VERSION ""

NS_ :

BS_:

BU_: ACCL BGW BLE DBPC DCFL DCFR DCRL DCRR DDP DSM ECPM FBCM FFL FLDC FRDC HLL HLR HUD IHUB LGL PBPC PDP PSM RBCM RCLL RCLR RLDC RLDP RLSM RRDC RRDP RRSM SCAM TOOL IPC u d t

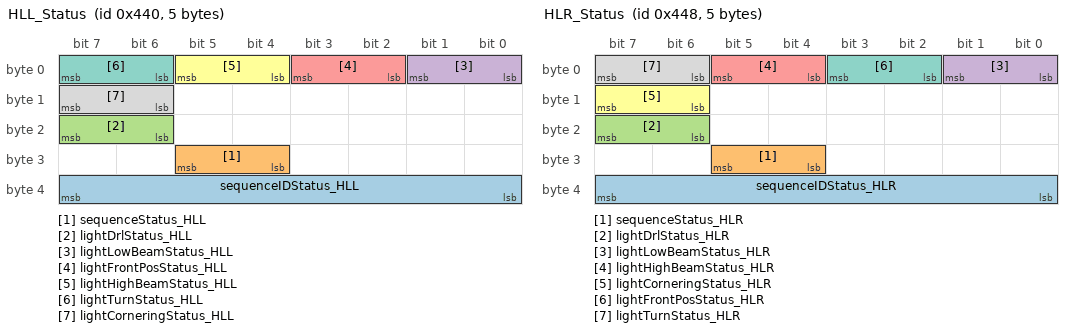
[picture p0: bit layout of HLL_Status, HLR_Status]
BO_ 1088 HLL_Status: 5 HLL
 SG_ sequenceIDStatus_HLL : 39|8@0+ (1,0) [0|254] "" BGW
 SG_ sequenceStatus_HLL : 29|2@0+ (1,0) [0|14] "" BGW
 SG_ lightDrlStatus_HLL : 23|2@0+ (1,0) [0|2] "" HUD,BGW,FBCM
 SG_ lightLowBeamStatus_HLL : 1|2@0+ (1,0) [0|2] "" HUD,FBCM,BGW
 SG_ lightFrontPosStatus_HLL : 3|2@0+ (1,0) [0|2] "" HUD,FBCM,BGW
 SG_ lightHighBeamStatus_HLL : 5|2@0+ (1,0) [0|2] "" HUD,FBCM,BGW
 SG_ lightTurnStatus_HLL : 7|2@0+ (1,0) [0|2] "" HUD,FBCM,BGW
 SG_ lightCorneringStatus_HLL : 15|2@0+ (1,0) [0|2] "" HUD,FBCM,BGW

BO_ 1096 HLR_Status: 5 HLR
 SG_ sequenceIDStatus_HLR : 39|8@0+ (1,0) [0|254] "" BGW
 SG_ sequenceStatus_HLR : 29|2@0+ (1,0) [0|14] "" BGW
 SG_ lightDrlStatus_HLR : 23|2@0+ (1,0) [0|2] "" HUD,BGW,FBCM
 SG_ lightLowBeamStatus_HLR : 1|2@0+ (1,0) [0|2] "" HUD,FBCM,BGW
 SG_ lightHighBeamStatus_HLR : 5|2@0+ (1,0) [0|2] "" HUD,FBCM,BGW
 SG_ lightCorneringStatus_HLR : 15|2@0+ (1,0) [0|2] "" HUD,FBCM,BGW
 SG_ lightFrontPosStatus_HLR : 3|2@0+ (1,0) [0|2] "" HUD,FBCM,BGW
 SG_ lightTurnStatus_HLR : 7|2@0+ (1,0) [0|2] "" HUD,FBCM,BGW

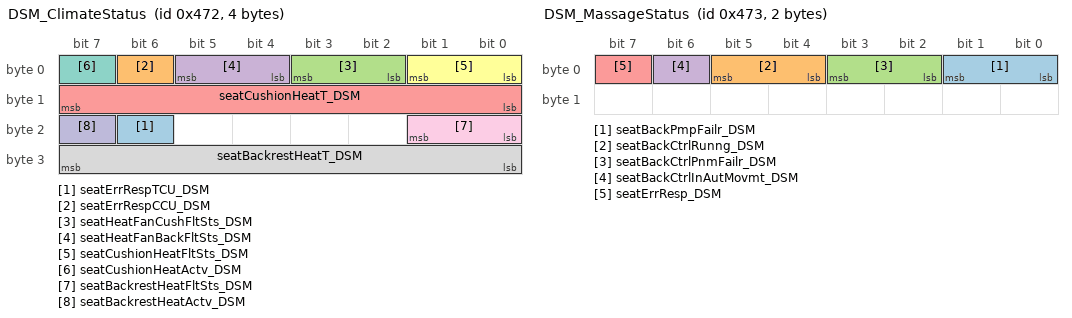
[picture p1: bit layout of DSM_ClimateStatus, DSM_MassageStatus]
BO_ 1138 DSM_ClimateStatus: 4 DSM
 SG_ seatErrRespTCU_DSM : 22|1@0+ (1,0) [0|1] "" BGW
 SG_ seatErrRespCCU_DSM : 6|1@0+ (1,0) [0|1] "" BGW
 SG_ seatHeatFanCushFltSts_DSM : 3|2@0+ (1,0) [0|2] "" BGW
 SG_ seatHeatFanBackFltSts_DSM : 5|2@0+ (1,0) [0|2] "" BGW
 SG_ seatCushionHeatT_DSM : 15|8@0+ (0.5,-40) [0|87] "degC" BGW
 SG_ seatCushionHeatFltSts_DSM : 1|2@0+ (1,0) [0|2] "" BGW
 SG_ seatCushionHeatActv_DSM : 7|1@0+ (1,0) [0|1] "" BGW
 SG_ seatBackrestHeatT_DSM : 31|8@0+ (0.5,-40) [0|87] "degC" BGW
 SG_ seatBackrestHeatFltSts_DSM : 17|2@0+ (1,0) [0|2] "" BGW
 SG_ seatBackrestHeatActv_DSM : 23|1@0+ (1,0) [0|1] "" BGW

BO_ 1139 DSM_MassageStatus: 2 DSM
 SG_ seatBackPmpFailr_DSM : 1|2@0+ (1,0) [0|2] "" BGW
 SG_ seatBackCtrlRunng_DSM : 5|2@0+ (1,0) [0|3] "" BGW
 SG_ seatBackCtrlPnmFailr_DSM : 3|2@0+ (1,0) [0|2] "" BGW
 SG_ seatBackCtrlInAutMovmt_DSM : 6|1@0+ (1,0) [0|1] "" BGW
 SG_ seatErrResp_DSM : 7|1@0+ (1,0) [0|1] "" BGW

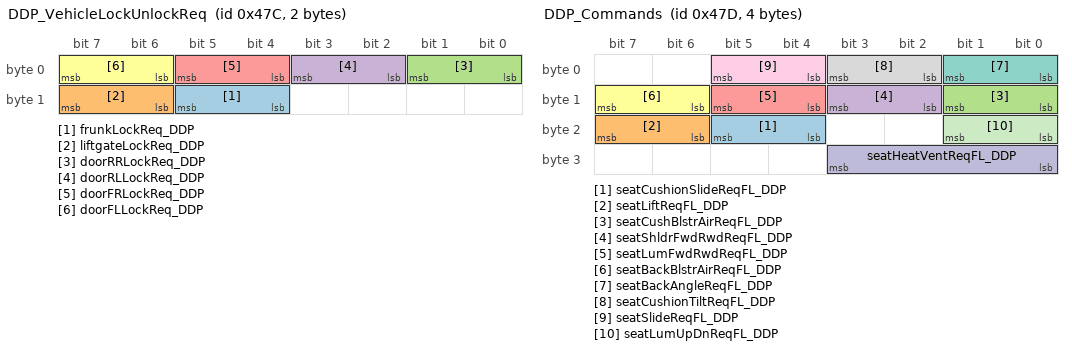
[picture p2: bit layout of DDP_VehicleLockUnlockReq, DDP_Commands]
BO_ 1148 DDP_VehicleLockUnlockReq: 2 DDP
 SG_ frunkLockReq_DDP : 13|2@0+ (1,0) [0|2] "" FBCM
 SG_ liftgateLockReq_DDP : 15|2@0+ (1,0) [0|2] "" FBCM
 SG_ doorRRLockReq_DDP : 1|2@0+ (1,0) [0|2] "" FBCM
 SG_ doorRLLockReq_DDP : 3|2@0+ (1,0) [0|2] "" FBCM
 SG_ doorFRLockReq_DDP : 5|2@0+ (1,0) [0|2] "" FBCM
 SG_ doorFLLockReq_DDP : 7|2@0+ (1,0) [0|2] "" FBCM

BO_ 1149 DDP_Commands: 4 DDP
 SG_ seatCushionSlideReqFL_DDP : 21|2@0+ (1,0) [0|2] "" BGW
 SG_ seatLiftReqFL_DDP : 23|2@0+ (1,0) [0|2] "" BGW
 SG_ seatCushBlstrAirReqFL_DDP : 9|2@0+ (1,0) [0|2] "" BGW
 SG_ seatShldrFwdRwdReqFL_DDP : 11|2@0+ (1,0) [0|2] "" BGW
 SG_ seatLumFwdRwdReqFL_DDP : 13|2@0+ (1,0) [0|2] "" BGW
 SG_ seatBackBlstrAirReqFL_DDP : 15|2@0+ (1,0) [0|2] "" BGW
 SG_ seatBackAngleReqFL_DDP : 1|2@0+ (1,0) [0|2] "" BGW
 SG_ seatCushionTiltReqFL_DDP : 3|2@0+ (1,0) [0|2] "" BGW
 SG_ seatSlideReqFL_DDP : 5|2@0+ (1,0) [0|2] "" BGW
 SG_ seatHeatVentReqFL_DDP : 27|4@0+ (1,0) [0|8] "" BGW
 SG_ seatLumUpDnReqFL_DDP : 17|2@0+ (1,0) [0|2] "" BGW

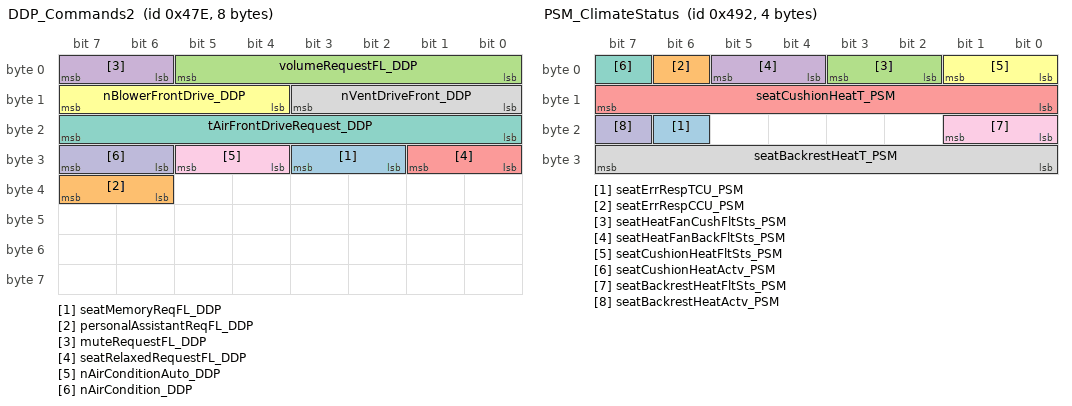
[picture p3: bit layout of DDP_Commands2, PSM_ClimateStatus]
BO_ 1150 DDP_Commands2: 8 DDP
 SG_ seatMemoryReqFL_DDP : 27|2@0+ (1,0) [0|2] "" BGW
 SG_ personalAssistantReqFL_DDP : 39|2@0+ (1,0) [0|2] "" BGW
 SG_ volumeRequestFL_DDP : 5|6@0+ (1,0) [0|45] "" BGW
 SG_ muteRequestFL_DDP : 7|2@0+ (1,0) [0|2] "" BGW
 SG_ seatRelaxedRequestFL_DDP : 25|2@0+ (1,0) [0|2] "" BGW
 SG_ nBlowerFrontDrive_DDP : 15|4@0+ (1,0) [0|14] "" BGW
 SG_ tAirFrontDriveRequest_DDP : 23|8@0+ (0.1,15.5) [15.5|32.5] "C" BGW
 SG_ nVentDriveFront_DDP : 11|4@0+ (1,0) [0|12] "" BGW
 SG_ nAirConditionAuto_DDP : 29|2@0+ (1,0) [0|2] "" BGW
 SG_ nAirCondition_DDP : 31|2@0+ (1,0) [0|2] "" BGW

BO_ 1170 PSM_ClimateStatus: 4 PSM
 SG_ seatErrRespTCU_PSM : 22|1@0+ (1,0) [0|1] "" BGW
 SG_ seatErrRespCCU_PSM : 6|1@0+ (1,0) [0|1] "" BGW
 SG_ seatHeatFanCushFltSts_PSM : 3|2@0+ (1,0) [0|2] "" BGW
 SG_ seatHeatFanBackFltSts_PSM : 5|2@0+ (1,0) [0|2] "" BGW
 SG_ seatCushionHeatT_PSM : 15|8@0+ (0.5,-40) [0|87] "degC" BGW
 SG_ seatCushionHeatFltSts_PSM : 1|2@0+ (1,0) [0|2] "" BGW
 SG_ seatCushionHeatActv_PSM : 7|1@0+ (1,0) [0|1] "" BGW
 SG_ seatBackrestHeatT_PSM : 31|8@0+ (0.5,-40) [0|87] "degC" BGW
 SG_ seatBackrestHeatFltSts_PSM : 17|2@0+ (1,0) [0|2] "" BGW
 SG_ seatBackrestHeatActv_PSM : 23|1@0+ (1,0) [0|1] "" BGW

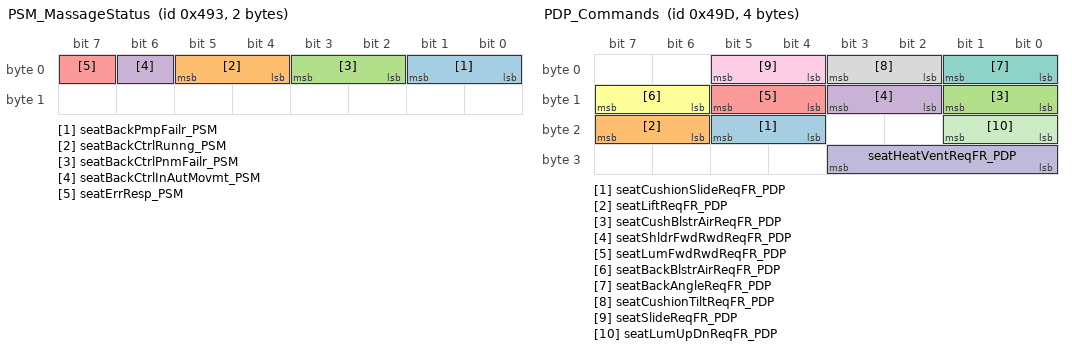
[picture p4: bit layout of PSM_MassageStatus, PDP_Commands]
BO_ 1171 PSM_MassageStatus: 2 PSM
 SG_ seatBackPmpFailr_PSM : 1|2@0+ (1,0) [0|2] "" BGW
 SG_ seatBackCtrlRunng_PSM : 5|2@0+ (1,0) [0|3] "" BGW
 SG_ seatBackCtrlPnmFailr_PSM : 3|2@0+ (1,0) [0|2] "" BGW
 SG_ seatBackCtrlInAutMovmt_PSM : 6|1@0+ (1,0) [0|1] "" BGW
 SG_ seatErrResp_PSM : 7|1@0+ (1,0) [0|1] "" BGW

BO_ 1176 PDP_VehicleLockUnlockReq: 1 PDP
 SG_ doorFRLockReq_PDP : 7|2@0+ (1,0) [0|2] "" FBCM

BO_ 1181 PDP_Commands: 4 PDP
 SG_ seatCushionSlideReqFR_PDP : 21|2@0+ (1,0) [0|2] "" BGW
 SG_ seatLiftReqFR_PDP : 23|2@0+ (1,0) [0|2] "" BGW
 SG_ seatCushBlstrAirReqFR_PDP : 9|2@0+ (1,0) [0|2] "" BGW
 SG_ seatShldrFwdRwdReqFR_PDP : 11|2@0+ (1,0) [0|2] "" BGW
 SG_ seatLumFwdRwdReqFR_PDP : 13|2@0+ (1,0) [0|2] "" BGW
 SG_ seatBackBlstrAirReqFR_PDP : 15|2@0+ (1,0) [0|2] "" BGW
 SG_ seatBackAngleReqFR_PDP : 1|2@0+ (1,0) [0|2] "" BGW
 SG_ seatCushionTiltReqFR_PDP : 3|2@0+ (1,0) [0|2] "" BGW
 SG_ seatSlideReqFR_PDP : 5|2@0+ (1,0) [0|2] "" BGW
 SG_ seatHeatVentReqFR_PDP : 27|4@0+ (1,0) [0|8] "" BGW
 SG_ seatLumUpDnReqFR_PDP : 17|2@0+ (1,0) [0|2] "" BGW

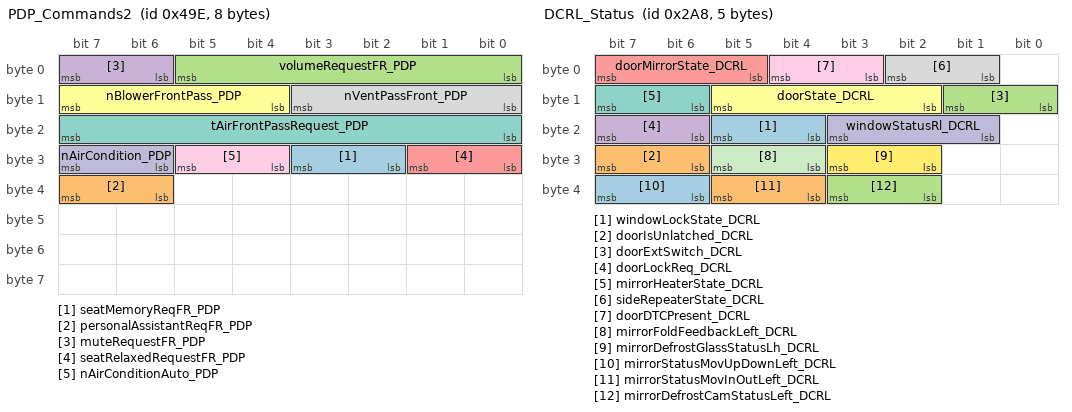
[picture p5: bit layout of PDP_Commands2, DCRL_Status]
BO_ 1182 PDP_Commands2: 8 PDP
 SG_ seatMemoryReqFR_PDP : 27|2@0+ (1,0) [0|2] "" BGW
 SG_ personalAssistantReqFR_PDP : 39|2@0+ (1,0) [0|2] "" BGW
 SG_ volumeRequestFR_PDP : 5|6@0+ (1,0) [0|45] "" BGW
 SG_ muteRequestFR_PDP : 7|2@0+ (1,0) [0|2] "" BGW
 SG_ seatRelaxedRequestFR_PDP : 25|2@0+ (1,0) [0|2] "" BGW
 SG_ nBlowerFrontPass_PDP : 15|4@0+ (1,0) [0|14] "" BGW
 SG_ tAirFrontPassRequest_PDP : 23|8@0+ (0.1,15.5) [15.5|32.5] "C" BGW
 SG_ nVentPassFront_PDP : 11|4@0+ (1,0) [0|12] "" BGW
 SG_ nAirConditionAuto_PDP : 29|2@0+ (1,0) [0|2] "" BGW
 SG_ nAirCondition_PDP : 31|2@0+ (1,0) [0|2] "" BGW

BO_ 680 DCRL_Status: 5 DCRL
 SG_ windowLockState_DCRL : 21|2@0+ (1,0) [0|2] "" BGW,DCFL,DCFR,DCRL,DCRR
 SG_ doorIsUnlatched_DCRL : 31|2@0+ (1,0) [0|2] "" FBCM,BGW,DCFR,DCRR,DCFL,IHUB
 SG_ doorExtSwitch_DCRL : 9|2@0+ (1,0) [0|2] "" BGW
 SG_ doorLockReq_DCRL : 23|2@0+ (1,0) [0|2] "" BGW
 SG_ doorMirrorState_DCRL : 7|3@0+ (1,0) [0|6] "" ECPM,BGW
 SG_ doorState_DCRL : 13|4@0+ (1,0) [0|6] "" ECPM,RBCM,FBCM,BGW
 SG_ mirrorHeaterState_DCRL : 15|2@0+ (1,0) [0|2] "" ECPM,BGW
 SG_ sideRepeaterState_DCRL : 2|2@0+ (1,0) [0|2] "" BGW,RBCM
 SG_ doorDTCPresent_DCRL : 4|2@0+ (1,0) [0|2] "" BGW
 SG_ windowStatusRl_DCRL : 19|3@0+ (1,0) [0|6] "" BGW
 SG_ mirrorFoldFeedbackLeft_DCRL : 29|2@0+ (1,0) [0|2] "" BGW
 SG_ mirrorDefrostGlassStatusLh_DCRL : 27|2@0+ (1,0) [0|2] "" BGW
 SG_ mirrorStatusMovUpDownLeft_DCRL : 39|2@0+ (1,0) [0|2] "" BGW
 SG_ mirrorStatusMovInOutLeft_DCRL : 37|2@0+ (1,0) [0|2] "" BGW
 SG_ mirrorDefrostCamStatusLeft_DCRL : 35|2@0+ (1,0) [0|2] "" BGW

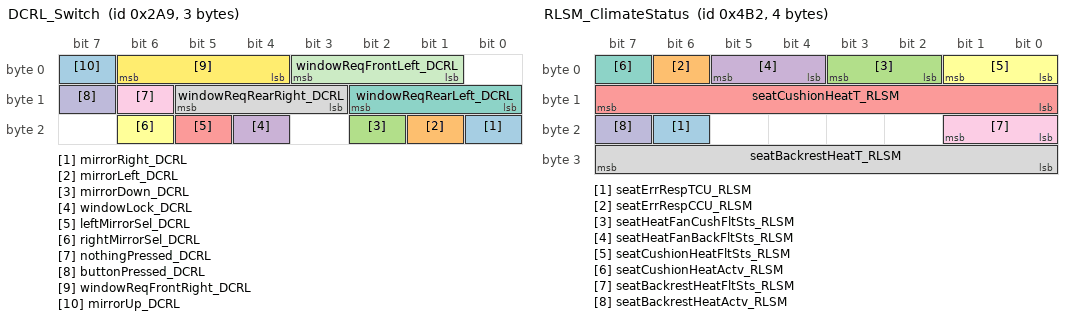
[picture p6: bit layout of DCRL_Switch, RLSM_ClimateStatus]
BO_ 681 DCRL_Switch: 3 DCRL
 SG_ mirrorRight_DCRL : 16|1@0+ (1,0) [0|1] "" DCRR,DCRL,DCFR,DCFL,TOOL
 SG_ mirrorLeft_DCRL : 17|1@0+ (1,0) [0|1] "" DCRR,DCRL,DCFR,DCFL,TOOL
 SG_ mirrorDown_DCRL : 18|1@0+ (1,0) [0|1] "" DCRR,DCRL,DCFR,DCFL,TOOL
 SG_ windowLock_DCRL : 20|1@0+ (1,0) [0|1] "" DCRR,DCRL,DCFR,DCFL,TOOL
 SG_ leftMirrorSel_DCRL : 21|1@0+ (1,0) [0|1] "" DCRR,DCRL,DCFR,DCFL,TOOL
 SG_ rightMirrorSel_DCRL : 22|1@0+ (1,0) [0|1] "" DCRR,DCRL,DCFR,DCFL,TOOL
 SG_ windowReqRearLeft_DCRL : 10|3@0+ (1,0) [0|6] "" DCFR,DCRR,DCFL,DCRL,BGW,TOOL
 SG_ windowReqRearRight_DCRL : 13|3@0+ (1,0) [0|6] "" DCRL,DCFR,DCFL,DCRR,BGW,TOOL
 SG_ nothingPressed_DCRL : 14|1@0+ (1,0) [0|1] "" DCFR,DCRL,DCRR,DCFL,TOOL
 SG_ buttonPressed_DCRL : 15|1@0+ (1,0) [0|1] "" DCFR,DCRL,DCRR,DCFL,TOOL
 SG_ windowReqFrontLeft_DCRL : 3|3@0+ (1,0) [0|6] "" DCFR,DCRL,DCRR,DCFL,BGW
 SG_ windowReqFrontRight_DCRL : 6|3@0+ (1,0) [0|6] "" DCFR,DCRL,DCRR,DCFL,BGW,TOOL
 SG_ mirrorUp_DCRL : 7|1@0+ (1,0) [0|1] "" DCRR,DCRL,DCFR,DCFL,TOOL

BO_ 1202 RLSM_ClimateStatus: 4 RLSM
 SG_ seatErrRespTCU_RLSM : 22|1@0+ (1,0) [0|1] "" BGW
 SG_ seatErrRespCCU_RLSM : 6|1@0+ (1,0) [0|1] "" BGW
 SG_ seatHeatFanCushFltSts_RLSM : 3|2@0+ (1,0) [0|2] "" BGW
 SG_ seatHeatFanBackFltSts_RLSM : 5|2@0+ (1,0) [0|2] "" BGW
 SG_ seatCushionHeatT_RLSM : 15|8@0+ (0.5,-40) [0|87] "degC" BGW
 SG_ seatCushionHeatFltSts_RLSM : 1|2@0+ (1,0) [0|2] "" BGW
 SG_ seatCushionHeatActv_RLSM : 7|1@0+ (1,0) [0|1] "" BGW
 SG_ seatBackrestHeatT_RLSM : 31|8@0+ (0.5,-40) [0|87] "degC" BGW
 SG_ seatBackrestHeatFltSts_RLSM : 17|2@0+ (1,0) [0|2] "" BGW
 SG_ seatBackrestHeatActv_RLSM : 23|1@0+ (1,0) [0|1] "" BGW

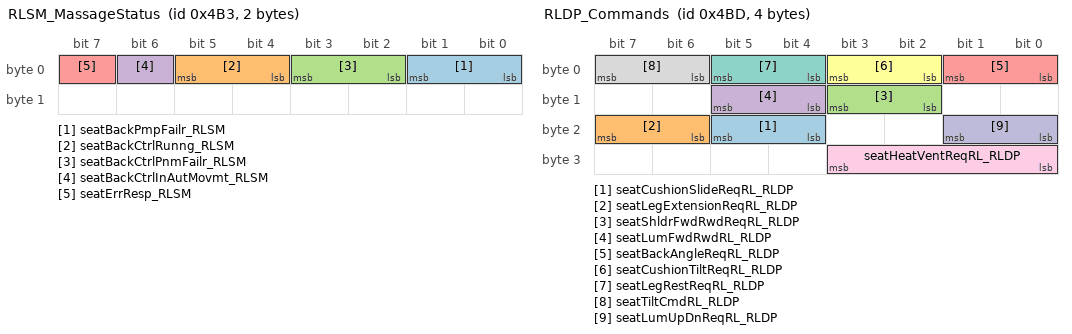
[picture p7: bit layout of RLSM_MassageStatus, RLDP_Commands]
BO_ 1203 RLSM_MassageStatus: 2 RLSM
 SG_ seatBackPmpFailr_RLSM : 1|2@0+ (1,0) [0|2] "" BGW
 SG_ seatBackCtrlRunng_RLSM : 5|2@0+ (1,0) [0|3] "" BGW
 SG_ seatBackCtrlPnmFailr_RLSM : 3|2@0+ (1,0) [0|2] "" BGW
 SG_ seatBackCtrlInAutMovmt_RLSM : 6|1@0+ (1,0) [0|1] "" BGW
 SG_ seatErrResp_RLSM : 7|1@0+ (1,0) [0|1] "" BGW

BO_ 1208 RLDP_VehicleLockUnlockReq: 1 RLDP
 SG_ doorRLLockReq_RLDP : 7|2@0+ (1,0) [0|2] "" FBCM

BO_ 1213 RLDP_Commands: 4 RLDP
 SG_ seatCushionSlideReqRL_RLDP : 21|2@0+ (1,0) [0|2] "" BGW
 SG_ seatLegExtensionReqRL_RLDP : 23|2@0+ (1,0) [0|2] "" BGW
 SG_ seatShldrFwdRwdReqRL_RLDP : 11|2@0+ (1,0) [0|2] "" BGW
 SG_ seatLumFwdRwdRL_RLDP : 13|2@0+ (1,0) [0|2] "" BGW
 SG_ seatBackAngleReqRL_RLDP : 1|2@0+ (1,0) [0|2] "" BGW
 SG_ seatCushionTiltReqRL_RLDP : 3|2@0+ (1,0) [0|2] "" BGW
 SG_ seatLegRestReqRL_RLDP : 5|2@0+ (1,0) [0|2] "" BGW
 SG_ seatTiltCmdRL_RLDP : 7|2@0+ (1,0) [0|2] "" BGW
 SG_ seatHeatVentReqRL_RLDP : 27|4@0+ (1,0) [0|8] "" BGW
 SG_ seatLumUpDnReqRL_RLDP : 17|2@0+ (1,0) [0|2] "" BGW

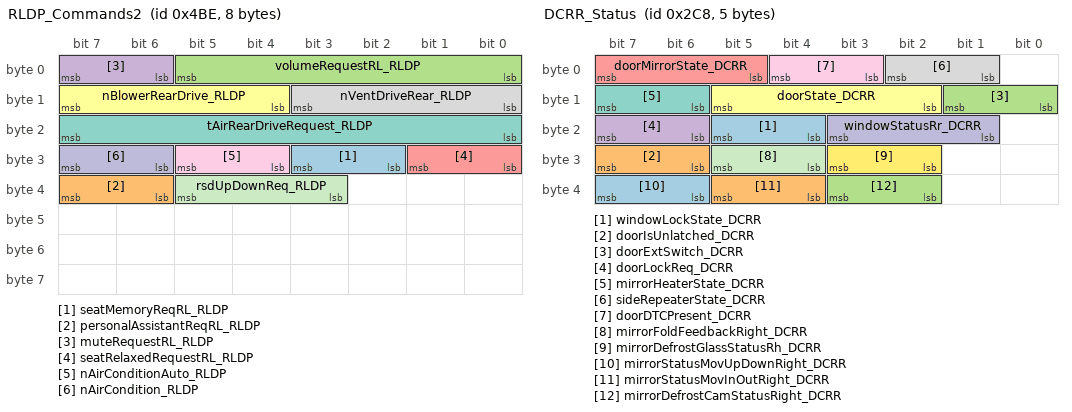
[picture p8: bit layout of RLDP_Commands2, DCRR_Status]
BO_ 1214 RLDP_Commands2: 8 RLDP
 SG_ seatMemoryReqRL_RLDP : 27|2@0+ (1,0) [0|2] "" BGW
 SG_ personalAssistantReqRL_RLDP : 39|2@0+ (1,0) [0|2] "" BGW
 SG_ volumeRequestRL_RLDP : 5|6@0+ (1,0) [0|45] "" BGW
 SG_ muteRequestRL_RLDP : 7|2@0+ (1,0) [0|2] "" BGW
 SG_ seatRelaxedRequestRL_RLDP : 25|2@0+ (1,0) [0|2] "" BGW
 SG_ nBlowerRearDrive_RLDP : 15|4@0+ (1,0) [0|14] "" BGW
 SG_ tAirRearDriveRequest_RLDP : 23|8@0+ (0.1,15.5) [15.5|32.5] "C" BGW
 SG_ nVentDriveRear_RLDP : 11|4@0+ (1,0) [0|12] "" BGW
 SG_ nAirConditionAuto_RLDP : 29|2@0+ (1,0) [0|2] "" BGW
 SG_ nAirCondition_RLDP : 31|2@0+ (1,0) [0|2] "" BGW
 SG_ rsdUpDownReq_RLDP : 37|3@0+ (1,0) [0|6] "" BGW

BO_ 712 DCRR_Status: 5 DCRR
 SG_ windowLockState_DCRR : 21|2@0+ (1,0) [0|2] "" BGW,DCFL,DCFR,DCRL,DCRR
 SG_ doorIsUnlatched_DCRR : 31|2@0+ (1,0) [0|2] "" FBCM,BGW,DCFR,DCFL,DCRL,IHUB
 SG_ doorExtSwitch_DCRR : 9|2@0+ (1,0) [0|2] "" BGW
 SG_ doorLockReq_DCRR : 23|2@0+ (1,0) [0|2] "" BGW
 SG_ doorMirrorState_DCRR : 7|3@0+ (1,0) [0|6] "" ECPM,BGW
 SG_ doorState_DCRR : 13|4@0+ (1,0) [0|6] "" ECPM,RBCM,FBCM,BGW
 SG_ mirrorHeaterState_DCRR : 15|2@0+ (1,0) [0|2] "" ECPM,BGW
 SG_ sideRepeaterState_DCRR : 2|2@0+ (1,0) [0|2] "" BGW,RBCM
 SG_ doorDTCPresent_DCRR : 4|2@0+ (1,0) [0|2] "" BGW
 SG_ windowStatusRr_DCRR : 19|3@0+ (1,0) [0|6] "" BGW
 SG_ mirrorFoldFeedbackRight_DCRR : 29|2@0+ (1,0) [0|2] "" BGW
 SG_ mirrorDefrostGlassStatusRh_DCRR : 27|2@0+ (1,0) [0|2] "" BGW
 SG_ mirrorStatusMovUpDownRight_DCRR : 39|2@0+ (1,0) [0|2] "" BGW
 SG_ mirrorStatusMovInOutRight_DCRR : 37|2@0+ (1,0) [0|2] "" BGW
 SG_ mirrorDefrostCamStatusRight_DCRR : 35|2@0+ (1,0) [0|2] "" BGW

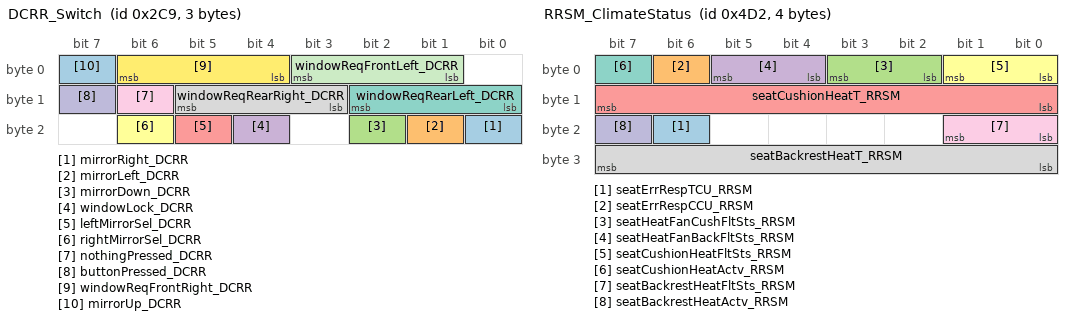
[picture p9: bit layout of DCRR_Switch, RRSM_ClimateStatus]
BO_ 713 DCRR_Switch: 3 DCRR
 SG_ mirrorRight_DCRR : 16|1@0+ (1,0) [0|1] "" DCRR,DCRL,DCFR,DCFL,TOOL
 SG_ mirrorLeft_DCRR : 17|1@0+ (1,0) [0|1] "" DCRR,DCRL,DCFR,DCFL,TOOL
 SG_ mirrorDown_DCRR : 18|1@0+ (1,0) [0|1] "" DCRR,DCRL,DCFR,DCFL,TOOL
 SG_ windowLock_DCRR : 20|1@0+ (1,0) [0|1] "" DCRR,DCRL,DCFR,DCFL,TOOL
 SG_ leftMirrorSel_DCRR : 21|1@0+ (1,0) [0|1] "" DCRR,DCRL,DCFR,DCFL,TOOL
 SG_ rightMirrorSel_DCRR : 22|1@0+ (1,0) [0|1] "" DCRR,DCRL,DCFR,DCFL,TOOL
 SG_ windowReqRearLeft_DCRR : 10|3@0+ (1,0) [0|6] "" DCFR,DCRR,DCFL,DCRL
 SG_ windowReqRearRight_DCRR : 13|3@0+ (1,0) [0|6] "" DCRL,DCFR,DCFL,DCRR,BGW
 SG_ nothingPressed_DCRR : 14|1@0+ (1,0) [0|1] "" DCFR,DCRL,DCRR,DCFL,TOOL
 SG_ buttonPressed_DCRR : 15|1@0+ (1,0) [0|1] "" DCFR,DCRL,DCRR,DCFL,TOOL
 SG_ windowReqFrontLeft_DCRR : 3|3@0+ (1,0) [0|6] "" DCFR,DCRL,DCRR,DCFL,BGW
 SG_ windowReqFrontRight_DCRR : 6|3@0+ (1,0) [0|6] "" DCFR,DCRL,DCRR,DCFL,BGW,TOOL
 SG_ mirrorUp_DCRR : 7|1@0+ (1,0) [0|1] "" DCRR,DCRL,DCFR,DCFL,TOOL

BO_ 1234 RRSM_ClimateStatus: 4 RRSM
 SG_ seatErrRespTCU_RRSM : 22|1@0+ (1,0) [0|1] "" BGW
 SG_ seatErrRespCCU_RRSM : 6|1@0+ (1,0) [0|1] "" BGW
 SG_ seatHeatFanCushFltSts_RRSM : 3|2@0+ (1,0) [0|2] "" BGW
 SG_ seatHeatFanBackFltSts_RRSM : 5|2@0+ (1,0) [0|2] "" BGW
 SG_ seatCushionHeatT_RRSM : 15|8@0+ (0.5,-40) [0|87] "degC" BGW
 SG_ seatCushionHeatFltSts_RRSM : 1|2@0+ (1,0) [0|2] "" BGW
 SG_ seatCushionHeatActv_RRSM : 7|1@0+ (1,0) [0|1] "" BGW
 SG_ seatBackrestHeatT_RRSM : 31|8@0+ (0.5,-40) [0|87] "degC" BGW
 SG_ seatBackrestHeatFltSts_RRSM : 17|2@0+ (1,0) [0|2] "" BGW
 SG_ seatBackrestHeatActv_RRSM : 23|1@0+ (1,0) [0|1] "" BGW

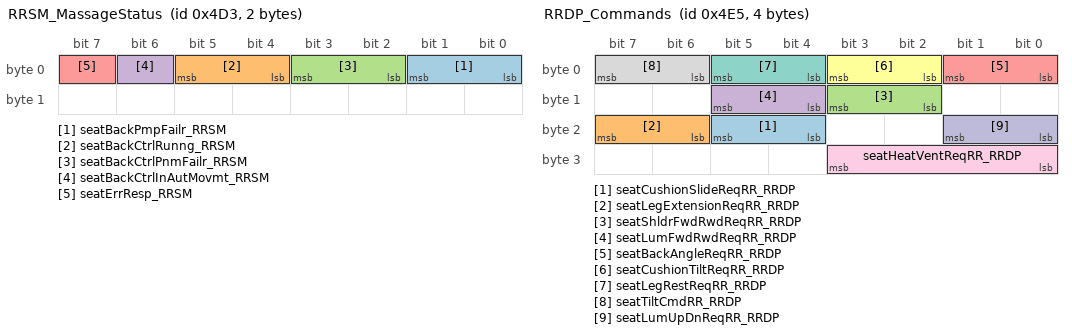
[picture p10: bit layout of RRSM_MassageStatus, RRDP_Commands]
BO_ 1235 RRSM_MassageStatus: 2 RRSM
 SG_ seatBackPmpFailr_RRSM : 1|2@0+ (1,0) [0|2] "" BGW
 SG_ seatBackCtrlRunng_RRSM : 5|2@0+ (1,0) [0|3] "" BGW
 SG_ seatBackCtrlPnmFailr_RRSM : 3|2@0+ (1,0) [0|2] "" BGW
 SG_ seatBackCtrlInAutMovmt_RRSM : 6|1@0+ (1,0) [0|1] "" BGW
 SG_ seatErrResp_RRSM : 7|1@0+ (1,0) [0|1] "" BGW

BO_ 1248 RRDP_VehicleLockUnlockReq: 1 RRDP
 SG_ doorRRLockReq_RRDP : 7|2@0+ (1,0) [0|2] "" FBCM

BO_ 1253 RRDP_Commands: 4 RRDP
 SG_ seatCushionSlideReqRR_RRDP : 21|2@0+ (1,0) [0|2] "" BGW
 SG_ seatLegExtensionReqRR_RRDP : 23|2@0+ (1,0) [0|2] "" BGW
 SG_ seatShldrFwdRwdReqRR_RRDP : 11|2@0+ (1,0) [0|2] "" BGW
 SG_ seatLumFwdRwdReqRR_RRDP : 13|2@0+ (1,0) [0|2] "" BGW
 SG_ seatBackAngleReqRR_RRDP : 1|2@0+ (1,0) [0|2] "" BGW
 SG_ seatCushionTiltReqRR_RRDP : 3|2@0+ (1,0) [0|2] "" BGW
 SG_ seatLegRestReqRR_RRDP : 5|2@0+ (1,0) [0|2] "" BGW
 SG_ seatTiltCmdRR_RRDP : 7|2@0+ (1,0) [0|2] "" BGW
 SG_ seatHeatVentReqRR_RRDP : 27|4@0+ (1,0) [0|8] "" BGW
 SG_ seatLumUpDnReqRR_RRDP : 17|2@0+ (1,0) [0|2] "" BGW

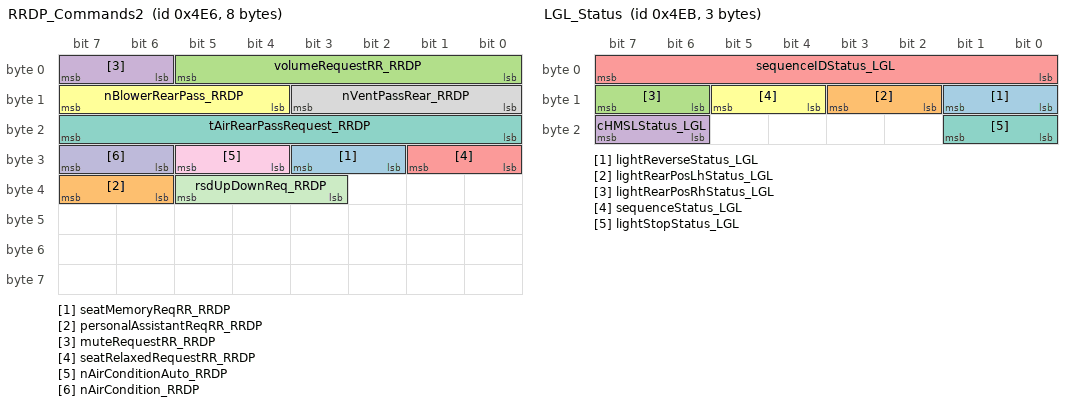
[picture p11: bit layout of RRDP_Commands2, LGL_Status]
BO_ 1254 RRDP_Commands2: 8 RRDP
 SG_ seatMemoryReqRR_RRDP : 27|2@0+ (1,0) [0|2] "" BGW
 SG_ personalAssistantReqRR_RRDP : 39|2@0+ (1,0) [0|2] "" BGW
 SG_ volumeRequestRR_RRDP : 5|6@0+ (1,0) [0|45] "" BGW
 SG_ muteRequestRR_RRDP : 7|2@0+ (1,0) [0|2] "" BGW
 SG_ seatRelaxedRequestRR_RRDP : 25|2@0+ (1,0) [0|2] "" BGW
 SG_ nBlowerRearPass_RRDP : 15|4@0+ (1,0) [0|14] "" BGW
 SG_ tAirRearPassRequest_RRDP : 23|8@0+ (0.1,15.5) [15.5|32.5] "C" BGW
 SG_ nVentPassRear_RRDP : 11|4@0+ (1,0) [0|12] "" BGW
 SG_ nAirConditionAuto_RRDP : 29|2@0+ (1,0) [0|2] "" BGW
 SG_ nAirCondition_RRDP : 31|2@0+ (1,0) [0|2] "" BGW
 SG_ rsdUpDownReq_RRDP : 37|3@0+ (1,0) [0|6] "" BGW

BO_ 1259 LGL_Status: 3 LGL
 SG_ lightReverseStatus_LGL : 9|2@0+ (1,0) [0|2] "" HUD,BGW,FBCM
 SG_ lightRearPosLhStatus_LGL : 11|2@0+ (1,0) [0|2] "" HUD,BGW,FBCM
 SG_ lightRearPosRhStatus_LGL : 15|2@0+ (1,0) [0|2] "" HUD,BGW,FBCM
 SG_ cHMSLStatus_LGL : 23|2@0+ (1,0) [0|2] "" BGW
 SG_ sequenceIDStatus_LGL : 7|8@0+ (1,0) [0|254] "" BGW
 SG_ sequenceStatus_LGL : 13|2@0+ (1,0) [0|14] "" BGW
 SG_ lightStopStatus_LGL : 17|2@0+ (1,0) [0|2] "" HUD,BGW,FBCM

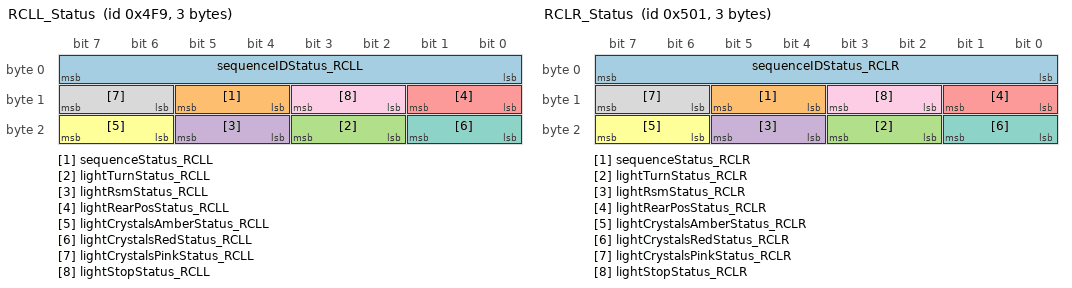
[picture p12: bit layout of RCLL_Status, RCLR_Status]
BO_ 1273 RCLL_Status: 3 RCLL
 SG_ sequenceIDStatus_RCLL : 7|8@0+ (1,0) [0|254] "" BGW
 SG_ sequenceStatus_RCLL : 13|2@0+ (1,0) [0|14] "" BGW
 SG_ lightTurnStatus_RCLL : 19|2@0+ (1,0) [0|2] "" BGW,FBCM
 SG_ lightRsmStatus_RCLL : 21|2@0+ (1,0) [0|2] "" HUD,BGW,FBCM
 SG_ lightRearPosStatus_RCLL : 9|2@0+ (1,0) [0|2] "" HUD,BGW,FBCM
 SG_ lightCrystalsAmberStatus_RCLL : 23|2@0+ (1,0) [0|2] "" HUD,BGW,FBCM
 SG_ lightCrystalsRedStatus_RCLL : 17|2@0+ (1,0) [0|2] "" HUD,BGW,FBCM
 SG_ lightCrystalsPinkStatus_RCLL : 15|2@0+ (1,0) [0|2] "" HUD,BGW,FBCM
 SG_ lightStopStatus_RCLL : 11|2@0+ (1,0) [0|2] "" BGW,FBCM

BO_ 1281 RCLR_Status: 3 RCLR
 SG_ sequenceIDStatus_RCLR : 7|8@0+ (1,0) [0|254] "" BGW
 SG_ sequenceStatus_RCLR : 13|2@0+ (1,0) [0|14] "" BGW
 SG_ lightTurnStatus_RCLR : 19|2@0+ (1,0) [0|2] "" BGW,FBCM
 SG_ lightRsmStatus_RCLR : 21|2@0+ (1,0) [0|2] "" HUD,BGW,FBCM
 SG_ lightRearPosStatus_RCLR : 9|2@0+ (1,0) [0|2] "" HUD,BGW,FBCM
 SG_ lightCrystalsAmberStatus_RCLR : 23|2@0+ (1,0) [0|2] "" HUD,BGW,FBCM
 SG_ lightCrystalsRedStatus_RCLR : 17|2@0+ (1,0) [0|2] "" HUD,BGW,FBCM
 SG_ lightCrystalsPinkStatus_RCLR : 15|2@0+ (1,0) [0|2] "" HUD,BGW,FBCM
 SG_ lightStopStatus_RCLR : 11|2@0+ (1,0) [0|2] "" BGW,FBCM

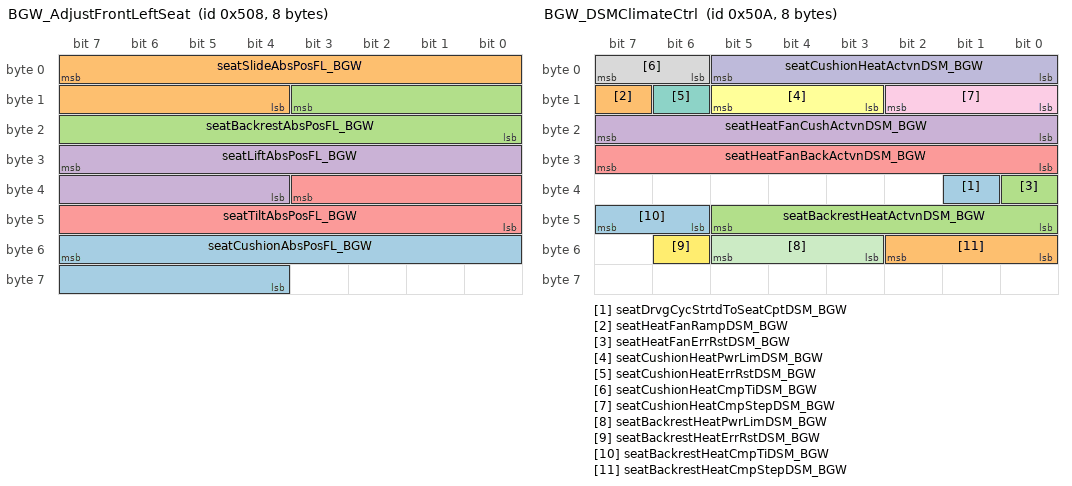
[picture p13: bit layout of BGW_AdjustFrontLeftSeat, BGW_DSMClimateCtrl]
BO_ 1288 BGW_AdjustFrontLeftSeat: 8 BGW
 SG_ seatCushionAbsPosFL_BGW : 55|12@0- (16,0) [-32768|32736] "" DSM
 SG_ seatSlideAbsPosFL_BGW : 7|12@0- (16,0) [-32768|32736] "" DSM
 SG_ seatBackrestAbsPosFL_BGW : 11|12@0- (16,0) [-32768|32736] "" DSM
 SG_ seatLiftAbsPosFL_BGW : 31|12@0- (16,0) [-32768|32736] "" DSM
 SG_ seatTiltAbsPosFL_BGW : 35|12@0- (16,0) [-32768|32736] "" DSM

BO_ 1289 BGW_GoToAbsPositionCushDSM: 2 BGW
 SG_ seatCushionAbsPosDSM_BGW : 7|16@0- (1,0) [-32768|32766] "" DSM

BO_ 1290 BGW_DSMClimateCtrl: 8 BGW
 SG_ seatDrvgCycStrtdToSeatCptDSM_BGW : 33|1@0+ (1,0) [0|1] "" DSM
 SG_ seatHeatFanRampDSM_BGW : 15|1@0+ (1,0) [0|1] "" DSM
 SG_ seatHeatFanErrRstDSM_BGW : 32|1@0+ (1,0) [0|1] "" DSM
 SG_ seatHeatFanCushActvnDSM_BGW : 23|8@0+ (1,0) [0|254] "Rpm" DSM
 SG_ seatHeatFanBackActvnDSM_BGW : 31|8@0+ (1,0) [0|254] "Rpm" DSM
 SG_ seatCushionHeatPwrLimDSM_BGW : 13|3@0+ (1,0) [0|6] "degC" DSM
 SG_ seatCushionHeatErrRstDSM_BGW : 14|1@0+ (1,0) [0|1] "" DSM
 SG_ seatCushionHeatCmpTiDSM_BGW : 7|2@0+ (80,80) [80|240] "s" DSM
 SG_ seatCushionHeatCmpStepDSM_BGW : 10|3@0+ (1,0) [0|6] "degC" DSM
 SG_ seatCushionHeatActvnDSM_BGW : 5|6@0+ (1,19) [19|40] "degC" DSM
 SG_ seatBackrestHeatPwrLimDSM_BGW : 53|3@0+ (1,0) [0|6] "degC" DSM
 SG_ seatBackrestHeatErrRstDSM_BGW : 54|1@0+ (1,0) [0|1] "" DSM
 SG_ seatBackrestHeatCmpTiDSM_BGW : 47|2@0+ (80,80) [80|240] "s" DSM
 SG_ seatBackrestHeatCmpStepDSM_BGW : 50|3@0+ (1,0) [0|6] "degC" DSM
 SG_ seatBackrestHeatActvnDSM_BGW : 45|6@0+ (1,19) [19|40] "degC" DSM

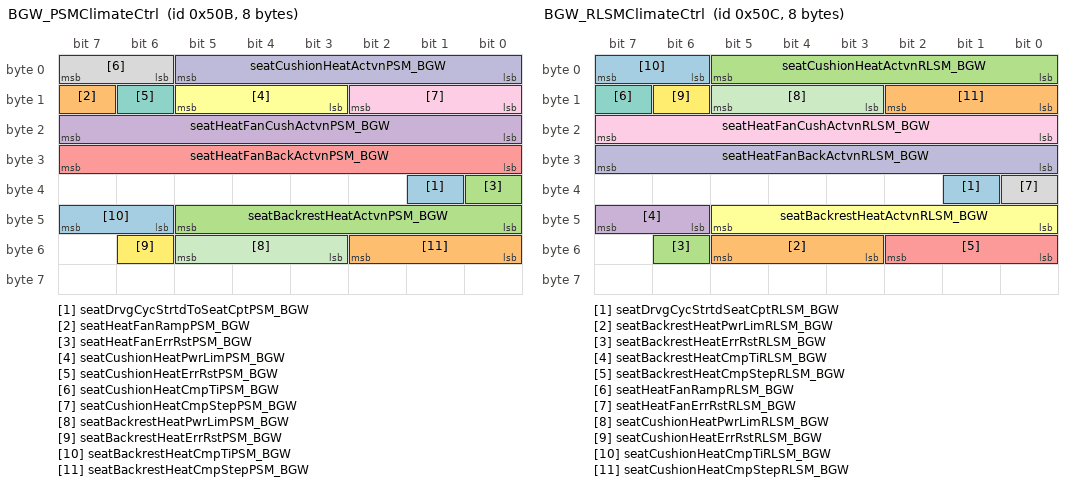
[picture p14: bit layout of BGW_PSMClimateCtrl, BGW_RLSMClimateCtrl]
BO_ 1291 BGW_PSMClimateCtrl: 8 BGW
 SG_ seatDrvgCycStrtdToSeatCptPSM_BGW : 33|1@0+ (1,0) [0|1] "" PSM
 SG_ seatHeatFanRampPSM_BGW : 15|1@0+ (1,0) [0|1] "" PSM
 SG_ seatHeatFanErrRstPSM_BGW : 32|1@0+ (1,0) [0|1] "" PSM
 SG_ seatHeatFanCushActvnPSM_BGW : 23|8@0+ (1,0) [0|254] "Rpm" PSM
 SG_ seatHeatFanBackActvnPSM_BGW : 31|8@0+ (1,0) [0|254] "Rpm" PSM
 SG_ seatCushionHeatPwrLimPSM_BGW : 13|3@0+ (1,0) [0|6] "degC" PSM
 SG_ seatCushionHeatErrRstPSM_BGW : 14|1@0+ (1,0) [0|1] "" PSM
 SG_ seatCushionHeatCmpTiPSM_BGW : 7|2@0+ (80,80) [80|240] "s" PSM
 SG_ seatCushionHeatCmpStepPSM_BGW : 10|3@0+ (1,0) [0|6] "degC" PSM
 SG_ seatCushionHeatActvnPSM_BGW : 5|6@0+ (1,19) [19|40] "degC" PSM
 SG_ seatBackrestHeatPwrLimPSM_BGW : 53|3@0+ (1,0) [0|6] "degC" PSM
 SG_ seatBackrestHeatErrRstPSM_BGW : 54|1@0+ (1,0) [0|1] "" PSM
 SG_ seatBackrestHeatCmpTiPSM_BGW : 47|2@0+ (80,80) [80|240] "s" PSM
 SG_ seatBackrestHeatCmpStepPSM_BGW : 50|3@0+ (1,0) [0|6] "degC" PSM
 SG_ seatBackrestHeatActvnPSM_BGW : 45|6@0+ (1,19) [19|40] "degC" PSM

BO_ 1292 BGW_RLSMClimateCtrl: 8 BGW
 SG_ seatDrvgCycStrtdSeatCptRLSM_BGW : 33|1@0+ (1,0) [0|1] "" RLSM
 SG_ seatBackrestHeatPwrLimRLSM_BGW : 53|3@0+ (1,0) [0|7] "" RLSM
 SG_ seatBackrestHeatErrRstRLSM_BGW : 54|1@0+ (1,0) [0|1] "" RLSM
 SG_ seatBackrestHeatCmpTiRLSM_BGW : 47|2@0+ (80,80) [80|240] "s" RLSM
 SG_ seatBackrestHeatCmpStepRLSM_BGW : 50|3@0+ (1,0) [0|6] "degC" RLSM
 SG_ seatBackrestHeatActvnRLSM_BGW : 45|6@0+ (1,19) [19|40] "degC" RLSM
 SG_ seatHeatFanRampRLSM_BGW : 15|1@0+ (1,0) [0|1] "" RLSM
 SG_ seatHeatFanErrRstRLSM_BGW : 32|1@0+ (1,0) [0|1] "" RLSM
 SG_ seatHeatFanCushActvnRLSM_BGW : 23|8@0+ (1,0) [0|254] "Rpm" RLSM
 SG_ seatHeatFanBackActvnRLSM_BGW : 31|8@0+ (1,0) [0|254] "Rpm" RLSM
 SG_ seatCushionHeatPwrLimRLSM_BGW : 13|3@0+ (1,0) [0|6] "degC" RLSM
 SG_ seatCushionHeatErrRstRLSM_BGW : 14|1@0+ (1,0) [0|1] "" RLSM
 SG_ seatCushionHeatCmpTiRLSM_BGW : 7|2@0+ (80,80) [80|240] "s" RLSM
 SG_ seatCushionHeatCmpStepRLSM_BGW : 10|3@0+ (1,0) [0|6] "degC" RLSM
 SG_ seatCushionHeatActvnRLSM_BGW : 5|6@0+ (1,19) [19|40] "degC" RLSM

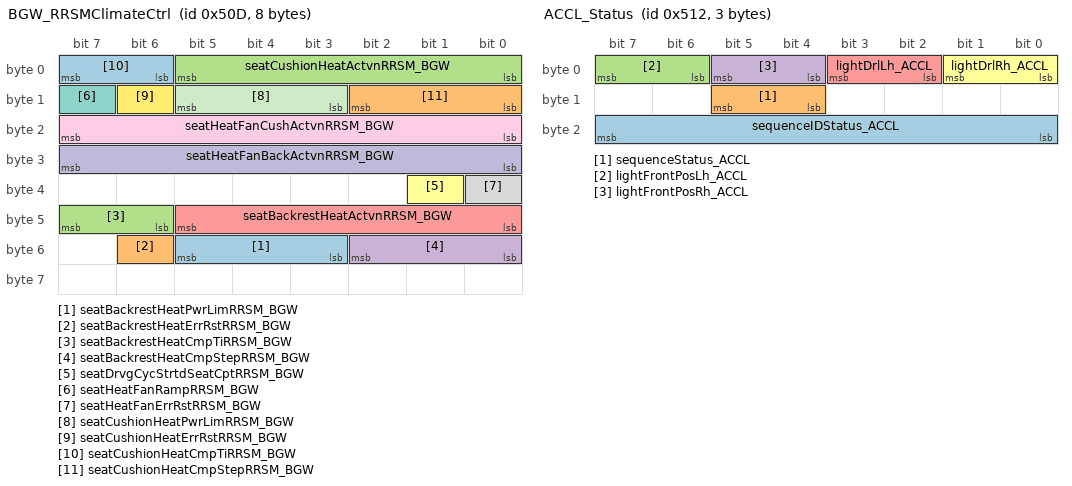
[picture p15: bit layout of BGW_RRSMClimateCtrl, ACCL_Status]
BO_ 1293 BGW_RRSMClimateCtrl: 8 BGW
 SG_ seatBackrestHeatPwrLimRRSM_BGW : 53|3@0+ (1,0) [0|6] "degC" RRSM
 SG_ seatBackrestHeatErrRstRRSM_BGW : 54|1@0+ (1,0) [0|1] "" RRSM
 SG_ seatBackrestHeatCmpTiRRSM_BGW : 47|2@0+ (80,80) [80|240] "s" RRSM
 SG_ seatBackrestHeatCmpStepRRSM_BGW : 50|3@0+ (1,0) [0|6] "degC" RRSM
 SG_ seatBackrestHeatActvnRRSM_BGW : 45|6@0+ (1,19) [19|40] "degC" RRSM
 SG_ seatDrvgCycStrtdSeatCptRRSM_BGW : 33|1@0+ (1,0) [0|1] "" RRSM
 SG_ seatHeatFanRampRRSM_BGW : 15|1@0+ (1,0) [0|1] "" RRSM
 SG_ seatHeatFanErrRstRRSM_BGW : 32|1@0+ (1,0) [0|1] "" RRSM
 SG_ seatHeatFanCushActvnRRSM_BGW : 23|8@0+ (1,0) [0|254] "Rpm" RRSM
 SG_ seatHeatFanBackActvnRRSM_BGW : 31|8@0+ (1,0) [0|254] "Rpm" RRSM
 SG_ seatCushionHeatPwrLimRRSM_BGW : 13|3@0+ (1,0) [0|6] "degC" RRSM
 SG_ seatCushionHeatErrRstRRSM_BGW : 14|1@0+ (1,0) [0|1] "" RRSM
 SG_ seatCushionHeatCmpTiRRSM_BGW : 7|2@0+ (80,80) [80|240] "s" RRSM
 SG_ seatCushionHeatCmpStepRRSM_BGW : 10|3@0+ (1,0) [0|6] "degC" RRSM
 SG_ seatCushionHeatActvnRRSM_BGW : 5|6@0+ (1,19) [19|40] "degC" RRSM

BO_ 1294 BGW_RLSMMassageCtrl: 8 BGW
 SG_ seatShIncRLSM_BGW : 23|1@0+ (1,0) [0|1] "" RLSM
 SG_ seatShDecRLSM_BGW : 24|1@0+ (1,0) [0|1] "" RLSM
 SG_ seatLumUpRLSM_BGW : 5|1@0+ (1,0) [0|1] "" RLSM
 SG_ seatLumIncRLSM_BGW : 7|1@0+ (1,0) [0|1] "" RLSM
 SG_ seatLumDwnRLSM_BGW : 4|1@0+ (1,0) [0|1] "" RLSM
 SG_ seatLumDecRLSM_BGW : 6|1@0+ (1,0) [0|1] "" RLSM
 SG_ seatCushIncRLSM_BGW : 21|1@0+ (1,0) [0|1] "" RLSM
 SG_ seatCushDecRLSM_BGW : 22|1@0+ (1,0) [0|1] "" RLSM
 SG_ seatBackSaveSetToMemRLSM_BGW : 20|2@0+ (1,0) [0|2] "" RLSM
 SG_ seatBackPosnStoreRLSM_BGW : 15|1@0+ (1,0) [0|1] "" RLSM
 SG_ seatBackPosnRestoreRLSM_BGW : 14|1@0+ (1,0) [0|1] "" RLSM
 SG_ seatBackCtrReqInOutEasyRLSM_BGW : 18|1@0+ (1,0) [0|1] "" RLSM
 SG_ seatBackBlstrIncRLSM_BGW : 2|1@0+ (1,0) [0|1] "" RLSM
 SG_ seatBackBlstrDecRLSM_BGW : 3|1@0+ (1,0) [0|1] "" RLSM
 SG_ seatProfPenRLSM_BGW : 11|4@0+ (1,0) [0|14] "" RLSM
 SG_ seatPmpRunRLSM_BGW : 25|1@0+ (1,0) [0|1] "" RLSM
 SG_ seatMemSeatCtrlRLSM_BGW : 13|2@0+ (1,0) [0|3] "" RLSM
 SG_ seatMassgReqOnOffRLSM_BGW : 40|1@0+ (1,0) [0|1] "" RLSM
 SG_ seatMassgReqMassgSpdLvlRLSM_BGW : 55|2@0+ (1,0) [0|2] "" RLSM
 SG_ seatMassgReqMassgProgRLSM_BGW : 45|4@0+ (1,0) [0|15] "" RLSM
 SG_ seatMassgReqMassgIntenRLSM_BGW : 52|2@0+ (1,0) [0|2] "" RLSM
 SG_ seatIndVlvCtrlRLSM_BGW : 26|1@0+ (1,0) [0|1] "" RLSM
 SG_ seatEngPAmbAir1RLSM_BGW : 39|8@0+ (5,0) [0|254] "hPa" RLSM
 SG_ seatEmgyStopRLSM_BGW : 16|1@0+ (1,0) [0|1] "" RLSM
 SG_ seatDiAutCorrnRLSM_BGW : 17|1@0+ (1,0) [0|1] "" RLSM

BO_ 1295 BGW_RRSMMassageCtrl: 8 BGW
 SG_ seatShIncRRSM_BGW : 23|1@0+ (1,0) [0|1] "" RRSM
 SG_ seatShDecRRSM_BGW : 24|1@0+ (1,0) [0|1] "" RRSM
 SG_ seatLumUpRRSM_BGW : 5|1@0+ (1,0) [0|1] "" RRSM
 SG_ seatLumIncRRSM_BGW : 7|1@0+ (1,0) [0|1] "" RRSM
 SG_ seatLumDwnRRSM_BGW : 4|1@0+ (1,0) [0|1] "" RRSM
 SG_ seatLumDecRRSM_BGW : 6|1@0+ (1,0) [0|1] "" RRSM
 SG_ seatCushIncRRSM_BGW : 21|1@0+ (1,0) [0|1] "" RRSM
 SG_ seatCushDecRRSM_BGW : 22|1@0+ (1,0) [0|1] "" RRSM
 SG_ seatBackSaveSetToMemRRSM_BGW : 20|2@0+ (1,0) [0|2] "" RRSM
 SG_ seatBackPosnStoreRRSM_BGW : 15|1@0+ (1,0) [0|1] "" RRSM
 SG_ seatBackPosnRestoreRRSM_BGW : 14|1@0+ (1,0) [0|1] "" RRSM
 SG_ seatBackCtrReqInOutEasyRRSM_BGW : 18|1@0+ (1,0) [0|1] "" RRSM
 SG_ seatBackBlstrIncRRSM_BGW : 2|1@0+ (1,0) [0|1] "" RRSM
 SG_ seatBackBlstrDecRRSM_BGW : 3|1@0+ (1,0) [0|1] "" RRSM
 SG_ seatProfPenRRSM_BGW : 11|4@0+ (1,0) [0|14] "" RRSM
 SG_ seatPmpRunRRSM_BGW : 25|1@0+ (1,0) [0|1] "" RRSM
 SG_ seatMemSeatCtrlRRSM_BGW : 13|2@0+ (1,0) [0|3] "" RRSM
 SG_ seatMassgReqOnOffRRSM_BGW : 40|1@0+ (1,0) [0|1] "" RRSM
 SG_ seatMassgReqMassgSpdLvlRRSM_BGW : 55|2@0+ (1,0) [0|2] "" RRSM
 SG_ seatMassgReqMassgProgRRSM_BGW : 45|4@0+ (1,0) [0|15] "" RRSM
 SG_ seatMassgReqMassgIntenRRSM_BGW : 52|2@0+ (1,0) [0|2] "" RRSM
 SG_ seatIndVlvCtrlRRSM_BGW : 26|1@0+ (1,0) [0|1] "" RRSM
 SG_ seatEngPAmbAir1RRSM_BGW : 39|8@0+ (5,0) [0|254] "hPa" RRSM
 SG_ seatEmgyStopRRSM_BGW : 16|1@0+ (1,0) [0|1] "" RRSM
 SG_ seatDiAutCorrnRRSM_BGW : 17|1@0+ (1,0) [0|1] "" RRSM

BO_ 1298 ACCL_Status: 3 ACCL
 SG_ sequenceIDStatus_ACCL : 23|8@0+ (1,0) [0|254] "" BGW
 SG_ sequenceStatus_ACCL : 13|2@0+ (1,0) [0|14] "" BGW
 SG_ lightFrontPosLh_ACCL : 7|2@0+ (1,0) [0|2] "" HUD,BGW,FBCM
 SG_ lightFrontPosRh_ACCL : 5|2@0+ (1,0) [0|2] "" HUD,BGW,FBCM
 SG_ lightDrlLh_ACCL : 3|2@0+ (1,0) [0|2] "" HUD,BGW,FBCM
 SG_ lightDrlRh_ACCL : 1|2@0+ (1,0) [0|2] "" HUD,BGW,FBCM

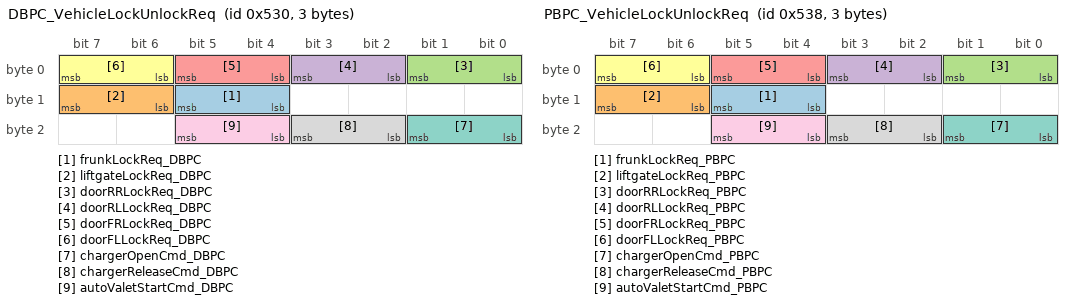
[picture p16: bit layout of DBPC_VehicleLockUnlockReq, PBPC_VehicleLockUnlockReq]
BO_ 1328 DBPC_VehicleLockUnlockReq: 3 DBPC
 SG_ frunkLockReq_DBPC : 13|2@0+ (1,0) [0|2] "" FBCM
 SG_ liftgateLockReq_DBPC : 15|2@0+ (1,0) [0|2] "" FBCM
 SG_ doorRRLockReq_DBPC : 1|2@0+ (1,0) [0|2] "" FBCM
 SG_ doorRLLockReq_DBPC : 3|2@0+ (1,0) [0|2] "" FBCM
 SG_ doorFRLockReq_DBPC : 5|2@0+ (1,0) [0|2] "" FBCM
 SG_ doorFLLockReq_DBPC : 7|2@0+ (1,0) [0|2] "" FBCM
 SG_ chargerOpenCmd_DBPC : 17|2@0+ (1,0) [0|2] "" BGW
 SG_ chargerReleaseCmd_DBPC : 19|2@0+ (1,0) [0|2] "" BGW
 SG_ autoValetStartCmd_DBPC : 21|2@0+ (1,0) [0|2] "" BGW

BO_ 1336 PBPC_VehicleLockUnlockReq: 3 PBPC
 SG_ frunkLockReq_PBPC : 13|2@0+ (1,0) [0|2] "" FBCM
 SG_ liftgateLockReq_PBPC : 15|2@0+ (1,0) [0|2] "" FBCM
 SG_ doorRRLockReq_PBPC : 1|2@0+ (1,0) [0|2] "" FBCM
 SG_ doorRLLockReq_PBPC : 3|2@0+ (1,0) [0|2] "" FBCM
 SG_ doorFRLockReq_PBPC : 5|2@0+ (1,0) [0|2] "" FBCM
 SG_ doorFLLockReq_PBPC : 7|2@0+ (1,0) [0|2] "" FBCM
 SG_ chargerOpenCmd_PBPC : 17|2@0+ (1,0) [0|2] "" BGW
 SG_ chargerReleaseCmd_PBPC : 19|2@0+ (1,0) [0|2] "" BGW
 SG_ autoValetStartCmd_PBPC : 21|2@0+ (1,0) [0|2] "" BGW

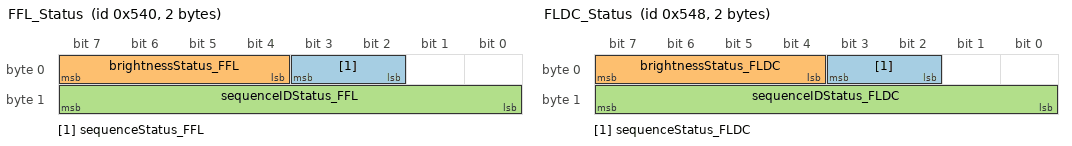
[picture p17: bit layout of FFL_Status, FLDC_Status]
BO_ 1344 FFL_Status: 2 FFL
 SG_ sequenceStatus_FFL : 3|2@0+ (1,0) [0|2] "" BGW
 SG_ brightnessStatus_FFL : 7|4@0+ (0.07,0) [0|0.98] "" BGW
 SG_ sequenceIDStatus_FFL : 15|8@0+ (1,0) [0|254] "" BGW

BO_ 1352 FLDC_Status: 2 FLDC
 SG_ sequenceStatus_FLDC : 3|2@0+ (1,0) [0|2] "" BGW
 SG_ brightnessStatus_FLDC : 7|4@0+ (0.07,0) [0|0.98] "" BGW
 SG_ sequenceIDStatus_FLDC : 15|8@0+ (1,0) [0|254] "" BGW

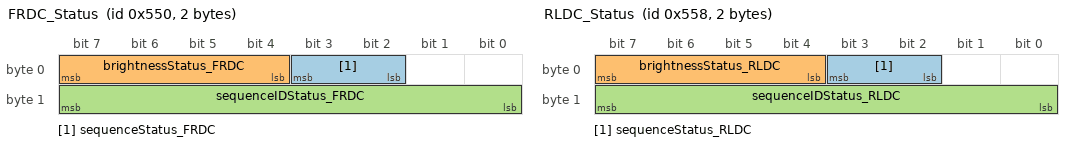
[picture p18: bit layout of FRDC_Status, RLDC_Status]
BO_ 1360 FRDC_Status: 2 FRDC
 SG_ sequenceStatus_FRDC : 3|2@0+ (1,0) [0|2] "" BGW
 SG_ brightnessStatus_FRDC : 7|4@0+ (0.07,0) [0|0.98] "" BGW
 SG_ sequenceIDStatus_FRDC : 15|8@0+ (1,0) [0|254] "" BGW

BO_ 1368 RLDC_Status: 2 RLDC
 SG_ sequenceStatus_RLDC : 3|2@0+ (1,0) [0|2] "" BGW
 SG_ brightnessStatus_RLDC : 7|4@0+ (0.07,0) [0|0.98] "" BGW
 SG_ sequenceIDStatus_RLDC : 15|8@0+ (1,0) [0|254] "" BGW

BO_ 1376 RRDC_Status: 2 RRDC
 SG_ sequenceStatus_RRDC : 3|2@0+ (1,0) [0|2] "" BGW
 SG_ brightnessStatus_RRDC : 7|4@0+ (0.07,0) [0|0.98] "" BGW
 SG_ sequenceIDStatus_RRDC : 15|8@0+ (1,0) [0|254] "" BGW

BO_ 1546 BGW_ResetDiagnostic: 8 BGW
 SG_ hardwarePartNumber_BGW : 7|32@0+ (1,0) [0|4294967294] "" TOOL
 SG_ hardwareRevisionId_BGW : 39|16@0+ (1,0) [0|65534] "" TOOL
 SG_ bootloaderStuckSignal_BGW : 55|8@0+ (1,0) [0|254] "" TOOL
 SG_ resetCause_BGW : 63|8@0+ (1,0) [0|254] "" TOOL

BO_ 1549 BGW_UDSRequest: 8 TOOL

BO_ 1550 BGW_UDSResponse: 8 BGW

BO_ 1551 BGW_Version: 8 BGW
 SG_ c : NaN|NaN@0+ (NaN,NaN) [NaN|NaN] "N" u
 SG_ i : NaN|NaN@0+ (NaN,NaN) [NaN|NaN] "l" d
 SG_ v : NaN|NaN@0+ (NaN,NaN) [NaN|NaN] "o" t

BO_ 1554 FBCM_ResetDiagnostic: 8 FBCM
 SG_ hardwarePartNumber_FBCM : 7|32@0+ (1,0) [0|4294967294] "" TOOL
 SG_ hardwareRevisionId_FBCM : 39|16@0+ (1,0) [0|65534] "" TOOL
 SG_ bootloaderStuckSignal_FBCM : 55|8@0+ (1,0) [0|254] "" TOOL
 SG_ resetCause_FBCM : 63|8@0+ (1,0) [0|254] "" TOOL

BO_ 1557 FBCM_UDSRequest: 8 TOOL
 SG_ udsClientDataFBCM_TOOL : 7|64@0+ (1,0) [0|18446744073709400000] "" FBCM

BO_ 1558 FBCM_UDSResponse: 8 FBCM
 SG_ udsServerData_FBCM : 7|64@0+ (1,0) [0|18446744073709400000] "" TOOL

BO_ 1559 FBCM_Version: 8 FBCM
 SG_ v : NaN|NaN@0+ (NaN,NaN) [NaN|NaN] "o" t
 SG_ i : NaN|NaN@0+ (NaN,NaN) [NaN|NaN] "l" d
 SG_ c : NaN|NaN@0+ (NaN,NaN) [NaN|NaN] "N" u

BO_ 1570 RBCM_ResetDiagnostic: 8 RBCM
 SG_ hardwarePartNumber_RBCM : 7|32@0+ (1,0) [0|4294967294] "" TOOL
 SG_ hardwareRevisionId_RBCM : 39|16@0+ (1,0) [0|65534] "" TOOL
 SG_ bootloaderStuckSignal_RBCM : 55|8@0+ (1,0) [0|254] "" TOOL
 SG_ resetCause_RBCM : 63|8@0+ (1,0) [0|254] "" TOOL

BO_ 1573 RBCM_UDSRequest: 8 TOOL

BO_ 1574 RBCM_UDSResponse: 8 RBCM

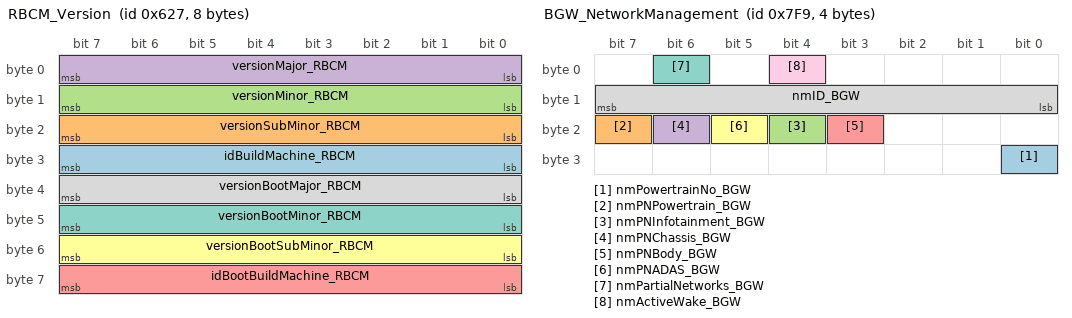
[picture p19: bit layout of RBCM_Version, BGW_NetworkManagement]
BO_ 1575 RBCM_Version: 8 RBCM
 SG_ idBuildMachine_RBCM : 31|8@0+ (1,0) [0|254] "" TOOL
 SG_ versionSubMinor_RBCM : 23|8@0+ (1,0) [0|254] "" TOOL,BGW
 SG_ versionMinor_RBCM : 15|8@0+ (1,0) [0|254] "" TOOL,BGW
 SG_ versionMajor_RBCM : 7|8@0+ (1,0) [0|254] "" TOOL,BGW
 SG_ idBootBuildMachine_RBCM : 63|8@0+ (1,0) [0|254] "" TOOL
 SG_ versionBootSubMinor_RBCM : 55|8@0+ (1,0) [0|254] "" TOOL
 SG_ versionBootMinor_RBCM : 47|8@0+ (1,0) [0|254] "" TOOL
 SG_ versionBootMajor_RBCM : 39|8@0+ (1,0) [0|254] "" TOOL

BO_ 1597 SCAM_UDSRequest: 8 TOOL
 SG_ udsClientDataSCAM_TOOL : 7|64@0+ (1,0) [0|18446744073709400000] "" SCAM

BO_ 1598 SCAM_UDSResponse: 8 SCAM
 SG_ udsServerData_SCAM : 7|64@0+ (1,0) [0|18446744073709400000] "" TOOL

BO_ 1599 SCAM_Version: 8 SCAM
 SG_ v : NaN|NaN@0+ (NaN,NaN) [NaN|NaN] "o" t
 SG_ c : NaN|NaN@0+ (NaN,NaN) [NaN|NaN] "N" u
 SG_ i : NaN|NaN@0+ (NaN,NaN) [NaN|NaN] "l" d

BO_ 1602 HLL_ResetDiagnostic: 8 HLL
 SG_ hardwarePartNumber_HLL : 7|32@0+ (1,0) [0|4294967294] "" TOOL
 SG_ hardwareRevisionId_HLL : 39|16@0+ (1,0) [0|65534] "" TOOL
 SG_ bootloaderStuckSignal_HLL : 55|8@0+ (1,0) [0|254] "" TOOL
 SG_ resetCause_HLL : 63|8@0+ (1,0) [0|254] "" TOOL

BO_ 1605 HLL_UDSRequest: 8 TOOL
 SG_ udsClientDataHLL_TOOL : 7|64@0+ (1,0) [0|18446744073709400000] "" HLL

BO_ 1606 HLL_UDSResponse: 8 HLL
 SG_ udsServerData_HLL : 7|64@0+ (1,0) [0|18446744073709400000] "" TOOL

BO_ 1607 HLL_Version: 8 HLL
 SG_ v : NaN|NaN@0+ (NaN,NaN) [NaN|NaN] "o" t
 SG_ c : NaN|NaN@0+ (NaN,NaN) [NaN|NaN] "N" u
 SG_ i : NaN|NaN@0+ (NaN,NaN) [NaN|NaN] "l" d

BO_ 1610 HLR_ResetDiagnostic: 8 HLR
 SG_ hardwarePartNumber_HLR : 7|32@0+ (1,0) [0|4294967294] "" TOOL
 SG_ hardwareRevisionId_HLR : 39|16@0+ (1,0) [0|65534] "" TOOL
 SG_ bootloaderStuckSignal_HLR : 55|8@0+ (1,0) [0|254] "" TOOL
 SG_ resetCause_HLR : 63|8@0+ (1,0) [0|254] "" TOOL

BO_ 1613 HLR_UDSRequest: 8 TOOL
 SG_ udsClientDataHLR_TOOL : 7|64@0+ (1,0) [0|18446744073709400000] "" HLR

BO_ 1614 HLR_UDSResponse: 8 HLR
 SG_ udsServerData_HLR : 7|64@0+ (1,0) [0|18446744073709400000] "" TOOL

BO_ 1615 HLR_Version: 8 HLR
 SG_ v : NaN|NaN@0+ (NaN,NaN) [NaN|NaN] "o" t
 SG_ c : NaN|NaN@0+ (NaN,NaN) [NaN|NaN] "N" u
 SG_ i : NaN|NaN@0+ (NaN,NaN) [NaN|NaN] "l" d

BO_ 1634 DCFL_ResetDiagnostic: 8 DCFL
 SG_ hardwarePartNumber_DCFL : 7|32@0+ (1,0) [0|4294967294] "" TOOL
 SG_ hardwareRevisionId_DCFL : 39|16@0+ (1,0) [0|65534] "" TOOL
 SG_ bootloaderStuckSignal_DCFL : 55|8@0+ (1,0) [0|254] "" TOOL
 SG_ resetCause_DCFL : 63|8@0+ (1,0) [0|254] "" TOOL

BO_ 1637 DCFL_UDSRequest: 8 TOOL
 SG_ udsClientDataDcfl_TOOL : 7|64@0+ (1,0) [0|18446744073709400000] "" DCFL

BO_ 1638 DCFL_UDSResponse: 8 DCFL
 SG_ udsServerData_DCFL : 7|64@0+ (1,0) [0|18446744073709400000] "" TOOL

BO_ 1639 DCFL_Version: 8 DCFL
 SG_ v : NaN|NaN@0+ (NaN,NaN) [NaN|NaN] "o" t
 SG_ i : NaN|NaN@0+ (NaN,NaN) [NaN|NaN] "l" d
 SG_ c : NaN|NaN@0+ (NaN,NaN) [NaN|NaN] "N" u

BO_ 1650 DSM_ResetDiagnostic: 8 DSM
 SG_ resetCause_DSM : 63|8@0+ (1,0) [0|254] "" TOOL
 SG_ hardwareRevisionId_DSM : 39|16@0+ (1,0) [0|65534] "" TOOL
 SG_ hardwarePartNumber_DSM : 7|32@0+ (1,0) [0|4294967294] "" TOOL
 SG_ bootloaderStuckSignal_DSM : 55|8@0+ (1,0) [0|254] "" TOOL

BO_ 1653 DSM_UDSRequest: 8 TOOL
 SG_ udsClientDataDSM_TOOL : 7|64@0+ (1,0) [0|18446744073709400000] "" DSM

BO_ 1654 DSM_UDSResponse: 8 DSM
 SG_ udsServerData_DSM : 7|64@0+ (1,0) [0|18446744073709400000] "" TOOL

BO_ 1655 DSM_Version: 8 DSM
 SG_ v : NaN|NaN@0+ (NaN,NaN) [NaN|NaN] "o" t
 SG_ c : NaN|NaN@0+ (NaN,NaN) [NaN|NaN] "N" u
 SG_ i : NaN|NaN@0+ (NaN,NaN) [NaN|NaN] "l" d

BO_ 1658 DDP_ResetDiagnostic: 8 DDP
 SG_ hardwarePartNumber_DDP : 7|32@0+ (1,0) [0|4294967294] "" TOOL
 SG_ hardwareRevisionId_DDP : 39|16@0+ (1,0) [0|65534] "" TOOL
 SG_ bootloaderStuckSignal_DDP : 55|8@0+ (1,0) [0|254] "" TOOL
 SG_ resetCause_DDP : 63|8@0+ (1,0) [0|254] "" TOOL

BO_ 1661 DDP_UDSRequest: 8 TOOL
 SG_ udsClientDataDDP_TOOL : 7|64@0+ (1,0) [0|18446744073709400000] "" DDP

BO_ 1662 DDP_UDSResponse: 8 DDP
 SG_ udsServerData_DDP : 7|64@0+ (1,0) [0|18446744073709400000] "" TOOL

BO_ 1663 DDP_Version: 8 DDP
 SG_ v : NaN|NaN@0+ (NaN,NaN) [NaN|NaN] "o" t
 SG_ c : NaN|NaN@0+ (NaN,NaN) [NaN|NaN] "N" u
 SG_ i : NaN|NaN@0+ (NaN,NaN) [NaN|NaN] "l" d

BO_ 1674 DCFR_ResetDiagnostic: 8 DCFR
 SG_ hardwarePartNumber_DCFR : 7|32@0+ (1,0) [0|4294967294] "" TOOL
 SG_ hardwareRevisionId_DCFR : 39|16@0+ (1,0) [0|65534] "" TOOL
 SG_ bootloaderStuckSignal_DCFR : 55|8@0+ (1,0) [0|254] "" TOOL
 SG_ resetCause_DCFR : 63|8@0+ (1,0) [0|254] "" TOOL

BO_ 1677 DCFR_UDSRequest: 8 TOOL
 SG_ udsClientDataDcfr_TOOL : 7|64@0+ (1,0) [0|18446744073709400000] "" DCFR

BO_ 1678 DCFR_UDSResponse: 8 DCFR
 SG_ udsServerData_DCFR : 7|64@0+ (1,0) [0|18446744073709400000] "" TOOL

BO_ 1679 DCFR_Version: 8 DCFR
 SG_ v : NaN|NaN@0+ (NaN,NaN) [NaN|NaN] "o" t
 SG_ i : NaN|NaN@0+ (NaN,NaN) [NaN|NaN] "l" d
 SG_ c : NaN|NaN@0+ (NaN,NaN) [NaN|NaN] "N" u

BO_ 1682 PSM_ResetDiagnostic: 8 PSM
 SG_ resetCause_PSM : 55|8@0+ (1,0) [0|254] "" TOOL
 SG_ hardwareRevisionId_PSM : 39|16@0+ (1,0) [0|65534] "" TOOL
 SG_ hardwarePartNumber_PSM : 7|32@0+ (1,0) [0|4294967294] "" TOOL
 SG_ bootloaderStuckSignal_PSM : 63|8@0+ (1,0) [0|254] "" TOOL

BO_ 1685 PSM_UDSRequest: 8 TOOL
 SG_ udsClientDataPSM_TOOL : 7|64@0+ (1,0) [0|18446744073709400000] "" PSM

BO_ 1686 PSM_UDSResponse: 8 PSM
 SG_ udsServerData_PSM : 7|64@0+ (1,0) [0|18446744073709400000] "" TOOL

BO_ 1687 PSM_Version: 8 PSM
 SG_ v : NaN|NaN@0+ (NaN,NaN) [NaN|NaN] "o" t
 SG_ c : NaN|NaN@0+ (NaN,NaN) [NaN|NaN] "N" u
 SG_ i : NaN|NaN@0+ (NaN,NaN) [NaN|NaN] "l" d

BO_ 1690 PDP_ResetDiagnostic: 8 PDP
 SG_ hardwarePartNumber_PDP : 7|32@0+ (1,0) [0|4294967294] "" TOOL
 SG_ hardwareRevisionId_PDP : 39|16@0+ (1,0) [0|65534] "" TOOL
 SG_ bootloaderStuckSignal_PDP : 55|8@0+ (1,0) [0|254] "" TOOL
 SG_ resetCause_PDP : 63|8@0+ (1,0) [0|254] "" TOOL

BO_ 1693 PDP_UDSRequest: 8 TOOL
 SG_ udsClientDataPDP_TOOL : 7|64@0+ (1,0) [0|18446744073709400000] "" PDP

BO_ 1694 PDP_UDSResponse: 8 PDP
 SG_ udsServerData_PDP : 7|64@0+ (1,0) [0|18446744073709400000] "" TOOL

BO_ 1695 PDP_Version: 8 PDP
 SG_ v : NaN|NaN@0+ (NaN,NaN) [NaN|NaN] "o" t
 SG_ c : NaN|NaN@0+ (NaN,NaN) [NaN|NaN] "N" u
 SG_ i : NaN|NaN@0+ (NaN,NaN) [NaN|NaN] "l" d

BO_ 1706 DCRL_ResetDiagnostic: 8 DCRL
 SG_ hardwarePartNumber_DCRL : 7|32@0+ (1,0) [0|4294967294] "" TOOL
 SG_ hardwareRevisionId_DCRL : 39|16@0+ (1,0) [0|65534] "" TOOL
 SG_ bootloaderStuckSignal_DCRL : 55|8@0+ (1,0) [0|254] "" TOOL
 SG_ resetCause_DCRL : 63|8@0+ (1,0) [0|254] "" TOOL

BO_ 1709 DCRL_UDSRequest: 8 TOOL
 SG_ udsClientDataDcrl_TOOL : 7|64@0+ (1,0) [0|18446744073709400000] "" DCRL

BO_ 1710 DCRL_UDSResponse: 8 DCRL
 SG_ udsServerData_DCRL : 7|64@0+ (1,0) [0|18446744073709400000] "" TOOL

BO_ 1711 DCRL_Version: 8 DCRL
 SG_ v : NaN|NaN@0+ (NaN,NaN) [NaN|NaN] "o" t
 SG_ i : NaN|NaN@0+ (NaN,NaN) [NaN|NaN] "l" d
 SG_ c : NaN|NaN@0+ (NaN,NaN) [NaN|NaN] "N" u

BO_ 1714 RLSM_ResetDiagnostic: 8 RLSM
 SG_ resetCause_RLSM : 63|8@0+ (1,0) [0|254] "" TOOL
 SG_ hardwareRevisionId_RLSM : 39|16@0+ (1,0) [0|65534] "" TOOL
 SG_ hardwarePartNumber_RLSM : 7|32@0+ (1,0) [0|4294967294] "" TOOL
 SG_ bootloaderStuckSignal_RLSM : 55|8@0+ (1,0) [0|254] "" TOOL

BO_ 1717 RLSM_UDSRequest: 8 TOOL
 SG_ udsClientDataRLSM_TOOL : 7|64@0+ (1,0) [0|18446744073709400000] "" RLSM

BO_ 1718 RLSM_UDSResponse: 8 RLSM
 SG_ udsServerData_RLSM : 7|64@0+ (1,0) [0|18446744073709400000] "" TOOL

BO_ 1719 RLSM_Version: 8 RLSM
 SG_ v : NaN|NaN@0+ (NaN,NaN) [NaN|NaN] "o" t
 SG_ c : NaN|NaN@0+ (NaN,NaN) [NaN|NaN] "N" u
 SG_ i : NaN|NaN@0+ (NaN,NaN) [NaN|NaN] "l" d

BO_ 1722 RLDP_ResetDiagnostic: 8 RLDP
 SG_ hardwarePartNumber_RLDP : 7|32@0+ (1,0) [0|4294967294] "" TOOL
 SG_ hardwareRevisionId_RLDP : 39|16@0+ (1,0) [0|65534] "" TOOL
 SG_ bootloaderStuckSignal_RLDP : 55|8@0+ (1,0) [0|254] "" TOOL
 SG_ resetCause_RLDP : 63|8@0+ (1,0) [0|254] "" TOOL

BO_ 1725 RLDP_UDSRequest: 8 TOOL
 SG_ udsClientDataRLDP_TOOL : 7|64@0+ (1,0) [0|18446744073709400000] "" RLDP

BO_ 1726 RLDP_UDSResponse: 8 RLDP
 SG_ udsServerData_RLDP : 7|64@0+ (1,0) [0|18446744073709400000] "" TOOL

BO_ 1727 RLDP_Version: 8 RLDP
 SG_ v : NaN|NaN@0+ (NaN,NaN) [NaN|NaN] "o" t
 SG_ c : NaN|NaN@0+ (NaN,NaN) [NaN|NaN] "N" u
 SG_ i : NaN|NaN@0+ (NaN,NaN) [NaN|NaN] "l" d

BO_ 1738 DCRR_ResetDiagnostic: 8 DCRR
 SG_ hardwarePartNumber_DCRR : 7|32@0+ (1,0) [0|4294967294] "" TOOL
 SG_ hardwareRevisionId_DCRR : 39|16@0+ (1,0) [0|65534] "" TOOL
 SG_ bootloaderStuckSignal_DCRR : 55|8@0+ (1,0) [0|254] "" TOOL
 SG_ resetCause_DCRR : 63|8@0+ (1,0) [0|254] "" TOOL

BO_ 1741 DCRR_UDSRequest: 8 TOOL
 SG_ udsClientDataDcrr_TOOL : 7|64@0+ (1,0) [0|18446744073709400000] "" DCRR

BO_ 1742 DCRR_UDSResponse: 8 DCRR
 SG_ udsServerData_DCRR : 7|64@0+ (1,0) [0|18446744073709400000] "" TOOL

BO_ 1743 DCRR_Version: 8 DCRR
 SG_ v : NaN|NaN@0+ (NaN,NaN) [NaN|NaN] "o" t
 SG_ i : NaN|NaN@0+ (NaN,NaN) [NaN|NaN] "l" d
 SG_ c : NaN|NaN@0+ (NaN,NaN) [NaN|NaN] "N" u

BO_ 1746 RRSM_ResetDiagnostic: 8 RRSM
 SG_ resetCause_RRSM : 63|8@0+ (1,0) [0|254] "" TOOL
 SG_ hardwareRevisionId_RRSM : 39|16@0+ (1,0) [0|65534] "" TOOL
 SG_ hardwarePartNumber_RRSM : 7|32@0+ (1,0) [0|4294967294] "" TOOL
 SG_ bootloaderStuckSignal_RRSM : 55|8@0+ (1,0) [0|254] "" TOOL

BO_ 1749 RRSM_UDSRequest: 8 TOOL
 SG_ udsClientDataRRSM_TOOL : 7|64@0+ (1,0) [0|18446744073709400000] "" RRSM

BO_ 1750 RRSM_UDSResponse: 8 RRSM
 SG_ udsServerData_RRSM : 7|64@0+ (1,0) [0|18446744073709400000] "" TOOL

BO_ 1751 RRSM_Version: 8 RRSM
 SG_ v : NaN|NaN@0+ (NaN,NaN) [NaN|NaN] "o" t
 SG_ c : NaN|NaN@0+ (NaN,NaN) [NaN|NaN] "N" u
 SG_ i : NaN|NaN@0+ (NaN,NaN) [NaN|NaN] "l" d

BO_ 1762 RRDP_ResetDiagnostic: 8 RRDP
 SG_ hardwarePartNumber_RRDP : 7|32@0+ (1,0) [0|4294967294] "" TOOL
 SG_ hardwareRevisionId_RRDP : 39|16@0+ (1,0) [0|65534] "" TOOL
 SG_ bootloaderStuckSignal_RRDP : 55|8@0+ (1,0) [0|254] "" TOOL
 SG_ resetCause_RRDP : 63|8@0+ (1,0) [0|254] "" TOOL

BO_ 1765 RRDP_UDSRequest: 8 TOOL
 SG_ udsClientDataRRDP_TOOL : 7|64@0+ (1,0) [0|18446744073709400000] "" RRDP

BO_ 1766 RRDP_UDSResponse: 8 RRDP
 SG_ udsServerData_RRDP : 7|64@0+ (1,0) [0|18446744073709400000] "" TOOL

BO_ 1767 RRDP_Version: 8 RRDP
 SG_ v : NaN|NaN@0+ (NaN,NaN) [NaN|NaN] "o" t
 SG_ c : NaN|NaN@0+ (NaN,NaN) [NaN|NaN] "N" u
 SG_ i : NaN|NaN@0+ (NaN,NaN) [NaN|NaN] "l" d

BO_ 1773 LGL_UDSRequest: 8 TOOL
 SG_ udsClientDataLGL_TOOL : 7|64@0+ (1,0) [0|18446744073709400000] "" LGL

BO_ 1774 LGL_UDSResponse: 8 LGL
 SG_ udsServerData_LGL : 7|64@0+ (1,0) [0|18446744073709400000] "" TOOL

BO_ 1775 LGL_Version: 8 LGL
 SG_ v : NaN|NaN@0+ (NaN,NaN) [NaN|NaN] "o" t
 SG_ c : NaN|NaN@0+ (NaN,NaN) [NaN|NaN] "N" u
 SG_ i : NaN|NaN@0+ (NaN,NaN) [NaN|NaN] "l" d

BO_ 1789 RCLL_UDSRequest: 8 TOOL
 SG_ udsClientDataRCLL_TOOL : 7|64@0+ (1,0) [0|18446744073709400000] "" RCLL

BO_ 1790 RCLL_UDSResponse: 8 RCLL
 SG_ udsServerData_RCLL : 7|64@0+ (1,0) [0|18446744073709400000] "" TOOL

BO_ 1791 RCLL_Version: 8 RCLL
 SG_ v : NaN|NaN@0+ (NaN,NaN) [NaN|NaN] "o" t
 SG_ c : NaN|NaN@0+ (NaN,NaN) [NaN|NaN] "N" u
 SG_ i : NaN|NaN@0+ (NaN,NaN) [NaN|NaN] "l" d

BO_ 1797 RCLR_UDSRequest: 8 TOOL
 SG_ udsClientDataRCLR_TOOL : 7|64@0+ (1,0) [0|18446744073709400000] "" RCLR

BO_ 1798 RCLR_UDSResponse: 8 RCLR
 SG_ udsServerData_RCLR : 7|64@0+ (1,0) [0|18446744073709400000] "" TOOL

BO_ 1799 RCLR_Version: 8 RCLR
 SG_ v : NaN|NaN@0+ (NaN,NaN) [NaN|NaN] "o" t
 SG_ c : NaN|NaN@0+ (NaN,NaN) [NaN|NaN] "N" u
 SG_ i : NaN|NaN@0+ (NaN,NaN) [NaN|NaN] "l" d

BO_ 1800 BGW_EthDebug: 8 BGW
 SG_ dbgEthNumMsgMissedFromIHUB_BGW : 55|16@0+ (1,0) [0|65534] "" TOOL
 SG_ dbgEthMaxMsgMissedFromIHUB_BGW : 39|16@0+ (1,0) [0|65534] "" TOOL
 SG_ dbgEthNumMsgMissedFromBPG_BGW : 23|16@0+ (1,0) [0|65534] "" TOOL
 SG_ dbgEthMaxMsgMissedFromBPG_BGW : 7|16@0+ (1,0) [0|65534] "" TOOL

BO_ 1813 ACCL_UDSRequest: 8 TOOL
 SG_ udsClientDataACCL_TOOL : 7|64@0+ (1,0) [0|18446744073709400000] "" ACCL

BO_ 1814 ACCL_UDSResponse: 8 ACCL
 SG_ udsServerData_ACCL : 7|64@0+ (1,0) [0|18446744073709400000] "" TOOL

BO_ 1815 ACCL_Version: 8 ACCL
 SG_ v : NaN|NaN@0+ (NaN,NaN) [NaN|NaN] "o" t
 SG_ c : NaN|NaN@0+ (NaN,NaN) [NaN|NaN] "N" u
 SG_ i : NaN|NaN@0+ (NaN,NaN) [NaN|NaN] "l" d

BO_ 1826 ECPM_ResetDiagnostic: 8 ECPM
 SG_ hardwarePartNumber_ECPM : 7|32@0+ (1,0) [0|4294967294] "" TOOL
 SG_ hardwareRevisionId_ECPM : 39|16@0+ (1,0) [0|65534] "" TOOL
 SG_ bootloaderStuckSignal_ECPM : 55|8@0+ (1,0) [0|254] "" TOOL
 SG_ resetCause_ECPM : 63|8@0+ (1,0) [0|254] "" TOOL

BO_ 1829 ECPM_UDSRequest: 8 TOOL
 SG_ udsClientDataECPM_TOOL : 7|64@0+ (1,0) [0|18446744073709400000] "" ECPM

BO_ 1830 ECPM_UDSResponse: 8 ECPM
 SG_ udsServerData_ECPM : 7|64@0+ (1,0) [0|18446744073709400000] "" TOOL

BO_ 1831 ECPM_Version: 8 ECPM
 SG_ v : NaN|NaN@0+ (NaN,NaN) [NaN|NaN] "o" t
 SG_ c : NaN|NaN@0+ (NaN,NaN) [NaN|NaN] "N" u
 SG_ i : NaN|NaN@0+ (NaN,NaN) [NaN|NaN] "l" d

BO_ 1842 DBPC_ResetDiagnostic: 8 DBPC
 SG_ hardwarePartNumber_DBPC : 7|32@0+ (1,0) [0|4294967294] "" TOOL
 SG_ hardwareRevisionId_DBPC : 39|16@0+ (1,0) [0|65534] "" TOOL
 SG_ bootloaderStuckSignal_DBPC : 55|8@0+ (1,0) [0|254] "" TOOL
 SG_ resetCause_DBPC : 63|8@0+ (1,0) [0|254] "" TOOL

BO_ 1845 DBPC_UDSRequest: 8 TOOL
 SG_ udsClientDataDBPC_TOOL : 7|64@0+ (1,0) [0|18446744073709400000] "" DBPC

BO_ 1846 DBPC_UDSResponse: 8 DBPC
 SG_ udsServerData_DBPC : 7|64@0+ (1,0) [0|18446744073709400000] "" TOOL

BO_ 1847 DBPC_Version: 8 DBPC
 SG_ v : NaN|NaN@0+ (NaN,NaN) [NaN|NaN] "o" t
 SG_ c : NaN|NaN@0+ (NaN,NaN) [NaN|NaN] "N" u
 SG_ i : NaN|NaN@0+ (NaN,NaN) [NaN|NaN] "l" d

BO_ 1850 PBPC_ResetDiagnostic: 8 PBPC
 SG_ hardwarePartNumber_PBPC : 7|32@0+ (1,0) [0|4294967294] "" TOOL
 SG_ hardwareRevisionId_PBPC : 39|16@0+ (1,0) [0|65534] "" TOOL
 SG_ bootloaderStuckSignal_PBPC : 55|8@0+ (1,0) [0|254] "" TOOL
 SG_ resetCause_PBPC : 63|8@0+ (1,0) [0|254] "" TOOL

BO_ 1853 PBPC_UDSRequest: 8 TOOL
 SG_ udsClientDataPBPC_TOOL : 7|64@0+ (1,0) [0|18446744073709400000] "" PBPC

BO_ 1854 PBPC_UDSResponse: 8 PBPC
 SG_ udsServerData_PBPC : 7|64@0+ (1,0) [0|18446744073709400000] "" TOOL

BO_ 1855 PBPC_Version: 8 PBPC
 SG_ v : NaN|NaN@0+ (NaN,NaN) [NaN|NaN] "o" t
 SG_ c : NaN|NaN@0+ (NaN,NaN) [NaN|NaN] "N" u
 SG_ i : NaN|NaN@0+ (NaN,NaN) [NaN|NaN] "l" d

BO_ 1858 FFL_ResetDiagnostic: 8 FFL
 SG_ hardwarePartNumber_FFL : 7|32@0+ (1,0) [0|4294967294] "" TOOL
 SG_ hardwareRevisionId_FFL : 39|16@0+ (1,0) [0|65534] "" TOOL
 SG_ bootloaderStuckSignal_FFL : 55|8@0+ (1,0) [0|254] "" TOOL
 SG_ resetCause_FFL : 63|8@0+ (1,0) [0|254] "" TOOL

BO_ 1861 FFL_UDSRequest: 8 TOOL
 SG_ udsClientDataFFL_TOOL : 7|64@0+ (1,0) [0|18446744073709400000] "" FFL

BO_ 1862 FFL_UDSResponse: 8 FFL
 SG_ udsServerData_FFL : 7|64@0+ (1,0) [0|18446744073709400000] "" TOOL

BO_ 1863 FFL_Version: 8 FFL
 SG_ v : NaN|NaN@0+ (NaN,NaN) [NaN|NaN] "o" t
 SG_ c : NaN|NaN@0+ (NaN,NaN) [NaN|NaN] "N" u
 SG_ i : NaN|NaN@0+ (NaN,NaN) [NaN|NaN] "l" d

BO_ 1866 FLDC_ResetDiagnostic: 8 FLDC
 SG_ hardwarePartNumber_FLDC : 7|32@0+ (1,0) [0|4294967294] "" TOOL
 SG_ hardwareRevisionId_FLDC : 39|16@0+ (1,0) [0|65534] "" TOOL
 SG_ bootloaderStuckSignal_FLDC : 55|8@0+ (1,0) [0|254] "" TOOL
 SG_ resetCause_FLDC : 63|8@0+ (1,0) [0|254] "" TOOL

BO_ 1869 FLDC_UDSRequest: 8 TOOL
 SG_ udsClientDataFLDC_TOOL : 7|64@0+ (1,0) [0|18446744073709400000] "" FLDC

BO_ 1870 FLDC_UDSResponse: 8 FLDC
 SG_ udsServerData_FLDC : 7|64@0+ (1,0) [0|18446744073709400000] "" TOOL

BO_ 1871 FLDC_Version: 8 FLDC
 SG_ v : NaN|NaN@0+ (NaN,NaN) [NaN|NaN] "o" t
 SG_ c : NaN|NaN@0+ (NaN,NaN) [NaN|NaN] "N" u
 SG_ i : NaN|NaN@0+ (NaN,NaN) [NaN|NaN] "l" d

BO_ 1874 FRDC_ResetDiagnostic: 8 FRDC
 SG_ hardwarePartNumber_FRDC : 7|32@0+ (1,0) [0|4294967294] "" TOOL
 SG_ hardwareRevisionId_FRDC : 39|16@0+ (1,0) [0|65534] "" TOOL
 SG_ bootloaderStuckSignal_FRDC : 55|8@0+ (1,0) [0|254] "" TOOL
 SG_ resetCause_FRDC : 63|8@0+ (1,0) [0|254] "" TOOL

BO_ 1877 FRDC_UDSRequest: 8 TOOL
 SG_ udsClientDataFRDC_TOOL : 7|64@0+ (1,0) [0|18446744073709400000] "" FRDC

BO_ 1878 FRDC_UDSResponse: 8 FRDC
 SG_ udsServerData_FRDC : 7|64@0+ (1,0) [0|18446744073709400000] "" TOOL

BO_ 1879 FRDC_Version: 8 FRDC
 SG_ v : NaN|NaN@0+ (NaN,NaN) [NaN|NaN] "o" t
 SG_ c : NaN|NaN@0+ (NaN,NaN) [NaN|NaN] "N" u
 SG_ i : NaN|NaN@0+ (NaN,NaN) [NaN|NaN] "l" d

BO_ 1882 RLDC_ResetDiagnostic: 8 RLDC
 SG_ hardwarePartNumber_RLDC : 7|32@0+ (1,0) [0|4294967294] "" TOOL
 SG_ hardwareRevisionId_RLDC : 39|16@0+ (1,0) [0|65534] "" TOOL
 SG_ bootloaderStuckSignal_RLDC : 55|8@0+ (1,0) [0|254] "" TOOL
 SG_ resetCause_RLDC : 63|8@0+ (1,0) [0|254] "" TOOL

BO_ 1885 RLDC_UDSRequest: 8 TOOL
 SG_ udsClientDataRLDC_TOOL : 7|64@0+ (1,0) [0|18446744073709400000] "" RLDC

BO_ 1886 RLDC_UDSResponse: 8 RLDC
 SG_ udsServerData_RLDC : 7|64@0+ (1,0) [0|18446744073709400000] "" TOOL

BO_ 1887 RLDC_Version: 8 RLDC
 SG_ v : NaN|NaN@0+ (NaN,NaN) [NaN|NaN] "o" t
 SG_ c : NaN|NaN@0+ (NaN,NaN) [NaN|NaN] "N" u
 SG_ i : NaN|NaN@0+ (NaN,NaN) [NaN|NaN] "l" d

BO_ 1890 RRDC_ResetDiagnostic: 8 RRDC
 SG_ hardwarePartNumber_RRDC : 7|32@0+ (1,0) [0|4294967294] "" TOOL
 SG_ hardwareRevisionId_RRDC : 39|16@0+ (1,0) [0|65534] "" TOOL
 SG_ bootloaderStuckSignal_RRDC : 55|8@0+ (1,0) [0|254] "" TOOL
 SG_ resetCause_RRDC : 63|8@0+ (1,0) [0|254] "" TOOL

BO_ 1893 RRDC_UDSRequest: 8 TOOL
 SG_ udsClientDataRRDC_TOOL : 7|64@0+ (1,0) [0|18446744073709400000] "" RRDC

BO_ 1894 RRDC_UDSResponse: 8 RRDC
 SG_ udsServerData_RRDC : 7|64@0+ (1,0) [0|18446744073709400000] "" TOOL

BO_ 1895 RRDC_Version: 8 RRDC
 SG_ v : NaN|NaN@0+ (NaN,NaN) [NaN|NaN] "o" t
 SG_ c : NaN|NaN@0+ (NaN,NaN) [NaN|NaN] "N" u
 SG_ i : NaN|NaN@0+ (NaN,NaN) [NaN|NaN] "l" d

BO_ 2041 BGW_NetworkManagement: 4 BGW
 SG_ nmPowertrainNo_BGW : 24|1@0+ (1,0) [0|1] "" ACCL,BLE,DBPC,DCFL,DCFR,DCRL,DCRR,DDP,DSM,ECPM,FBCM,FFL,FLDC,FRDC,HLL,HLR,HUD,IHUB,LGL,PBPC,PDP,PSM,RBCM,RCLL,RCLR,RLDC,RLDP,RLSM,RRDC,RRDP,RRSM,SCAM
 SG_ nmPNPowertrain_BGW : 23|1@0+ (1,0) [0|1] "" TOOL
 SG_ nmPNInfotainment_BGW : 20|1@0+ (1,0) [0|1] "" TOOL
 SG_ nmPNChassis_BGW : 22|1@0+ (1,0) [0|1] "" TOOL
 SG_ nmPNBody_BGW : 19|1@0+ (1,0) [0|1] "" ACCL,BLE,DBPC,DCFL,DCFR,DCRL,DCRR,DDP,DSM,ECPM,FBCM,FFL,FLDC,FRDC,HLL,HLR,HUD,IHUB,LGL,PBPC,PDP,PSM,RBCM,RCLL,RCLR,RLDC,RLDP,RLSM,RRDC,RRDP,RRSM,SCAM
 SG_ nmPNADAS_BGW : 21|1@0+ (1,0) [0|1] "" TOOL
 SG_ nmPartialNetworks_BGW : 6|1@0+ (1,0) [0|1] "" ACCL,BLE,DBPC,DCFL,DCFR,DCRL,DCRR,DDP,DSM,ECPM,FBCM,FFL,FLDC,FRDC,HLL,HLR,HUD,IHUB,LGL,PBPC,PDP,PSM,RBCM,RCLL,RCLR,RLDC,RLDP,RLSM,RRDC,RRDP,RRSM,SCAM
 SG_ nmID_BGW : 15|8@0+ (1,0) [0|31] "" ACCL,BLE,DBPC,DCFL,DCFR,DCRL,DCRR,DDP,DSM,ECPM,FBCM,FFL,FLDC,FRDC,HLL,HLR,HUD,IHUB,LGL,PBPC,PDP,PSM,RBCM,RCLL,RCLR,RLDC,RLDP,RLSM,RRDC,RRDP,RRSM,SCAM
 SG_ nmActiveWake_BGW : 4|1@0+ (1,0) [0|1] "" ACCL,BLE,DBPC,DCFL,DCFR,DCRL,DCRR,DDP,DSM,ECPM,FBCM,FFL,FLDC,FRDC,HLL,HLR,HUD,IHUB,LGL,PBPC,PDP,PSM,RBCM,RCLL,RCLR,RLDC,RLDP,RLSM,RRDC,RRDP,RRSM,SCAM

BO_ 2047 TOOL_UDSFunctionalRequest: 8 TOOL
 SG_ udsFunctionalRequestData_TOOL : 7|64@0+ (1,0) [0|18446700000000000000] "" RRSM,RLSM,PSM,DSM

CM_ SG_ 1088 lightDrlStatus_HLL "DRL light status";
CM_ SG_ 1088 lightLowBeamStatus_HLL "Low beam light status";
CM_ SG_ 1088 lightHighBeamStatus_HLL "High beam light status";
CM_ SG_ 1088 lightTurnStatus_HLL "Turn light status";
CM_ SG_ 1088 lightCorneringStatus_HLL "Cornering light status";
CM_ SG_ 1096 lightDrlStatus_HLR "DRL light status";
CM_ SG_ 1096 lightLowBeamStatus_HLR "Low beam light status";
CM_ SG_ 1096 lightHighBeamStatus_HLR "High beam light status";
CM_ SG_ 1096 lightCorneringStatus_HLR "Cornering light status";
CM_ SG_ 1096 lightTurnStatus_HLR "Turn light status";
CM_ SG_ 680 doorLockReq_DCRL "Rear left door lock request status";
CM_ SG_ 680 mirrorStatusMovUpDownLeft_DCRL "Front left mirror up/down movement status";
CM_ SG_ 680 mirrorStatusMovInOutLeft_DCRL "Front left mirror inwords/outwords movement status";
CM_ SG_ 680 mirrorDefrostCamStatusLeft_DCRL "Front left mirror camera defrost status";
CM_ SG_ 681 windowReqRearLeft_DCRL "Rear-Left window request status";
CM_ SG_ 681 windowReqRearRight_DCRL "Rear-Right window request status";
CM_ SG_ 681 windowReqFrontLeft_DCRL "Front-Left window request status";
CM_ SG_ 681 windowReqFrontRight_DCRL "Front-Right window request status";
CM_ SG_ 712 doorLockReq_DCRR "Rear right door lock request status";
CM_ SG_ 712 mirrorStatusMovUpDownRight_DCRR "Front right mirror up/down movement status";
CM_ SG_ 712 mirrorStatusMovInOutRight_DCRR "Front right mirror inwards/outwards movement status";
CM_ SG_ 712 mirrorDefrostCamStatusRight_DCRR "Front right mirror camera defrost status";
CM_ SG_ 713 windowReqRearLeft_DCRR "Rear-Left window request status";
CM_ SG_ 713 windowReqRearRight_DCRR "Rear-Right window request status";
CM_ SG_ 713 windowReqFrontLeft_DCRR "Front-Left window request status";
CM_ SG_ 713 windowReqFrontRight_DCRR "Front-Right window request status";
CM_ SG_ 1259 lightReverseStatus_LGL "Reverse light status";
CM_ SG_ 1259 lightRearPosLhStatus_LGL "Reverse left position light status";
CM_ SG_ 1259 lightRearPosRhStatus_LGL "Reverse right position light status";
CM_ SG_ 1259 lightStopStatus_LGL "Stop light status";
CM_ SG_ 1273 lightTurnStatus_RCLL "Turn light status";
CM_ SG_ 1273 lightRsmStatus_RCLL "RSM light status";
CM_ SG_ 1273 lightRearPosStatus_RCLL "Rear position light status";
CM_ SG_ 1273 lightCrystalsAmberStatus_RCLL "Amber crystal light status";
CM_ SG_ 1273 lightCrystalsRedStatus_RCLL "Red crystal light status";
CM_ SG_ 1273 lightCrystalsPinkStatus_RCLL "Pink crystal light status";
CM_ SG_ 1273 lightStopStatus_RCLL "Stop light status";
CM_ SG_ 1281 lightTurnStatus_RCLR "Turn light status";
CM_ SG_ 1281 lightRsmStatus_RCLR "RSM light status";
CM_ SG_ 1281 lightRearPosStatus_RCLR "Rear position light status";
CM_ SG_ 1281 lightCrystalsAmberStatus_RCLR "Amber crystal light status";
CM_ SG_ 1281 lightCrystalsRedStatus_RCLR "Red crystal light status";
CM_ SG_ 1281 lightCrystalsPinkStatus_RCLR "Pink crystal light status";
CM_ SG_ 1281 lightStopStatus_RCLR "Stop light status";
CM_ SG_ 1298 lightFrontPosLh_ACCL "Front left position light status";
CM_ SG_ 1298 lightFrontPosRh_ACCL "Front right position light status";
CM_ SG_ 1298 lightDrlLh_ACCL "Left DRL light status";
CM_ SG_ 1298 lightDrlRh_ACCL "Right DRL light status";
CM_ SG_ 1328 doorFLLockReq_DBPC "Lock/Unlock Request";
VAL_ 1088 sequenceIDStatus_HLL 255 "SNA" 254 "Unveil" 253 "ParkedOnStage" 252 "WifiHotspot" 155 "Null" 154 "TurnLeft" 153 "TurnRight" 152 "AutonomousMode" 151 "ParkMode" 150 "DriveMode" 122 "AutoValetParked" 121 "AutoValetParking" 120 "AutoValetCountDown" 104 "ChargingInterrupt" 103 "ChargingUnplugged" 102 "ChargingCompleted" 101 "ChargingInProgress" 100 "ChargerReady" 53 "FollowHome" 52 "WalkAround" 51 "HappyDog" 50 "Awake" 16 "ObstructPassRear" 15 "ObstructPassFront" 14 "ObstructDriverRear" 13 "ObstructDriverFront" 12 "ClosedPassRear" 11 "ClosedPassFront" 10 "ClosedDriverRear" 9 "ClosedDriverFront" 8 "ClosingPassRear" 7 "ClosingPassFront" 6 "ClosingDriverRear" 5 "ClosingDriverFront" 4 "OpenPassRear" 3 "OpenPassFront" 2 "OpenDriverRear" 1 "OpenDriverFront" 0 "NoSequence" ;
VAL_ 1088 sequenceStatus_HLL 3 "SNA" 1 "Running" 0 "NotRunning" ;
VAL_ 1088 lightDrlStatus_HLL 3 "SNA" 2 "LightFault" 1 "LightOn" 0 "LightOff" ;
VAL_ 1088 lightLowBeamStatus_HLL 3 "SNA" 2 "LightFault" 1 "LightOn" 0 "LightOff" ;
VAL_ 1088 lightFrontPosStatus_HLL 3 "SNA" 2 "LightFault" 1 "LightOn" 0 "LightOff" ;
VAL_ 1088 lightHighBeamStatus_HLL 3 "SNA" 2 "LightFault" 1 "LightOn" 0 "LightOff" ;
VAL_ 1088 lightTurnStatus_HLL 3 "SNA" 2 "LightFault" 1 "LightOn" 0 "LightOff" ;
VAL_ 1088 lightCorneringStatus_HLL 3 "SNA" 2 "LightFault" 1 "LightOn" 0 "LightOff" ;
VAL_ 1096 sequenceIDStatus_HLR 255 "SNA" 254 "Unveil" 253 "ParkedOnStage" 252 "WifiHotspot" 155 "Null" 154 "TurnLeft" 153 "TurnRight" 152 "AutonomousMode" 151 "ParkMode" 150 "DriveMode" 122 "AutoValetParked" 121 "AutoValetParking" 120 "AutoValetCountDown" 104 "ChargingInterrupt" 103 "ChargingUnplugged" 102 "ChargingCompleted" 101 "ChargingInProgress" 100 "ChargerReady" 53 "FollowHome" 52 "WalkAround" 51 "HappyDog" 50 "Awake" 16 "ObstructPassRear" 15 "ObstructPassFront" 14 "ObstructDriverRear" 13 "ObstructDriverFront" 12 "ClosedPassRear" 11 "ClosedPassFront" 10 "ClosedDriverRear" 9 "ClosedDriverFront" 8 "ClosingPassRear" 7 "ClosingPassFront" 6 "ClosingDriverRear" 5 "ClosingDriverFront" 4 "OpenPassRear" 3 "OpenPassFront" 2 "OpenDriverRear" 1 "OpenDriverFront" 0 "NoSequence" ;
VAL_ 1096 sequenceStatus_HLR 3 "SNA" 1 "Running" 0 "NotRunning" ;
VAL_ 1096 lightDrlStatus_HLR 3 "SNA" 2 "LightFault" 1 "LightOn" 0 "LightOff" ;
VAL_ 1096 lightLowBeamStatus_HLR 3 "SNA" 2 "LightFault" 1 "LightOn" 0 "LightOff" ;
VAL_ 1096 lightHighBeamStatus_HLR 3 "SNA" 2 "LightFault" 1 "LightOn" 0 "LightOff" ;
VAL_ 1096 lightCorneringStatus_HLR 3 "SNA" 2 "LightFault" 1 "LightOn" 0 "LightOff" ;
VAL_ 1096 lightFrontPosStatus_HLR 3 "SNA" 2 "LightFault" 1 "LightOn" 0 "LightOff" ;
VAL_ 1096 lightTurnStatus_HLR 3 "SNA" 2 "LightFault" 1 "LightOn" 0 "LightOff" ;
VAL_ 1138 seatHeatFanCushFltSts_DSM 3 "SNA" 2 "SeatHeatFltStsPassd" 1 "SeatHeatFltStsFaild" 0 "SeatHeatFltStsNoRes" ;
VAL_ 1138 seatHeatFanBackFltSts_DSM 3 "SNA" 2 "SeatHeatFltStsPassd" 1 "SeatHeatFltStsFaild" 0 "SeatHeatFltStsNoRes" ;
VAL_ 1138 seatCushionHeatFltSts_DSM 3 "SNA" 2 "SeatHeatFltStsPassd" 1 "SeatHeatFltStsFaild" 0 "SeatHeatFltStsNoRes" ;
VAL_ 1138 seatCushionHeatActv_DSM 1 "On" 0 "Off" ;
VAL_ 1138 seatBackrestHeatFltSts_DSM 3 "SNA" 2 "SeatHeatFltStsPassd" 1 "SeatHeatFltStsFaild" 0 "SeatHeatFltStsNoRes" ;
VAL_ 1138 seatBackrestHeatActv_DSM 1 "On" 0 "Off" ;
VAL_ 1139 seatBackPmpFailr_DSM 3 "SNA" 2 "FltStTestFaild" 1 "FltStTestPassd" 0 "FltStNoRes" ;
VAL_ 1139 seatBackCtrlRunng_DSM 3 "PmpAndPnmPmpMotActv" 2 "PmpAndPnmPnmActv" 1 "PmpAndPnmPmpMotAndPnmActv" 0 "PmpAndPnmIdle" ;
VAL_ 1139 seatBackCtrlPnmFailr_DSM 3 "SNA" 2 "FltStTestFaild" 1 "FltStTestPassd" 0 "FltStNoRes" ;
VAL_ 1139 seatBackCtrlInAutMovmt_DSM 1 "True" 0 "False" ;
VAL_ 1148 frunkLockReq_DDP 3 "SNA" 2 "NoChange" 1 "Unlock" 0 "Lock" ;
VAL_ 1148 liftgateLockReq_DDP 3 "SNA" 2 "NoChange" 1 "Unlock" 0 "Lock" ;
VAL_ 1148 doorRRLockReq_DDP 3 "SNA" 2 "NoChange" 1 "Unlock" 0 "Lock" ;
VAL_ 1148 doorRLLockReq_DDP 3 "SNA" 2 "NoChange" 1 "Unlock" 0 "Lock" ;
VAL_ 1148 doorFRLockReq_DDP 3 "SNA" 2 "NoChange" 1 "Unlock" 0 "Lock" ;
VAL_ 1148 doorFLLockReq_DDP 3 "SNA" 2 "NoChange" 1 "Unlock" 0 "Lock" ;
VAL_ 1149 seatCushionSlideReqFL_DDP 3 "SNA" 2 "Increment" 1 "Decrement" 0 "NoCommand" ;
VAL_ 1149 seatLiftReqFL_DDP 3 "SNA" 2 "Increment" 1 "Decrement" 0 "NoCommand" ;
VAL_ 1149 seatCushBlstrAirReqFL_DDP 3 "SNA" 2 "Increment" 1 "Decrement" 0 "NoCommand" ;
VAL_ 1149 seatShldrFwdRwdReqFL_DDP 3 "SNA" 2 "Increment" 1 "Decrement" 0 "NoCommand" ;
VAL_ 1149 seatLumFwdRwdReqFL_DDP 3 "SNA" 2 "Increment" 1 "Decrement" 0 "NoCommand" ;
VAL_ 1149 seatBackBlstrAirReqFL_DDP 3 "SNA" 2 "Increment" 1 "Decrement" 0 "NoCommand" ;
VAL_ 1149 seatBackAngleReqFL_DDP 3 "SNA" 2 "Increment" 1 "Decrement" 0 "NoCommand" ;
VAL_ 1149 seatCushionTiltReqFL_DDP 3 "SNA" 2 "Increment" 1 "Decrement" 0 "NoCommand" ;
VAL_ 1149 seatSlideReqFL_DDP 3 "SNA" 2 "Increment" 1 "Decrement" 0 "NoCommand" ;
VAL_ 1149 seatHeatVentReqFL_DDP 15 "SNA" 7 "Heat3" 6 "Heat2" 5 "Heat1" 4 "Off" 3 "Vent1" 2 "Vent2" 1 "Vent3" 0 "NoCommand" ;
VAL_ 1149 seatLumUpDnReqFL_DDP 3 "SNA" 2 "Increment" 1 "Decrement" 0 "NoCommand" ;
VAL_ 1150 seatMemoryReqFL_DDP 3 "SNA" 2 "SaveNewPos" 1 "GoToSavedPos" 0 "NoCommand" ;
VAL_ 1150 personalAssistantReqFL_DDP 3 "SNA" 2 "Deactivate" 1 "Activate" 0 "NoRequest" ;
VAL_ 1150 volumeRequestFL_DDP 63 "SNA" ;
VAL_ 1150 muteRequestFL_DDP 3 "SNA" 2 "NoCommand" 1 "True" 0 "False" ;
VAL_ 1150 seatRelaxedRequestFL_DDP 3 "SNA" 2 "NoCommand" 1 "True" 0 "False" ;
VAL_ 1150 nBlowerFrontDrive_DDP 15 "SNA" ;
VAL_ 1150 tAirFrontDriveRequest_DDP 255 "SNA" ;
VAL_ 1150 nVentDriveFront_DDP 15 "SNA" 9 "NoCommand" 8 "DefrostVent" 7 "DefrostFoot" 6 "Defrost2" 5 "Defrost1" 4 "TriLevel" 3 "BiLevel" 2 "Foot" 1 "Vent" 0 "SystemOff" ;
VAL_ 1150 nAirConditionAuto_DDP 3 "SNA" 2 "NoCommand" 1 "True" 0 "False" ;
VAL_ 1150 nAirCondition_DDP 3 "SNA" 2 "AcEnabled" 1 "BlowerEnabled" 0 "SystemOff" ;
VAL_ 1170 seatHeatFanCushFltSts_PSM 3 "SNA" 2 "SeatHeatFltStsPassd" 1 "SeatHeatFltStsFaild" 0 "SeatHeatFltStsNoRes" ;
VAL_ 1170 seatHeatFanBackFltSts_PSM 3 "SNA" 2 "SeatHeatFltStsPassd" 1 "SeatHeatFltStsFaild" 0 "SeatHeatFltStsNoRes" ;
VAL_ 1170 seatCushionHeatFltSts_PSM 3 "SNA" 2 "SeatHeatFltStsPassd" 1 "SeatHeatFltStsFaild" 0 "SeatHeatFltStsNoRes" ;
VAL_ 1170 seatCushionHeatActv_PSM 1 "On" 0 "Off" ;
VAL_ 1170 seatBackrestHeatFltSts_PSM 3 "SNA" 2 "SeatHeatFltStsPassd" 1 "SeatHeatFltStsFaild" 0 "SeatHeatFltStsNoRes" ;
VAL_ 1170 seatBackrestHeatActv_PSM 1 "On" 0 "Off" ;
VAL_ 1171 seatBackPmpFailr_PSM 3 "SNA" 2 "FltStTestFaild" 1 "FltStTestPassd" 0 "FltStNoRes" ;
VAL_ 1171 seatBackCtrlRunng_PSM 3 "PmpAndPnmPmpMotActv" 2 "PmpAndPnmPnmActv" 1 "PmpAndPnmPmpMotAndPnmActv" 0 "PmpAndPnmIdle" ;
VAL_ 1171 seatBackCtrlPnmFailr_PSM 3 "SNA" 2 "FltStTestFaild" 1 "FltStTestPassd" 0 "FltStNoRes" ;
VAL_ 1171 seatBackCtrlInAutMovmt_PSM 1 "True" 0 "False" ;
VAL_ 1176 doorFRLockReq_PDP 3 "SNA" 2 "NoChange" 1 "Unlock" 0 "Lock" ;
VAL_ 1181 seatCushionSlideReqFR_PDP 3 "SNA" 2 "Increment" 1 "Decrement" 0 "NoCommand" ;
VAL_ 1181 seatLiftReqFR_PDP 3 "SNA" 2 "Increment" 1 "Decrement" 0 "NoCommand" ;
VAL_ 1181 seatCushBlstrAirReqFR_PDP 3 "SNA" 2 "Increment" 1 "Decrement" 0 "NoCommand" ;
VAL_ 1181 seatShldrFwdRwdReqFR_PDP 3 "SNA" 2 "Increment" 1 "Decrement" 0 "NoCommand" ;
VAL_ 1181 seatLumFwdRwdReqFR_PDP 3 "SNA" 2 "Increment" 1 "Decrement" 0 "NoCommand" ;
VAL_ 1181 seatBackBlstrAirReqFR_PDP 3 "SNA" 2 "Increment" 1 "Decrement" 0 "NoCommand" ;
VAL_ 1181 seatBackAngleReqFR_PDP 3 "SNA" 2 "Increment" 1 "Decrement" 0 "NoCommand" ;
VAL_ 1181 seatCushionTiltReqFR_PDP 3 "SNA" 2 "Increment" 1 "Decrement" 0 "NoCommand" ;
VAL_ 1181 seatSlideReqFR_PDP 3 "SNA" 2 "Increment" 1 "Decrement" 0 "NoCommand" ;
VAL_ 1181 seatHeatVentReqFR_PDP 15 "SNA" 7 "Heat3" 6 "Heat2" 5 "Heat1" 4 "Off" 3 "Vent1" 2 "Vent2" 1 "Vent3" 0 "NoCommand" ;
VAL_ 1181 seatLumUpDnReqFR_PDP 3 "SNA" 2 "Increment" 1 "Decrement" 0 "NoCommand" ;
VAL_ 1182 seatMemoryReqFR_PDP 3 "SNA" 2 "SaveNewPos" 1 "GoToSavedPos" 0 "NoCommand" ;
VAL_ 1182 personalAssistantReqFR_PDP 3 "SNA" 2 "Deactivate" 1 "Activate" 0 "NoRequest" ;
VAL_ 1182 volumeRequestFR_PDP 63 "SNA" ;
VAL_ 1182 muteRequestFR_PDP 3 "SNA" 2 "NoCommand" 1 "True" 0 "False" ;
VAL_ 1182 seatRelaxedRequestFR_PDP 3 "SNA" 2 "NoCommand" 1 "True" 0 "False" ;
VAL_ 1182 nBlowerFrontPass_PDP 15 "SNA" ;
VAL_ 1182 tAirFrontPassRequest_PDP 255 "SNA" ;
VAL_ 1182 nVentPassFront_PDP 15 "SNA" 9 "NoCommand" 8 "DefrostVent" 7 "DefrostFoot" 6 "Defrost2" 5 "Defrost1" 4 "TriLevel" 3 "BiLevel" 2 "Foot" 1 "Vent" 0 "SystemOff" ;
VAL_ 1182 nAirConditionAuto_PDP 3 "SNA" 2 "NoCommand" 1 "True" 0 "False" ;
VAL_ 1182 nAirCondition_PDP 3 "SNA" 2 "AcEnabled" 1 "BlowerEnabled" 0 "SystemOff" ;
VAL_ 680 windowLockState_DCRL 3 "SNA" 2 "Unused" 1 "Locked" 0 "Unlocked" ;
VAL_ 680 doorIsUnlatched_DCRL 3 "SNA" 1 "True" 0 "False" ;
VAL_ 680 doorExtSwitch_DCRL 3 "SNA" 1 "True" 0 "False" ;
VAL_ 680 doorLockReq_DCRL 3 "SNA" 2 "LockRequest" 1 "UnlockRequest" 0 "NoRequest" ;
VAL_ 680 doorMirrorState_DCRL 7 "SNA" 4 "Retracting" 3 "Retracted" 2 "Presenting" 1 "Presented" 0 "Unknown" ;
VAL_ 680 doorState_DCRL 15 "SNA" 9 "DoorUnlatchingError" 8 "DoorClosingError" 7 "DoorOpeningError" 6 "DoorClosingObstruction" 5 "DoorOpeningObstruction" 4 "DoorClosing" 3 "DoorOpening" 2 "DoorUnlatched" 1 "DoorOpen" 0 "DoorClosed" ;
VAL_ 680 mirrorHeaterState_DCRL 3 "SNA" 2 "Fault" 1 "On" 0 "Off" ;
VAL_ 680 sideRepeaterState_DCRL 3 "SNA" 2 "LightFault" 1 "LightOn" 0 "LightOff" ;
VAL_ 680 windowStatusRl_DCRL 7 "SNA" 4 "Error" 3 "WindowRollingDown" 2 "WindowRollingUp" 1 "WindowOpen" 0 "WindowClosed" ;
VAL_ 680 mirrorFoldFeedbackLeft_DCRL 3 "SNA" 2 "FoldIn" 1 "FoldOut" 0 "NoCommand" ;
VAL_ 680 mirrorDefrostGlassStatusLh_DCRL 3 "SNA" 2 "Error" 1 "On" 0 "Off" ;
VAL_ 680 mirrorStatusMovUpDownLeft_DCRL 3 "SNA" 2 "MovingDown" 1 "MovingUp" 0 "NotMoving" ;
VAL_ 680 mirrorStatusMovInOutLeft_DCRL 3 "SNA" 2 "MovingOut" 1 "MovingIn" 0 "NotMoving" ;
VAL_ 680 mirrorDefrostCamStatusLeft_DCRL 3 "SNA" 2 "Error" 1 "On" 0 "Off" ;
VAL_ 681 windowReqRearLeft_DCRL 7 "SNA" 6 "AutoUp" 5 "AutoDown" 2 "PropUp" 1 "PropDown" 0 "NoCommand" ;
VAL_ 681 windowReqRearRight_DCRL 7 "SNA" 6 "AutoUp" 5 "AutoDown" 2 "PropUp" 1 "PropDown" 0 "NoCommand" ;
VAL_ 681 windowReqFrontLeft_DCRL 7 "SNA" 6 "AutoUp" 5 "AutoDown" 2 "PropUp" 1 "PropDown" 0 "NoCommand" ;
VAL_ 681 windowReqFrontRight_DCRL 7 "SNA" 6 "AutoUp" 5 "AutoDown" 2 "PropUp" 1 "PropDown" 0 "NoCommand" ;
VAL_ 1202 seatHeatFanCushFltSts_RLSM 3 "SNA" 2 "SeatHeatFltStsPassd" 1 "SeatHeatFltStsFaild" 0 "SeatHeatFltStsNoRes" ;
VAL_ 1202 seatHeatFanBackFltSts_RLSM 3 "SNA" 2 "SeatHeatFltStsPassd" 1 "SeatHeatFltStsFaild" 0 "SeatHeatFltStsNoRes" ;
VAL_ 1202 seatCushionHeatFltSts_RLSM 3 "SNA" 2 "SeatHeatFltStsPassd" 1 "SeatHeatFltStsFaild" 0 "SeatHeatFltStsNoRes" ;
VAL_ 1202 seatCushionHeatActv_RLSM 1 "On" 0 "Off" ;
VAL_ 1202 seatBackrestHeatFltSts_RLSM 3 "SNA" 2 "SeatHeatFltStsPassd" 1 "SeatHeatFltStsFaild" 0 "SeatHeatFltStsNoRes" ;
VAL_ 1202 seatBackrestHeatActv_RLSM 1 "On" 0 "Off" ;
VAL_ 1203 seatBackPmpFailr_RLSM 3 "SNA" 2 "FltStTestFaild" 1 "FltStTestPassd" 0 "FltStNoRes" ;
VAL_ 1203 seatBackCtrlRunng_RLSM 3 "PmpAndPnmPmpMotActv" 2 "PmpAndPnmPnmActv" 1 "PmpAndPnmPmpMotAndPnmActv" 0 "PmpAndPnmIdle" ;
VAL_ 1203 seatBackCtrlPnmFailr_RLSM 3 "SNA" 2 "FltStTestFaild" 1 "FltStTestPassd" 0 "FltStNoRes" ;
VAL_ 1203 seatBackCtrlInAutMovmt_RLSM 1 "True" 0 "False" ;
VAL_ 1208 doorRLLockReq_RLDP 3 "SNA" 2 "NoChange" 1 "Unlock" 0 "Lock" ;
VAL_ 1213 seatCushionSlideReqRL_RLDP 3 "SNA" 2 "Increment" 1 "Decrement" 0 "NoCommand" ;
VAL_ 1213 seatLegExtensionReqRL_RLDP 3 "SNA" 2 "Increment" 1 "Decrement" 0 "NoCommand" ;
VAL_ 1213 seatShldrFwdRwdReqRL_RLDP 3 "SNA" 2 "Increment" 1 "Decrement" 0 "NoCommand" ;
VAL_ 1213 seatLumFwdRwdRL_RLDP 3 "SNA" 2 "Increment" 1 "Decrement" 0 "NoCommand" ;
VAL_ 1213 seatBackAngleReqRL_RLDP 3 "SNA" 2 "Increment" 1 "Decrement" 0 "NoCommand" ;
VAL_ 1213 seatCushionTiltReqRL_RLDP 3 "SNA" 2 "Increment" 1 "Decrement" 0 "NoCommand" ;
VAL_ 1213 seatLegRestReqRL_RLDP 3 "SNA" 2 "Increment" 1 "Decrement" 0 "NoCommand" ;
VAL_ 1213 seatTiltCmdRL_RLDP 3 "SNA" 2 "Increment" 1 "Decrement" 0 "NoCommand" ;
VAL_ 1213 seatHeatVentReqRL_RLDP 15 "SNA" 7 "Heat3" 6 "Heat2" 5 "Heat1" 4 "Off" 3 "Vent1" 2 "Vent2" 1 "Vent3" 0 "NoCommand" ;
VAL_ 1213 seatLumUpDnReqRL_RLDP 3 "SNA" 2 "Increment" 1 "Decrement" 0 "NoCommand" ;
VAL_ 1214 seatMemoryReqRL_RLDP 3 "SNA" 2 "SaveNewPos" 1 "GoToSavedPos" 0 "NoCommand" ;
VAL_ 1214 personalAssistantReqRL_RLDP 3 "SNA" 2 "Deactivate" 1 "Activate" 0 "NoRequest" ;
VAL_ 1214 volumeRequestRL_RLDP 63 "SNA" ;
VAL_ 1214 muteRequestRL_RLDP 3 "SNA" 2 "NoCommand" 1 "True" 0 "False" ;
VAL_ 1214 seatRelaxedRequestRL_RLDP 3 "SNA" 2 "NoCommand" 1 "True" 0 "False" ;
VAL_ 1214 nBlowerRearDrive_RLDP 15 "SNA" ;
VAL_ 1214 tAirRearDriveRequest_RLDP 255 "SNA" ;
VAL_ 1214 nVentDriveRear_RLDP 15 "SNA" 8 "NoCommand" 7 "CenterFootDoor" 6 "CenterFoot" 5 "CenterDoor" 4 "Center" 3 "FootDoor" 2 "Foot" 1 "Door" 0 "SystemOff" ;
VAL_ 1214 nAirConditionAuto_RLDP 3 "SNA" 2 "NoCommand" 1 "True" 0 "False" ;
VAL_ 1214 nAirCondition_RLDP 3 "SNA" 2 "AcEnabled" 1 "BlowerEnabled" 0 "SystemOff" ;
VAL_ 1214 rsdUpDownReq_RLDP 7 "SNA" 4 "Decrement" 3 "Increment" 2 "Open" 1 "Close" 0 "NoCommand" ;
VAL_ 712 windowLockState_DCRR 3 "SNA" 2 "Unused" 1 "Locked" 0 "Unlocked" ;
VAL_ 712 doorIsUnlatched_DCRR 3 "SNA" 1 "True" 0 "False" ;
VAL_ 712 doorExtSwitch_DCRR 3 "SNA" 1 "True" 0 "False" ;
VAL_ 712 doorLockReq_DCRR 3 "SNA" 2 "LockRequest" 1 "UnlockRequest" 0 "NoRequest" ;
VAL_ 712 doorMirrorState_DCRR 7 "SNA" 4 "Retracting" 3 "Retracted" 2 "Presenting" 1 "Presented" 0 "Unknown" ;
VAL_ 712 doorState_DCRR 15 "SNA" 9 "DoorUnlatchingError" 8 "DoorClosingError" 7 "DoorOpeningError" 6 "DoorClosingObstruction" 5 "DoorOpeningObstruction" 4 "DoorClosing" 3 "DoorOpening" 2 "DoorUnlatched" 1 "DoorOpen" 0 "DoorClosed" ;
VAL_ 712 mirrorHeaterState_DCRR 3 "SNA" 2 "Fault" 1 "On" 0 "Off" ;
VAL_ 712 sideRepeaterState_DCRR 3 "SNA" 2 "LightFault" 1 "LightOn" 0 "LightOff" ;
VAL_ 712 windowStatusRr_DCRR 7 "SNA" 4 "Error" 3 "WindowRollingDown" 2 "WindowRollingUp" 1 "WindowOpen" 0 "WindowClosed" ;
VAL_ 712 mirrorFoldFeedbackRight_DCRR 3 "SNA" 2 "FoldIn" 1 "FoldOut" 0 "NoCommand" ;
VAL_ 712 mirrorDefrostGlassStatusRh_DCRR 3 "SNA" 2 "Error" 1 "On" 0 "Off" ;
VAL_ 712 mirrorStatusMovUpDownRight_DCRR 3 "SNA" 2 "MovingDown" 1 "MovingUp" 0 "NotMoving" ;
VAL_ 712 mirrorStatusMovInOutRight_DCRR 3 "SNA" 2 "MovingOut" 1 "MovingIn" 0 "NotMoving" ;
VAL_ 712 mirrorDefrostCamStatusRight_DCRR 3 "SNA" 2 "Error" 1 "On" 0 "Off" ;
VAL_ 713 windowReqRearLeft_DCRR 7 "SNA" 6 "AutoUp" 5 "AutoDown" 2 "PropUp" 1 "PropDown" 0 "NoCommand" ;
VAL_ 713 windowReqRearRight_DCRR 7 "SNA" 6 "AutoUp" 5 "AutoDown" 2 "PropUp" 1 "PropDown" 0 "NoCommand" ;
VAL_ 713 windowReqFrontLeft_DCRR 7 "SNA" 6 "AutoUp" 5 "AutoDown" 2 "PropUp" 1 "PropDown" 0 "NoCommand" ;
VAL_ 713 windowReqFrontRight_DCRR 7 "SNA" 6 "AutoUp" 5 "AutoDown" 2 "PropUp" 1 "PropDown" 0 "NoCommand" ;
VAL_ 1234 seatHeatFanCushFltSts_RRSM 3 "SNA" 2 "SeatHeatFltStsPassd" 1 "SeatHeatFltStsFaild" 0 "SeatHeatFltStsNoRes" ;
VAL_ 1234 seatHeatFanBackFltSts_RRSM 3 "SNA" 2 "SeatHeatFltStsPassd" 1 "SeatHeatFltStsFaild" 0 "SeatHeatFltStsNoRes" ;
VAL_ 1234 seatCushionHeatFltSts_RRSM 3 "SNA" 2 "SeatHeatFltStsPassd" 1 "SeatHeatFltStsFaild" 0 "SeatHeatFltStsNoRes" ;
VAL_ 1234 seatCushionHeatActv_RRSM 1 "On" 0 "Off" ;
VAL_ 1234 seatBackrestHeatFltSts_RRSM 3 "SNA" 2 "SeatHeatFltStsPassd" 1 "SeatHeatFltStsFaild" 0 "SeatHeatFltStsNoRes" ;
VAL_ 1234 seatBackrestHeatActv_RRSM 1 "On" 0 "Off" ;
VAL_ 1235 seatBackPmpFailr_RRSM 3 "SNA" 2 "FltStTestFaild" 1 "FltStTestPassd" 0 "FltStNoRes" ;
VAL_ 1235 seatBackCtrlRunng_RRSM 3 "PmpAndPnmPmpMotActv" 2 "PmpAndPnmPnmActv" 1 "PmpAndPnmPmpMotAndPnmActv" 0 "PmpAndPnmIdle" ;
VAL_ 1235 seatBackCtrlPnmFailr_RRSM 3 "SNA" 2 "FltStTestFaild" 1 "FltStTestPassd" 0 "FltStNoRes" ;
VAL_ 1235 seatBackCtrlInAutMovmt_RRSM 1 "True" 0 "False" ;
VAL_ 1248 doorRRLockReq_RRDP 3 "SNA" 2 "NoChange" 1 "Unlock" 0 "Lock" ;
VAL_ 1253 seatCushionSlideReqRR_RRDP 3 "SNA" 2 "Increment" 1 "Decrement" 0 "NoCommand" ;
VAL_ 1253 seatLegExtensionReqRR_RRDP 3 "SNA" 2 "Increment" 1 "Decrement" 0 "NoCommand" ;
VAL_ 1253 seatShldrFwdRwdReqRR_RRDP 3 "SNA" 2 "Increment" 1 "Decrement" 0 "NoCommand" ;
VAL_ 1253 seatLumFwdRwdReqRR_RRDP 3 "SNA" 2 "Increment" 1 "Decrement" 0 "NoCommand" ;
VAL_ 1253 seatBackAngleReqRR_RRDP 3 "SNA" 2 "Increment" 1 "Decrement" 0 "NoCommand" ;
VAL_ 1253 seatCushionTiltReqRR_RRDP 3 "SNA" 2 "Increment" 1 "Decrement" 0 "NoCommand" ;
VAL_ 1253 seatLegRestReqRR_RRDP 3 "SNA" 2 "Increment" 1 "Decrement" 0 "NoCommand" ;
VAL_ 1253 seatTiltCmdRR_RRDP 3 "SNA" 2 "Increment" 1 "Decrement" 0 "NoCommand" ;
VAL_ 1253 seatHeatVentReqRR_RRDP 15 "SNA" 7 "Heat3" 6 "Heat2" 5 "Heat1" 4 "Off" 3 "Vent1" 2 "Vent2" 1 "Vent3" 0 "NoCommand" ;
VAL_ 1253 seatLumUpDnReqRR_RRDP 3 "SNA" 2 "Increment" 1 "Decrement" 0 "NoCommand" ;
VAL_ 1254 seatMemoryReqRR_RRDP 3 "SNA" 2 "SaveNewPos" 1 "GoToSavedPos" 0 "NoCommand" ;
VAL_ 1254 personalAssistantReqRR_RRDP 3 "SNA" 2 "Deactivate" 1 "Activate" 0 "NoRequest" ;
VAL_ 1254 volumeRequestRR_RRDP 63 "SNA" ;
VAL_ 1254 muteRequestRR_RRDP 3 "SNA" 2 "NoCommand" 1 "True" 0 "False" ;
VAL_ 1254 seatRelaxedRequestRR_RRDP 3 "SNA" 2 "NoCommand" 1 "True" 0 "False" ;
VAL_ 1254 nBlowerRearPass_RRDP 15 "SNA" ;
VAL_ 1254 tAirRearPassRequest_RRDP 255 "SNA" ;
VAL_ 1254 nVentPassRear_RRDP 15 "SNA" 8 "NoCommand" 7 "CenterFootDoor" 6 "CenterFoot" 5 "CenterDoor" 4 "Center" 3 "FootDoor" 2 "Foot" 1 "Door" 0 "SystemOff" ;
VAL_ 1254 nAirConditionAuto_RRDP 3 "SNA" 2 "NoCommand" 1 "True" 0 "False" ;
VAL_ 1254 nAirCondition_RRDP 3 "SNA" 2 "AcEnabled" 1 "BlowerEnabled" 0 "SystemOff" ;
VAL_ 1254 rsdUpDownReq_RRDP 7 "SNA" 4 "Decrement" 3 "Increment" 2 "Open" 1 "Close" 0 "NoCommand" ;
VAL_ 1259 lightReverseStatus_LGL 3 "SNA" 2 "LightFault" 1 "LightOn" 0 "LightOff" ;
VAL_ 1259 lightRearPosLhStatus_LGL 3 "SNA" 2 "LightFault" 1 "LightOn" 0 "LightOff" ;
VAL_ 1259 lightRearPosRhStatus_LGL 3 "SNA" 2 "LightFault" 1 "LightOn" 0 "LightOff" ;
VAL_ 1259 cHMSLStatus_LGL 3 "SNA" 2 "LightFault" 1 "LightOn" 0 "LightOff" ;
VAL_ 1259 sequenceIDStatus_LGL 255 "SNA" 254 "Unveil" 253 "ParkedOnStage" 252 "WifiHotspot" 155 "Null" 154 "TurnLeft" 153 "TurnRight" 152 "AutonomousMode" 151 "ParkMode" 150 "DriveMode" 122 "AutoValetParked" 121 "AutoValetParking" 120 "AutoValetCountDown" 104 "ChargingInterrupt" 103 "ChargingUnplugged" 102 "ChargingCompleted" 101 "ChargingInProgress" 100 "ChargerReady" 53 "FollowHome" 52 "WalkAround" 51 "HappyDog" 50 "Awake" 16 "ObstructPassRear" 15 "ObstructPassFront" 14 "ObstructDriverRear" 13 "ObstructDriverFront" 12 "ClosedPassRear" 11 "ClosedPassFront" 10 "ClosedDriverRear" 9 "ClosedDriverFront" 8 "ClosingPassRear" 7 "ClosingPassFront" 6 "ClosingDriverRear" 5 "ClosingDriverFront" 4 "OpenPassRear" 3 "OpenPassFront" 2 "OpenDriverRear" 1 "OpenDriverFront" 0 "NoSequence" ;
VAL_ 1259 sequenceStatus_LGL 3 "SNA" 1 "Running" 0 "NotRunning" ;
VAL_ 1259 lightStopStatus_LGL 3 "SNA" 2 "LightFault" 1 "LightOn" 0 "LightOff" ;
VAL_ 1273 sequenceIDStatus_RCLL 255 "SNA" 254 "Unveil" 253 "ParkedOnStage" 252 "WifiHotspot" 155 "Null" 154 "TurnLeft" 153 "TurnRight" 152 "AutonomousMode" 151 "ParkMode" 150 "DriveMode" 122 "AutoValetParked" 121 "AutoValetParking" 120 "AutoValetCountDown" 104 "ChargingInterrupt" 103 "ChargingUnplugged" 102 "ChargingCompleted" 101 "ChargingInProgress" 100 "ChargerReady" 53 "FollowHome" 52 "WalkAround" 51 "HappyDog" 50 "Awake" 16 "ObstructPassRear" 15 "ObstructPassFront" 14 "ObstructDriverRear" 13 "ObstructDriverFront" 12 "ClosedPassRear" 11 "ClosedPassFront" 10 "ClosedDriverRear" 9 "ClosedDriverFront" 8 "ClosingPassRear" 7 "ClosingPassFront" 6 "ClosingDriverRear" 5 "ClosingDriverFront" 4 "OpenPassRear" 3 "OpenPassFront" 2 "OpenDriverRear" 1 "OpenDriverFront" 0 "NoSequence" ;
VAL_ 1273 sequenceStatus_RCLL 3 "SNA" 1 "Running" 0 "NotRunning" ;
VAL_ 1273 lightTurnStatus_RCLL 3 "SNA" 2 "LightFault" 1 "LightOn" 0 "LightOff" ;
VAL_ 1273 lightRsmStatus_RCLL 3 "SNA" 2 "LightFault" 1 "LightOn" 0 "LightOff" ;
VAL_ 1273 lightRearPosStatus_RCLL 3 "SNA" 2 "LightFault" 1 "LightOn" 0 "LightOff" ;
VAL_ 1273 lightCrystalsAmberStatus_RCLL 3 "SNA" 2 "LightFault" 1 "LightOn" 0 "LightOff" ;
VAL_ 1273 lightCrystalsRedStatus_RCLL 3 "SNA" 2 "LightFault" 1 "LightOn" 0 "LightOff" ;
VAL_ 1273 lightCrystalsPinkStatus_RCLL 3 "SNA" 2 "LightFault" 1 "LightOn" 0 "LightOff" ;
VAL_ 1273 lightStopStatus_RCLL 3 "SNA" 2 "LightFault" 1 "LightOn" 0 "LightOff" ;
VAL_ 1281 sequenceIDStatus_RCLR 255 "SNA" 254 "Unveil" 253 "ParkedOnStage" 252 "WifiHotspot" 155 "Null" 154 "TurnLeft" 153 "TurnRight" 152 "AutonomousMode" 151 "ParkMode" 150 "DriveMode" 122 "AutoValetParked" 121 "AutoValetParking" 120 "AutoValetCountDown" 104 "ChargingInterrupt" 103 "ChargingUnplugged" 102 "ChargingCompleted" 101 "ChargingInProgress" 100 "ChargerReady" 53 "FollowHome" 52 "WalkAround" 51 "HappyDog" 50 "Awake" 16 "ObstructPassRear" 15 "ObstructPassFront" 14 "ObstructDriverRear" 13 "ObstructDriverFront" 12 "ClosedPassRear" 11 "ClosedPassFront" 10 "ClosedDriverRear" 9 "ClosedDriverFront" 8 "ClosingPassRear" 7 "ClosingPassFront" 6 "ClosingDriverRear" 5 "ClosingDriverFront" 4 "OpenPassRear" 3 "OpenPassFront" 2 "OpenDriverRear" 1 "OpenDriverFront" 0 "NoSequence" ;
VAL_ 1281 sequenceStatus_RCLR 3 "SNA" 1 "Running" 0 "NotRunning" ;
VAL_ 1281 lightTurnStatus_RCLR 3 "SNA" 2 "LightFault" 1 "LightOn" 0 "LightOff" ;
VAL_ 1281 lightRearPosStatus_RCLR 3 "SNA" 2 "LightFault" 1 "LightOn" 0 "LightOff" ;
VAL_ 1281 lightCrystalsAmberStatus_RCLR 3 "SNA" 2 "LightFault" 1 "LightOn" 0 "LightOff" ;
VAL_ 1281 lightCrystalsRedStatus_RCLR 3 "SNA" 2 "LightFault" 1 "LightOn" 0 "LightOff" ;
VAL_ 1281 lightCrystalsPinkStatus_RCLR 3 "SNA" 2 "LightFault" 1 "LightOn" 0 "LightOff" ;
VAL_ 1281 lightStopStatus_RCLR 3 "SNA" 2 "LightFault" 1 "LightOn" 0 "LightOff" ;
VAL_ 1290 seatDrvgCycStrtdToSeatCptDSM_BGW 1 "Flg1Set" 0 "Flg1Rst" ;
VAL_ 1290 seatHeatFanRampDSM_BGW 1 "SeatHeatFanRampSlowRamp" 0 "SeatHeatFanRampFastRamp" ;
VAL_ 1290 seatHeatFanErrRstDSM_BGW 1 "True" 0 "False" ;
VAL_ 1290 seatCushionHeatPwrLimDSM_BGW 7 "SeatHeatPwrLimTmpOff" 6 "SeatHeatPwrLimPerc20" 5 "SeatHeatPwrLimPerc30" 4 "SeatHeatPwrLimPerc40" 3 "SeatHeatPwrLimPerc50" 2 "SeatHeatPwrLimPerc60" 1 "SeatHeatPwrLimPerc80" 0 "SeatHeatPwrLimFctDeactvd" ;
VAL_ 1290 seatCushionHeatErrRstDSM_BGW 1 "True" 0 "False" ;
VAL_ 1290 seatBackrestHeatPwrLimDSM_BGW 7 "SeatHeatPwrLimTmpOff" 6 "SeatHeatPwrLimPerc20" 5 "SeatHeatPwrLimPerc30" 4 "SeatHeatPwrLimPerc40" 3 "SeatHeatPwrLimPerc50" 2 "SeatHeatPwrLimPerc60" 1 "SeatHeatPwrLimPerc80" 0 "SeatHeatPwrLimFctDeactvd" ;
VAL_ 1290 seatBackrestHeatErrRstDSM_BGW 1 "True" 0 "False" ;
VAL_ 1291 seatDrvgCycStrtdToSeatCptPSM_BGW 1 "Flg1Set" 0 "Flg1Rst" ;
VAL_ 1291 seatHeatFanRampPSM_BGW 1 "SeatHeatFanRampSlowRamp" 0 "SeatHeatFanRampFastRamp" ;
VAL_ 1291 seatHeatFanErrRstPSM_BGW 1 "True" 0 "False" ;
VAL_ 1291 seatCushionHeatPwrLimPSM_BGW 7 "SeatHeatPwrLimTmpOff" 6 "SeatHeatPwrLimPerc20" 5 "SeatHeatPwrLimPerc30" 4 "SeatHeatPwrLimPerc40" 3 "SeatHeatPwrLimPerc50" 2 "SeatHeatPwrLimPerc60" 1 "SeatHeatPwrLimPerc80" 0 "SeatHeatPwrLimFctDeactvd" ;
VAL_ 1291 seatCushionHeatErrRstPSM_BGW 1 "True" 0 "False" ;
VAL_ 1291 seatBackrestHeatPwrLimPSM_BGW 7 "SeatHeatPwrLimTmpOff" 6 "SeatHeatPwrLimPerc20" 5 "SeatHeatPwrLimPerc30" 4 "SeatHeatPwrLimPerc40" 3 "SeatHeatPwrLimPerc50" 2 "SeatHeatPwrLimPerc60" 1 "SeatHeatPwrLimPerc80" 0 "SeatHeatPwrLimFctDeactvd" ;
VAL_ 1291 seatBackrestHeatErrRstPSM_BGW 1 "True" 0 "False" ;
VAL_ 1292 seatDrvgCycStrtdSeatCptRLSM_BGW 1 "Flg1Set" 0 "Flg1Rst" ;
VAL_ 1292 seatBackrestHeatPwrLimRLSM_BGW 7 "SeatHeatPwrLimTmpOff" 6 "SeatHeatPwrLimPerc20" 5 "SeatHeatPwrLimPerc30" 4 "SeatHeatPwrLimPerc40" 3 "SeatHeatPwrLimPerc50" 2 "SeatHeatPwrLimPerc60" 1 "SeatHeatPwrLimPerc80" 0 "SeatHeatPwrLimFctDeactvd" ;
VAL_ 1292 seatBackrestHeatErrRstRLSM_BGW 1 "True" 0 "False" ;
VAL_ 1292 seatHeatFanRampRLSM_BGW 1 "SeatHeatFanRampSlowRamp" 0 "SeatHeatFanRampFastRamp" ;
VAL_ 1292 seatHeatFanErrRstRLSM_BGW 1 "True" 0 "False" ;
VAL_ 1292 seatCushionHeatPwrLimRLSM_BGW 7 "SeatHeatPwrLimTmpOff" 6 "SeatHeatPwrLimPerc20" 5 "SeatHeatPwrLimPerc30" 4 "SeatHeatPwrLimPerc40" 3 "SeatHeatPwrLimPerc50" 2 "SeatHeatPwrLimPerc60" 1 "SeatHeatPwrLimPerc80" 0 "SeatHeatPwrLimFctDeactvd" ;
VAL_ 1292 seatCushionHeatErrRstRLSM_BGW 1 "True" 0 "False" ;
VAL_ 1293 seatBackrestHeatPwrLimRRSM_BGW 7 "SeatHeatPwrLimTmpOff" 6 "SeatHeatPwrLimPerc20" 5 "SeatHeatPwrLimPerc30" 4 "SeatHeatPwrLimPerc40" 3 "SeatHeatPwrLimPerc50" 2 "SeatHeatPwrLimPerc60" 1 "SeatHeatPwrLimPerc80" 0 "SeatHeatPwrLimFctDeactvd" ;
VAL_ 1293 seatBackrestHeatErrRstRRSM_BGW 1 "True" 0 "False" ;
VAL_ 1293 seatDrvgCycStrtdSeatCptRRSM_BGW 1 "Flg1Set" 0 "Flg1Rst" ;
VAL_ 1293 seatHeatFanRampRRSM_BGW 1 "SeatHeatFanRampSlowRamp" 0 "SeatHeatFanRampFastRamp" ;
VAL_ 1293 seatHeatFanErrRstRRSM_BGW 1 "True" 0 "False" ;
VAL_ 1293 seatCushionHeatPwrLimRRSM_BGW 7 "SeatHeatPwrLimTmpOff" 6 "SeatHeatPwrLimPerc20" 5 "SeatHeatPwrLimPerc30" 4 "SeatHeatPwrLimPerc40" 3 "SeatHeatPwrLimPerc50" 2 "SeatHeatPwrLimPerc60" 1 "SeatHeatPwrLimPerc80" 0 "SeatHeatPwrLimFctDeactvd" ;
VAL_ 1293 seatCushionHeatErrRstRRSM_BGW 1 "True" 0 "False" ;
VAL_ 1294 seatShIncRLSM_BGW 1 "True" 0 "False" ;
VAL_ 1294 seatShDecRLSM_BGW 1 "True" 0 "False" ;
VAL_ 1294 seatLumUpRLSM_BGW 1 "True" 0 "False" ;
VAL_ 1294 seatLumIncRLSM_BGW 1 "True" 0 "False" ;
VAL_ 1294 seatLumDwnRLSM_BGW 1 "True" 0 "False" ;
VAL_ 1294 seatLumDecRLSM_BGW 1 "True" 0 "False" ;
VAL_ 1294 seatCushIncRLSM_BGW 1 "True" 0 "False" ;
VAL_ 1294 seatCushDecRLSM_BGW 1 "True" 0 "False" ;
VAL_ 1294 seatBackSaveSetToMemRLSM_BGW 3 "SNA" 2 "Aut" 1 "On" 0 "Off" ;
VAL_ 1294 seatBackPosnStoreRLSM_BGW 1 "True" 0 "False" ;
VAL_ 1294 seatBackPosnRestoreRLSM_BGW 1 "True" 0 "False" ;
VAL_ 1294 seatBackCtrReqInOutEasyRLSM_BGW 1 "On" 0 "Off" ;
VAL_ 1294 seatBackBlstrIncRLSM_BGW 1 "True" 0 "False" ;
VAL_ 1294 seatBackBlstrDecRLSM_BGW 1 "True" 0 "False" ;
VAL_ 1294 seatPmpRunRLSM_BGW 1 "True" 0 "False" ;
VAL_ 1294 seatMemSeatCtrlRLSM_BGW 3 "MemPosnMemBnk3" 2 "MemPosnMemBnk2" 1 "MemPosnMemBnk1" 0 "MemPosnProfPosn" ;
VAL_ 1294 seatMassgReqOnOffRLSM_BGW 1 "On" 0 "Off" ;
VAL_ 1294 seatMassgReqMassgSpdLvlRLSM_BGW 3 "SNA" 2 "MassgIntenLvlIntenHi" 1 "MassgIntenLvlIntenNorm" 0 "MassgIntenLvlIntenLo" ;
VAL_ 1294 seatMassgReqMassgProgRLSM_BGW 15 "Test" 14 "JounceDownCush" 13 "JounceDownBack" 12 "JounceDownSeat" 11 "JounceUpCush" 10 "JounceUpBack" 9 "JounceUpSeat" 8 "JounceUpDownCush" 7 "JounceUpDownBack" 6 "JounceUpDownSeat" 5 "RollUpDownCush" 4 "RollUpDownBack" 3 "RollUpDownSeat" 2 "RollUpCush" 1 "RollUpBack" 0 "RollUpSeat" ;
VAL_ 1294 seatMassgReqMassgIntenRLSM_BGW 3 "SNA" 2 "MassgIntenLvlIntenHi" 1 "MassgIntenLvlIntenNorm" 0 "MassgIntenLvlIntenLo" ;
VAL_ 1294 seatIndVlvCtrlRLSM_BGW 1 "True" 0 "False" ;
VAL_ 1294 seatEmgyStopRLSM_BGW 1 "True" 0 "False" ;
VAL_ 1294 seatDiAutCorrnRLSM_BGW 1 "True" 0 "False" ;
VAL_ 1295 seatShIncRRSM_BGW 1 "True" 0 "False" ;
VAL_ 1295 seatShDecRRSM_BGW 1 "True" 0 "False" ;
VAL_ 1295 seatLumUpRRSM_BGW 1 "True" 0 "False" ;
VAL_ 1295 seatLumIncRRSM_BGW 1 "True" 0 "False" ;
VAL_ 1295 seatLumDwnRRSM_BGW 1 "True" 0 "False" ;
VAL_ 1295 seatLumDecRRSM_BGW 1 "True" 0 "False" ;
VAL_ 1295 seatCushIncRRSM_BGW 1 "True" 0 "False" ;
VAL_ 1295 seatCushDecRRSM_BGW 1 "True" 0 "False" ;
VAL_ 1295 seatBackSaveSetToMemRRSM_BGW 3 "SNA" 2 "Aut" 1 "On" 0 "Off" ;
VAL_ 1295 seatBackPosnStoreRRSM_BGW 1 "True" 0 "False" ;
VAL_ 1295 seatBackPosnRestoreRRSM_BGW 1 "True" 0 "False" ;
VAL_ 1295 seatBackCtrReqInOutEasyRRSM_BGW 1 "On" 0 "Off" ;
VAL_ 1295 seatBackBlstrIncRRSM_BGW 1 "True" 0 "False" ;
VAL_ 1295 seatBackBlstrDecRRSM_BGW 1 "True" 0 "False" ;
VAL_ 1295 seatPmpRunRRSM_BGW 1 "True" 0 "False" ;
VAL_ 1295 seatMemSeatCtrlRRSM_BGW 3 "MemPosnMemBnk3" 2 "MemPosnMemBnk2" 1 "MemPosnMemBnk1" 0 "MemPosnProfPosn" ;
VAL_ 1295 seatMassgReqOnOffRRSM_BGW 1 "On" 0 "Off" ;
VAL_ 1295 seatMassgReqMassgSpdLvlRRSM_BGW 3 "SNA" 2 "MassgIntenLvlIntenHi" 1 "MassgIntenLvlIntenNorm" 0 "MassgIntenLvlIntenLo" ;
VAL_ 1295 seatMassgReqMassgProgRRSM_BGW 15 "Test" 14 "JounceDownCush" 13 "JounceDownBack" 12 "JounceDownSeat" 11 "JounceUpCush" 10 "JounceUpBack" 9 "JounceUpSeat" 8 "JounceUpDownCush" 7 "JounceUpDownBack" 6 "JounceUpDownSeat" 5 "RollUpDownCush" 4 "RollUpDownBack" 3 "RollUpDownSeat" 2 "RollUpCush" 1 "RollUpBack" 0 "RollUpSeat" ;
VAL_ 1295 seatMassgReqMassgIntenRRSM_BGW 3 "SNA" 2 "MassgIntenLvlIntenHi" 1 "MassgIntenLvlIntenNorm" 0 "MassgIntenLvlIntenLo" ;
VAL_ 1295 seatIndVlvCtrlRRSM_BGW 1 "True" 0 "False" ;
VAL_ 1295 seatEmgyStopRRSM_BGW 1 "True" 0 "False" ;
VAL_ 1295 seatDiAutCorrnRRSM_BGW 1 "True" 0 "False" ;
VAL_ 1298 sequenceIDStatus_ACCL 255 "SNA" 254 "Unveil" 253 "ParkedOnStage" 252 "WifiHotspot" 155 "Null" 154 "TurnLeft" 153 "TurnRight" 152 "AutonomousMode" 151 "ParkMode" 150 "DriveMode" 122 "AutoValetParked" 121 "AutoValetParking" 120 "AutoValetCountDown" 104 "ChargingInterrupt" 103 "ChargingUnplugged" 102 "ChargingCompleted" 101 "ChargingInProgress" 100 "ChargerReady" 53 "FollowHome" 52 "WalkAround" 51 "HappyDog" 50 "Awake" 16 "ObstructPassRear" 15 "ObstructPassFront" 14 "ObstructDriverRear" 13 "ObstructDriverFront" 12 "ClosedPassRear" 11 "ClosedPassFront" 10 "ClosedDriverRear" 9 "ClosedDriverFront" 8 "ClosingPassRear" 7 "ClosingPassFront" 6 "ClosingDriverRear" 5 "ClosingDriverFront" 4 "OpenPassRear" 3 "OpenPassFront" 2 "OpenDriverRear" 1 "OpenDriverFront" 0 "NoSequence" ;
VAL_ 1298 sequenceStatus_ACCL 3 "SNA" 1 "Running" 0 "NotRunning" ;
VAL_ 1298 lightFrontPosLh_ACCL 3 "SNA" 2 "LightFault" 1 "LightOn" 0 "LightOff" ;
VAL_ 1298 lightFrontPosRh_ACCL 3 "SNA" 2 "LightFault" 1 "LightOn" 0 "LightOff" ;
VAL_ 1298 lightDrlLh_ACCL 3 "SNA" 2 "LightFault" 1 "LightOn" 0 "LightOff" ;
VAL_ 1298 lightDrlRh_ACCL 3 "SNA" 2 "LightFault" 1 "LightOn" 0 "LightOff" ;
VAL_ 1328 frunkLockReq_DBPC 3 "SNA" 2 "NoChange" 1 "Unlock" 0 "Lock" ;
VAL_ 1328 liftgateLockReq_DBPC 3 "SNA" 2 "NoChange" 1 "Unlock" 0 "Lock" ;
VAL_ 1328 doorRRLockReq_DBPC 3 "SNA" 2 "NoChange" 1 "Unlock" 0 "Lock" ;
VAL_ 1328 doorRLLockReq_DBPC 3 "SNA" 2 "NoChange" 1 "Unlock" 0 "Lock" ;
VAL_ 1328 doorFRLockReq_DBPC 3 "SNA" 2 "NoChange" 1 "Unlock" 0 "Lock" ;
VAL_ 1328 doorFLLockReq_DBPC 3 "SNA" 2 "NoChange" 1 "Unlock" 0 "Lock" ;
VAL_ 1328 chargerOpenCmd_DBPC 3 "SNA" 2 "NoCommand" 1 "True" 0 "False" ;
VAL_ 1328 chargerReleaseCmd_DBPC 3 "SNA" 2 "NoCommand" 1 "True" 0 "False" ;
VAL_ 1328 autoValetStartCmd_DBPC 3 "SNA" 2 "NoCommand" 1 "True" 0 "False" ;
VAL_ 1336 frunkLockReq_PBPC 3 "SNA" 2 "NoChange" 1 "Unlock" 0 "Lock" ;
VAL_ 1336 liftgateLockReq_PBPC 3 "SNA" 2 "NoChange" 1 "Unlock" 0 "Lock" ;
VAL_ 1336 doorRRLockReq_PBPC 3 "SNA" 2 "NoChange" 1 "Unlock" 0 "Lock" ;
VAL_ 1336 doorRLLockReq_PBPC 3 "SNA" 2 "NoChange" 1 "Unlock" 0 "Lock" ;
VAL_ 1336 doorFRLockReq_PBPC 3 "SNA" 2 "NoChange" 1 "Unlock" 0 "Lock" ;
VAL_ 1336 doorFLLockReq_PBPC 3 "SNA" 2 "NoChange" 1 "Unlock" 0 "Lock" ;
VAL_ 1336 chargerOpenCmd_PBPC 3 "SNA" 2 "NoCommand" 1 "True" 0 "False" ;
VAL_ 1336 chargerReleaseCmd_PBPC 3 "SNA" 2 "NoCommand" 1 "True" 0 "False" ;
VAL_ 1336 autoValetStartCmd_PBPC 3 "SNA" 2 "NoCommand" 1 "True" 0 "False" ;
VAL_ 1344 sequenceStatus_FFL 3 "SNA" 1 "Running" 0 "NotRunning" ;
VAL_ 1344 sequenceIDStatus_FFL 255 "SNA" 99 "Alarm" 98 "Unlock" 97 "Lock" 92 "Custom" 91 "RgbYellow" 90 "RgbRed" 89 "RgbBlue" 87 "RgbWhite" 56 "ObstructionRearRight" 55 "ObstructionRearLeft" 54 "ObstructionFrontRight" 53 "ObstructionFrontLeft" 52 "OpeningLhFrontAndRear" 51 "OpeningRhFrontAndRear" 47 "Hazard" 46 "Sleep" 45 "FollowHome" 44 "HappyDog" 43 "Awake" 42 "ChargingInterrupt" 41 "ChargingComplete" 40 "ChargingUnplugged" 39 "ChargingInProgress" 38 "ChargerReady" 34 "LatchedRearRight" 33 "LatchedFrontRight" 32 "LatchedRearLeft" 31 "LatchedFrontLeft" 30 "OpenRearRight" 29 "OpenFrontRight" 28 "OpenRearLeft" 27 "OpenFrontLeft" 26 "ClosingRearRight" 25 "ClosingFrontRight" 24 "ClosingRearLeft" 23 "ClosingFrontLeft" 22 "OpeningRearRight" 21 "OpeningFrontRight" 20 "OpeningRearLeft" 19 "OpeningFrontLeft" 18 "AutoValetComplete" 17 "AutoValetInProgress" 16 "AutoValetCountdown" 15 "Neutral" 14 "Reverse" 13 "AutoMode" 12 "Park" 11 "Drive" 10 "Test10" 9 "Test9" 8 "Test8" 7 "Test7" 6 "Test6" 5 "Test5" 4 "Test4" 3 "Test3" 2 "Test2" 1 "Test1" 0 "Null" ;
VAL_ 1352 sequenceStatus_FLDC 3 "SNA" 1 "Running" 0 "NotRunning" ;
VAL_ 1352 sequenceIDStatus_FLDC 255 "SNA" 99 "Alarm" 98 "Unlock" 97 "Lock" 92 "Custom" 91 "RgbYellow" 90 "RgbRed" 89 "RgbBlue" 87 "RgbWhite" 56 "ObstructionRearRight" 55 "ObstructionRearLeft" 54 "ObstructionFrontRight" 53 "ObstructionFrontLeft" 52 "OpeningLhFrontAndRear" 51 "OpeningRhFrontAndRear" 47 "Hazard" 46 "Sleep" 45 "FollowHome" 44 "HappyDog" 43 "Awake" 42 "ChargingInterrupt" 41 "ChargingComplete" 40 "ChargingUnplugged" 39 "ChargingInProgress" 38 "ChargerReady" 34 "LatchedRearRight" 33 "LatchedFrontRight" 32 "LatchedRearLeft" 31 "LatchedFrontLeft" 30 "OpenRearRight" 29 "OpenFrontRight" 28 "OpenRearLeft" 27 "OpenFrontLeft" 26 "ClosingRearRight" 25 "ClosingFrontRight" 24 "ClosingRearLeft" 23 "ClosingFrontLeft" 22 "OpeningRearRight" 21 "OpeningFrontRight" 20 "OpeningRearLeft" 19 "OpeningFrontLeft" 18 "AutoValetComplete" 17 "AutoValetInProgress" 16 "AutoValetCountdown" 15 "Neutral" 14 "Reverse" 13 "AutoMode" 12 "Park" 11 "Drive" 10 "Test10" 9 "Test9" 8 "Test8" 7 "Test7" 6 "Test6" 5 "Test5" 4 "Test4" 3 "Test3" 2 "Test2" 1 "Test1" 0 "Null" ;
VAL_ 1360 sequenceStatus_FRDC 3 "SNA" 1 "Running" 0 "NotRunning" ;
VAL_ 1360 sequenceIDStatus_FRDC 255 "SNA" 99 "Alarm" 98 "Unlock" 97 "Lock" 92 "Custom" 91 "RgbYellow" 90 "RgbRed" 89 "RgbBlue" 87 "RgbWhite" 56 "ObstructionRearRight" 55 "ObstructionRearLeft" 54 "ObstructionFrontRight" 53 "ObstructionFrontLeft" 52 "OpeningLhFrontAndRear" 51 "OpeningRhFrontAndRear" 47 "Hazard" 46 "Sleep" 45 "FollowHome" 44 "HappyDog" 43 "Awake" 42 "ChargingInterrupt" 41 "ChargingComplete" 40 "ChargingUnplugged" 39 "ChargingInProgress" 38 "ChargerReady" 34 "LatchedRearRight" 33 "LatchedFrontRight" 32 "LatchedRearLeft" 31 "LatchedFrontLeft" 30 "OpenRearRight" 29 "OpenFrontRight" 28 "OpenRearLeft" 27 "OpenFrontLeft" 26 "ClosingRearRight" 25 "ClosingFrontRight" 24 "ClosingRearLeft" 23 "ClosingFrontLeft" 22 "OpeningRearRight" 21 "OpeningFrontRight" 20 "OpeningRearLeft" 19 "OpeningFrontLeft" 18 "AutoValetComplete" 17 "AutoValetInProgress" 16 "AutoValetCountdown" 15 "Neutral" 14 "Reverse" 13 "AutoMode" 12 "Park" 11 "Drive" 10 "Test10" 9 "Test9" 8 "Test8" 7 "Test7" 6 "Test6" 5 "Test5" 4 "Test4" 3 "Test3" 2 "Test2" 1 "Test1" 0 "Null" ;
VAL_ 1368 sequenceStatus_RLDC 3 "SNA" 1 "Running" 0 "NotRunning" ;
VAL_ 1368 sequenceIDStatus_RLDC 255 "SNA" 99 "Alarm" 98 "Unlock" 97 "Lock" 92 "Custom" 91 "RgbYellow" 90 "RgbRed" 89 "RgbBlue" 87 "RgbWhite" 56 "ObstructionRearRight" 55 "ObstructionRearLeft" 54 "ObstructionFrontRight" 53 "ObstructionFrontLeft" 52 "OpeningLhFrontAndRear" 51 "OpeningRhFrontAndRear" 47 "Hazard" 46 "Sleep" 45 "FollowHome" 44 "HappyDog" 43 "Awake" 42 "ChargingInterrupt" 41 "ChargingComplete" 40 "ChargingUnplugged" 39 "ChargingInProgress" 38 "ChargerReady" 34 "LatchedRearRight" 33 "LatchedFrontRight" 32 "LatchedRearLeft" 31 "LatchedFrontLeft" 30 "OpenRearRight" 29 "OpenFrontRight" 28 "OpenRearLeft" 27 "OpenFrontLeft" 26 "ClosingRearRight" 25 "ClosingFrontRight" 24 "ClosingRearLeft" 23 "ClosingFrontLeft" 22 "OpeningRearRight" 21 "OpeningFrontRight" 20 "OpeningRearLeft" 19 "OpeningFrontLeft" 18 "AutoValetComplete" 17 "AutoValetInProgress" 16 "AutoValetCountdown" 15 "Neutral" 14 "Reverse" 13 "AutoMode" 12 "Park" 11 "Drive" 10 "Test10" 9 "Test9" 8 "Test8" 7 "Test7" 6 "Test6" 5 "Test5" 4 "Test4" 3 "Test3" 2 "Test2" 1 "Test1" 0 "Null" ;
VAL_ 1376 sequenceStatus_RRDC 3 "SNA" 1 "Running" 0 "NotRunning" ;
VAL_ 1376 sequenceIDStatus_RRDC 255 "SNA" 99 "Alarm" 98 "Unlock" 97 "Lock" 92 "Custom" 91 "RgbYellow" 90 "RgbRed" 89 "RgbBlue" 87 "RgbWhite" 56 "ObstructionRearRight" 55 "ObstructionRearLeft" 54 "ObstructionFrontRight" 53 "ObstructionFrontLeft" 52 "OpeningLhFrontAndRear" 51 "OpeningRhFrontAndRear" 47 "Hazard" 46 "Sleep" 45 "FollowHome" 44 "HappyDog" 43 "Awake" 42 "ChargingInterrupt" 41 "ChargingComplete" 40 "ChargingUnplugged" 39 "ChargingInProgress" 38 "ChargerReady" 34 "LatchedRearRight" 33 "LatchedFrontRight" 32 "LatchedRearLeft" 31 "LatchedFrontLeft" 30 "OpenRearRight" 29 "OpenFrontRight" 28 "OpenRearLeft" 27 "OpenFrontLeft" 26 "ClosingRearRight" 25 "ClosingFrontRight" 24 "ClosingRearLeft" 23 "ClosingFrontLeft" 22 "OpeningRearRight" 21 "OpeningFrontRight" 20 "OpeningRearLeft" 19 "OpeningFrontLeft" 18 "AutoValetComplete" 17 "AutoValetInProgress" 16 "AutoValetCountdown" 15 "Neutral" 14 "Reverse" 13 "AutoMode" 12 "Park" 11 "Drive" 10 "Test10" 9 "Test9" 8 "Test8" 7 "Test7" 6 "Test6" 5 "Test5" 4 "Test4" 3 "Test3" 2 "Test2" 1 "Test1" 0 "Null" ;
VAL_ 1546 bootloaderStuckSignal_BGW 255 "SNA" 18 "EcuSpecificReason3" 17 "EcuSpecificReason2" 16 "EcuSpecificReason1" 15 "Reserved12" 14 "Reserved11" 13 "Reserved10" 12 "Reserved9" 11 "Reserved8" 10 "Reserved7" 9 "Reserved6" 8 "Reserved5" 7 "Reserved4" 6 "Reserved3" 5 "Reserved2" 4 "Reserved1" 3 "BootloaderSelfCheckFail" 2 "ApplicationCrcfail" 1 "ApplicationNotPresent" 0 "NormalStartup" ;
VAL_ 1546 resetCause_BGW 255 "SNA" 18 "EcuSpecificReason3" 17 "EcuSpecificReason2" 16 "EcuSpecificReason1" 15 "Reserved10" 14 "Reserved9" 13 "Reserved8" 12 "Reserved7" 11 "Reserved6" 10 "Reserved5" 9 "Reserved4" 8 "Reserved3" 7 "Reserved2" 6 "Reserved1" 5 "SoftwareException" 4 "UdsResetRequest" 3 "PowerMonitor" 2 "WatchdogTimer" 1 "WakeSignal" 0 "NormalWakeCanOrRtc" ;
VAL_ 1554 bootloaderStuckSignal_FBCM 255 "SNA" 18 "EcuSpecificReason3" 17 "EcuSpecificReason2" 16 "EcuSpecificReason1" 15 "Reserved12" 14 "Reserved11" 13 "Reserved10" 12 "Reserved9" 11 "Reserved8" 10 "Reserved7" 9 "Reserved6" 8 "Reserved5" 7 "Reserved4" 6 "Reserved3" 5 "Reserved2" 4 "Reserved1" 3 "BootloaderSelfCheckFail" 2 "ApplicationCrcfail" 1 "ApplicationNotPresent" 0 "NormalStartup" ;
VAL_ 1554 resetCause_FBCM 255 "SNA" 18 "EcuSpecificReason3" 17 "EcuSpecificReason2" 16 "EcuSpecificReason1" 15 "Reserved10" 14 "Reserved9" 13 "Reserved8" 12 "Reserved7" 11 "Reserved6" 10 "Reserved5" 9 "Reserved4" 8 "Reserved3" 7 "Reserved2" 6 "Reserved1" 5 "SoftwareException" 4 "UdsResetRequest" 3 "PowerMonitor" 2 "WatchdogTimer" 1 "WakeSignal" 0 "NormalWakeCanOrRtc" ;
VAL_ 1570 bootloaderStuckSignal_RBCM 255 "SNA" 18 "EcuSpecificReason3" 17 "EcuSpecificReason2" 16 "EcuSpecificReason1" 15 "Reserved12" 14 "Reserved11" 13 "Reserved10" 12 "Reserved9" 11 "Reserved8" 10 "Reserved7" 9 "Reserved6" 8 "Reserved5" 7 "Reserved4" 6 "Reserved3" 5 "Reserved2" 4 "Reserved1" 3 "BootloaderSelfCheckFail" 2 "ApplicationCrcfail" 1 "ApplicationNotPresent" 0 "NormalStartup" ;
VAL_ 1570 resetCause_RBCM 255 "SNA" 18 "EcuSpecificReason3" 17 "EcuSpecificReason2" 16 "EcuSpecificReason1" 15 "Reserved10" 14 "Reserved9" 13 "Reserved8" 12 "Reserved7" 11 "Reserved6" 10 "Reserved5" 9 "Reserved4" 8 "Reserved3" 7 "Reserved2" 6 "Reserved1" 5 "SoftwareException" 4 "UdsResetRequest" 3 "PowerMonitor" 2 "WatchdogTimer" 1 "WakeSignal" 0 "NormalWakeCanOrRtc" ;
VAL_ 1602 bootloaderStuckSignal_HLL 255 "SNA" 18 "EcuSpecificReason3" 17 "EcuSpecificReason2" 16 "EcuSpecificReason1" 15 "Reserved12" 14 "Reserved11" 13 "Reserved10" 12 "Reserved9" 11 "Reserved8" 10 "Reserved7" 9 "Reserved6" 8 "Reserved5" 7 "Reserved4" 6 "Reserved3" 5 "Reserved2" 4 "Reserved1" 3 "BootloaderSelfCheckFail" 2 "ApplicationCrcfail" 1 "ApplicationNotPresent" 0 "NormalStartup" ;
VAL_ 1602 resetCause_HLL 255 "SNA" 18 "EcuSpecificReason3" 17 "EcuSpecificReason2" 16 "EcuSpecificReason1" 15 "Reserved10" 14 "Reserved9" 13 "Reserved8" 12 "Reserved7" 11 "Reserved6" 10 "Reserved5" 9 "Reserved4" 8 "Reserved3" 7 "Reserved2" 6 "Reserved1" 5 "SoftwareException" 4 "UdsResetRequest" 3 "PowerMonitor" 2 "WatchdogTimer" 1 "WakeSignal" 0 "NormalWakeCanOrRtc" ;
VAL_ 1610 bootloaderStuckSignal_HLR 255 "SNA" 18 "EcuSpecificReason3" 17 "EcuSpecificReason2" 16 "EcuSpecificReason1" 15 "Reserved12" 14 "Reserved11" 13 "Reserved10" 12 "Reserved9" 11 "Reserved8" 10 "Reserved7" 9 "Reserved6" 8 "Reserved5" 7 "Reserved4" 6 "Reserved3" 5 "Reserved2" 4 "Reserved1" 3 "BootloaderSelfCheckFail" 2 "ApplicationCrcfail" 1 "ApplicationNotPresent" 0 "NormalStartup" ;
VAL_ 1610 resetCause_HLR 255 "SNA" 18 "EcuSpecificReason3" 17 "EcuSpecificReason2" 16 "EcuSpecificReason1" 15 "Reserved10" 14 "Reserved9" 13 "Reserved8" 12 "Reserved7" 11 "Reserved6" 10 "Reserved5" 9 "Reserved4" 8 "Reserved3" 7 "Reserved2" 6 "Reserved1" 5 "SoftwareException" 4 "UdsResetRequest" 3 "PowerMonitor" 2 "WatchdogTimer" 1 "WakeSignal" 0 "NormalWakeCanOrRtc" ;
VAL_ 1634 bootloaderStuckSignal_DCFL 255 "SNA" 18 "EcuSpecificReason3" 17 "EcuSpecificReason2" 16 "EcuSpecificReason1" 15 "Reserved12" 14 "Reserved11" 13 "Reserved10" 12 "Reserved9" 11 "Reserved8" 10 "Reserved7" 9 "Reserved6" 8 "Reserved5" 7 "Reserved4" 6 "Reserved3" 5 "Reserved2" 4 "Reserved1" 3 "BootloaderSelfCheckFail" 2 "ApplicationCrcfail" 1 "ApplicationNotPresent" 0 "NormalStartup" ;
VAL_ 1634 resetCause_DCFL 255 "SNA" 18 "EcuSpecificReason3" 17 "EcuSpecificReason2" 16 "EcuSpecificReason1" 15 "Reserved10" 14 "Reserved9" 13 "Reserved8" 12 "Reserved7" 11 "Reserved6" 10 "Reserved5" 9 "Reserved4" 8 "Reserved3" 7 "Reserved2" 6 "Reserved1" 5 "SoftwareException" 4 "UdsResetRequest" 3 "PowerMonitor" 2 "WatchdogTimer" 1 "WakeSignal" 0 "NormalWakeCanOrRtc" ;
VAL_ 1650 resetCause_DSM 255 "SNA" 18 "EcuSpecificReason3" 17 "EcuSpecificReason2" 16 "EcuSpecificReason1" 15 "Reserved10" 14 "Reserved9" 13 "Reserved8" 12 "Reserved7" 11 "Reserved6" 10 "Reserved5" 9 "Reserved4" 8 "Reserved3" 7 "Reserved2" 6 "Reserved1" 5 "SoftwareException" 4 "UdsResetRequest" 3 "PowerMonitor" 2 "WatchdogTimer" 1 "WakeSignal" 0 "NormalWakeCanOrRtc" ;
VAL_ 1650 bootloaderStuckSignal_DSM 255 "SNA" 18 "EcuSpecificReason3" 17 "EcuSpecificReason2" 16 "EcuSpecificReason1" 15 "Reserved12" 14 "Reserved11" 13 "Reserved10" 12 "Reserved9" 11 "Reserved8" 10 "Reserved7" 9 "Reserved6" 8 "Reserved5" 7 "Reserved4" 6 "Reserved3" 5 "Reserved2" 4 "Reserved1" 3 "BootloaderSelfCheckFail" 2 "ApplicationCrcfail" 1 "ApplicationNotPresent" 0 "NormalStartup" ;
VAL_ 1658 bootloaderStuckSignal_DDP 255 "SNA" 18 "EcuSpecificReason3" 17 "EcuSpecificReason2" 16 "EcuSpecificReason1" 15 "Reserved12" 14 "Reserved11" 13 "Reserved10" 12 "Reserved9" 11 "Reserved8" 10 "Reserved7" 9 "Reserved6" 8 "Reserved5" 7 "Reserved4" 6 "Reserved3" 5 "Reserved2" 4 "Reserved1" 3 "BootloaderSelfCheckFail" 2 "ApplicationCrcfail" 1 "ApplicationNotPresent" 0 "NormalStartup" ;
VAL_ 1658 resetCause_DDP 255 "SNA" 18 "EcuSpecificReason3" 17 "EcuSpecificReason2" 16 "EcuSpecificReason1" 15 "Reserved10" 14 "Reserved9" 13 "Reserved8" 12 "Reserved7" 11 "Reserved6" 10 "Reserved5" 9 "Reserved4" 8 "Reserved3" 7 "Reserved2" 6 "Reserved1" 5 "SoftwareException" 4 "UdsResetRequest" 3 "PowerMonitor" 2 "WatchdogTimer" 1 "WakeSignal" 0 "NormalWakeCanOrRtc" ;
VAL_ 1674 bootloaderStuckSignal_DCFR 255 "SNA" 18 "EcuSpecificReason3" 17 "EcuSpecificReason2" 16 "EcuSpecificReason1" 15 "Reserved12" 14 "Reserved11" 13 "Reserved10" 12 "Reserved9" 11 "Reserved8" 10 "Reserved7" 9 "Reserved6" 8 "Reserved5" 7 "Reserved4" 6 "Reserved3" 5 "Reserved2" 4 "Reserved1" 3 "BootloaderSelfCheckFail" 2 "ApplicationCrcfail" 1 "ApplicationNotPresent" 0 "NormalStartup" ;
VAL_ 1674 resetCause_DCFR 255 "SNA" 18 "EcuSpecificReason3" 17 "EcuSpecificReason2" 16 "EcuSpecificReason1" 15 "Reserved10" 14 "Reserved9" 13 "Reserved8" 12 "Reserved7" 11 "Reserved6" 10 "Reserved5" 9 "Reserved4" 8 "Reserved3" 7 "Reserved2" 6 "Reserved1" 5 "SoftwareException" 4 "UdsResetRequest" 3 "PowerMonitor" 2 "WatchdogTimer" 1 "WakeSignal" 0 "NormalWakeCanOrRtc" ;
VAL_ 1682 resetCause_PSM 255 "SNA" 18 "EcuSpecificReason3" 17 "EcuSpecificReason2" 16 "EcuSpecificReason1" 15 "Reserved10" 14 "Reserved9" 13 "Reserved8" 12 "Reserved7" 11 "Reserved6" 10 "Reserved5" 9 "Reserved4" 8 "Reserved3" 7 "Reserved2" 6 "Reserved1" 5 "SoftwareException" 4 "UdsResetRequest" 3 "PowerMonitor" 2 "WatchdogTimer" 1 "WakeSignal" 0 "NormalWakeCanOrRtc" ;
VAL_ 1682 bootloaderStuckSignal_PSM 255 "SNA" 18 "EcuSpecificReason3" 17 "EcuSpecificReason2" 16 "EcuSpecificReason1" 15 "Reserved12" 14 "Reserved11" 13 "Reserved10" 12 "Reserved9" 11 "Reserved8" 10 "Reserved7" 9 "Reserved6" 8 "Reserved5" 7 "Reserved4" 6 "Reserved3" 5 "Reserved2" 4 "Reserved1" 3 "BootloaderSelfCheckFail" 2 "ApplicationCrcfail" 1 "ApplicationNotPresent" 0 "NormalStartup" ;
VAL_ 1690 bootloaderStuckSignal_PDP 255 "SNA" 18 "EcuSpecificReason3" 17 "EcuSpecificReason2" 16 "EcuSpecificReason1" 15 "Reserved12" 14 "Reserved11" 13 "Reserved10" 12 "Reserved9" 11 "Reserved8" 10 "Reserved7" 9 "Reserved6" 8 "Reserved5" 7 "Reserved4" 6 "Reserved3" 5 "Reserved2" 4 "Reserved1" 3 "BootloaderSelfCheckFail" 2 "ApplicationCrcfail" 1 "ApplicationNotPresent" 0 "NormalStartup" ;
VAL_ 1690 resetCause_PDP 255 "SNA" 18 "EcuSpecificReason3" 17 "EcuSpecificReason2" 16 "EcuSpecificReason1" 15 "Reserved10" 14 "Reserved9" 13 "Reserved8" 12 "Reserved7" 11 "Reserved6" 10 "Reserved5" 9 "Reserved4" 8 "Reserved3" 7 "Reserved2" 6 "Reserved1" 5 "SoftwareException" 4 "UdsResetRequest" 3 "PowerMonitor" 2 "WatchdogTimer" 1 "WakeSignal" 0 "NormalWakeCanOrRtc" ;
VAL_ 1706 bootloaderStuckSignal_DCRL 255 "SNA" 18 "EcuSpecificReason3" 17 "EcuSpecificReason2" 16 "EcuSpecificReason1" 15 "Reserved12" 14 "Reserved11" 13 "Reserved10" 12 "Reserved9" 11 "Reserved8" 10 "Reserved7" 9 "Reserved6" 8 "Reserved5" 7 "Reserved4" 6 "Reserved3" 5 "Reserved2" 4 "Reserved1" 3 "BootloaderSelfCheckFail" 2 "ApplicationCrcfail" 1 "ApplicationNotPresent" 0 "NormalStartup" ;
VAL_ 1706 resetCause_DCRL 255 "SNA" 18 "EcuSpecificReason3" 17 "EcuSpecificReason2" 16 "EcuSpecificReason1" 15 "Reserved10" 14 "Reserved9" 13 "Reserved8" 12 "Reserved7" 11 "Reserved6" 10 "Reserved5" 9 "Reserved4" 8 "Reserved3" 7 "Reserved2" 6 "Reserved1" 5 "SoftwareException" 4 "UdsResetRequest" 3 "PowerMonitor" 2 "WatchdogTimer" 1 "WakeSignal" 0 "NormalWakeCanOrRtc" ;
VAL_ 1714 resetCause_RLSM 255 "SNA" 18 "EcuSpecificReason3" 17 "EcuSpecificReason2" 16 "EcuSpecificReason1" 15 "Reserved10" 14 "Reserved9" 13 "Reserved8" 12 "Reserved7" 11 "Reserved6" 10 "Reserved5" 9 "Reserved4" 8 "Reserved3" 7 "Reserved2" 6 "Reserved1" 5 "SoftwareException" 4 "UdsResetRequest" 3 "PowerMonitor" 2 "WatchdogTimer" 1 "WakeSignal" 0 "NormalWakeCanOrRtc" ;
VAL_ 1714 bootloaderStuckSignal_RLSM 255 "SNA" 18 "EcuSpecificReason3" 17 "EcuSpecificReason2" 16 "EcuSpecificReason1" 15 "Reserved12" 14 "Reserved11" 13 "Reserved10" 12 "Reserved9" 11 "Reserved8" 10 "Reserved7" 9 "Reserved6" 8 "Reserved5" 7 "Reserved4" 6 "Reserved3" 5 "Reserved2" 4 "Reserved1" 3 "BootloaderSelfCheckFail" 2 "ApplicationCrcfail" 1 "ApplicationNotPresent" 0 "NormalStartup" ;
VAL_ 1722 bootloaderStuckSignal_RLDP 255 "SNA" 18 "EcuSpecificReason3" 17 "EcuSpecificReason2" 16 "EcuSpecificReason1" 15 "Reserved12" 14 "Reserved11" 13 "Reserved10" 12 "Reserved9" 11 "Reserved8" 10 "Reserved7" 9 "Reserved6" 8 "Reserved5" 7 "Reserved4" 6 "Reserved3" 5 "Reserved2" 4 "Reserved1" 3 "BootloaderSelfCheckFail" 2 "ApplicationCrcfail" 1 "ApplicationNotPresent" 0 "NormalStartup" ;
VAL_ 1722 resetCause_RLDP 255 "SNA" 18 "EcuSpecificReason3" 17 "EcuSpecificReason2" 16 "EcuSpecificReason1" 15 "Reserved10" 14 "Reserved9" 13 "Reserved8" 12 "Reserved7" 11 "Reserved6" 10 "Reserved5" 9 "Reserved4" 8 "Reserved3" 7 "Reserved2" 6 "Reserved1" 5 "SoftwareException" 4 "UdsResetRequest" 3 "PowerMonitor" 2 "WatchdogTimer" 1 "WakeSignal" 0 "NormalWakeCanOrRtc" ;
VAL_ 1738 bootloaderStuckSignal_DCRR 255 "SNA" 18 "EcuSpecificReason3" 17 "EcuSpecificReason2" 16 "EcuSpecificReason1" 15 "Reserved12" 14 "Reserved11" 13 "Reserved10" 12 "Reserved9" 11 "Reserved8" 10 "Reserved7" 9 "Reserved6" 8 "Reserved5" 7 "Reserved4" 6 "Reserved3" 5 "Reserved2" 4 "Reserved1" 3 "BootloaderSelfCheckFail" 2 "ApplicationCrcfail" 1 "ApplicationNotPresent" 0 "NormalStartup" ;
VAL_ 1738 resetCause_DCRR 255 "SNA" 18 "EcuSpecificReason3" 17 "EcuSpecificReason2" 16 "EcuSpecificReason1" 15 "Reserved10" 14 "Reserved9" 13 "Reserved8" 12 "Reserved7" 11 "Reserved6" 10 "Reserved5" 9 "Reserved4" 8 "Reserved3" 7 "Reserved2" 6 "Reserved1" 5 "SoftwareException" 4 "UdsResetRequest" 3 "PowerMonitor" 2 "WatchdogTimer" 1 "WakeSignal" 0 "NormalWakeCanOrRtc" ;
VAL_ 1746 resetCause_RRSM 255 "SNA" 18 "EcuSpecificReason3" 17 "EcuSpecificReason2" 16 "EcuSpecificReason1" 15 "Reserved10" 14 "Reserved9" 13 "Reserved8" 12 "Reserved7" 11 "Reserved6" 10 "Reserved5" 9 "Reserved4" 8 "Reserved3" 7 "Reserved2" 6 "Reserved1" 5 "SoftwareException" 4 "UdsResetRequest" 3 "PowerMonitor" 2 "WatchdogTimer" 1 "WakeSignal" 0 "NormalWakeCanOrRtc" ;
VAL_ 1746 bootloaderStuckSignal_RRSM 255 "SNA" 18 "EcuSpecificReason3" 17 "EcuSpecificReason2" 16 "EcuSpecificReason1" 15 "Reserved12" 14 "Reserved11" 13 "Reserved10" 12 "Reserved9" 11 "Reserved8" 10 "Reserved7" 9 "Reserved6" 8 "Reserved5" 7 "Reserved4" 6 "Reserved3" 5 "Reserved2" 4 "Reserved1" 3 "BootloaderSelfCheckFail" 2 "ApplicationCrcfail" 1 "ApplicationNotPresent" 0 "NormalStartup" ;
VAL_ 1762 bootloaderStuckSignal_RRDP 255 "SNA" 18 "EcuSpecificReason3" 17 "EcuSpecificReason2" 16 "EcuSpecificReason1" 15 "Reserved12" 14 "Reserved11" 13 "Reserved10" 12 "Reserved9" 11 "Reserved8" 10 "Reserved7" 9 "Reserved6" 8 "Reserved5" 7 "Reserved4" 6 "Reserved3" 5 "Reserved2" 4 "Reserved1" 3 "BootloaderSelfCheckFail" 2 "ApplicationCrcfail" 1 "ApplicationNotPresent" 0 "NormalStartup" ;
VAL_ 1762 resetCause_RRDP 255 "SNA" 18 "EcuSpecificReason3" 17 "EcuSpecificReason2" 16 "EcuSpecificReason1" 15 "Reserved10" 14 "Reserved9" 13 "Reserved8" 12 "Reserved7" 11 "Reserved6" 10 "Reserved5" 9 "Reserved4" 8 "Reserved3" 7 "Reserved2" 6 "Reserved1" 5 "SoftwareException" 4 "UdsResetRequest" 3 "PowerMonitor" 2 "WatchdogTimer" 1 "WakeSignal" 0 "NormalWakeCanOrRtc" ;
VAL_ 1826 bootloaderStuckSignal_ECPM 255 "SNA" 18 "EcuSpecificReason3" 17 "EcuSpecificReason2" 16 "EcuSpecificReason1" 15 "Reserved12" 14 "Reserved11" 13 "Reserved10" 12 "Reserved9" 11 "Reserved8" 10 "Reserved7" 9 "Reserved6" 8 "Reserved5" 7 "Reserved4" 6 "Reserved3" 5 "Reserved2" 4 "Reserved1" 3 "BootloaderSelfCheckFail" 2 "ApplicationCrcfail" 1 "ApplicationNotPresent" 0 "NormalStartup" ;
VAL_ 1826 resetCause_ECPM 255 "SNA" 18 "EcuSpecificReason3" 17 "EcuSpecificReason2" 16 "EcuSpecificReason1" 15 "Reserved10" 14 "Reserved9" 13 "Reserved8" 12 "Reserved7" 11 "Reserved6" 10 "Reserved5" 9 "Reserved4" 8 "Reserved3" 7 "Reserved2" 6 "Reserved1" 5 "SoftwareException" 4 "UdsResetRequest" 3 "PowerMonitor" 2 "WatchdogTimer" 1 "WakeSignal" 0 "NormalWakeCanOrRtc" ;
VAL_ 1842 bootloaderStuckSignal_DBPC 255 "SNA" 18 "EcuSpecificReason3" 17 "EcuSpecificReason2" 16 "EcuSpecificReason1" 15 "Reserved12" 14 "Reserved11" 13 "Reserved10" 12 "Reserved9" 11 "Reserved8" 10 "Reserved7" 9 "Reserved6" 8 "Reserved5" 7 "Reserved4" 6 "Reserved3" 5 "Reserved2" 4 "Reserved1" 3 "BootloaderSelfCheckFail" 2 "ApplicationCrcfail" 1 "ApplicationNotPresent" 0 "NormalStartup" ;
VAL_ 1842 resetCause_DBPC 255 "SNA" 18 "EcuSpecificReason3" 17 "EcuSpecificReason2" 16 "EcuSpecificReason1" 15 "Reserved10" 14 "Reserved9" 13 "Reserved8" 12 "Reserved7" 11 "Reserved6" 10 "Reserved5" 9 "Reserved4" 8 "Reserved3" 7 "Reserved2" 6 "Reserved1" 5 "SoftwareException" 4 "UdsResetRequest" 3 "PowerMonitor" 2 "WatchdogTimer" 1 "WakeSignal" 0 "NormalWakeCanOrRtc" ;
VAL_ 1850 bootloaderStuckSignal_PBPC 255 "SNA" 18 "EcuSpecificReason3" 17 "EcuSpecificReason2" 16 "EcuSpecificReason1" 15 "Reserved12" 14 "Reserved11" 13 "Reserved10" 12 "Reserved9" 11 "Reserved8" 10 "Reserved7" 9 "Reserved6" 8 "Reserved5" 7 "Reserved4" 6 "Reserved3" 5 "Reserved2" 4 "Reserved1" 3 "BootloaderSelfCheckFail" 2 "ApplicationCrcfail" 1 "ApplicationNotPresent" 0 "NormalStartup" ;
VAL_ 1850 resetCause_PBPC 255 "SNA" 18 "EcuSpecificReason3" 17 "EcuSpecificReason2" 16 "EcuSpecificReason1" 15 "Reserved10" 14 "Reserved9" 13 "Reserved8" 12 "Reserved7" 11 "Reserved6" 10 "Reserved5" 9 "Reserved4" 8 "Reserved3" 7 "Reserved2" 6 "Reserved1" 5 "SoftwareException" 4 "UdsResetRequest" 3 "PowerMonitor" 2 "WatchdogTimer" 1 "WakeSignal" 0 "NormalWakeCanOrRtc" ;
VAL_ 1858 bootloaderStuckSignal_FFL 255 "SNA" 18 "EcuSpecificReason3" 17 "EcuSpecificReason2" 16 "EcuSpecificReason1" 15 "Reserved12" 14 "Reserved11" 13 "Reserved10" 12 "Reserved9" 11 "Reserved8" 10 "Reserved7" 9 "Reserved6" 8 "Reserved5" 7 "Reserved4" 6 "Reserved3" 5 "Reserved2" 4 "Reserved1" 3 "BootloaderSelfCheckFail" 2 "ApplicationCrcfail" 1 "ApplicationNotPresent" 0 "NormalStartup" ;
VAL_ 1858 resetCause_FFL 255 "SNA" 18 "EcuSpecificReason3" 17 "EcuSpecificReason2" 16 "EcuSpecificReason1" 15 "Reserved10" 14 "Reserved9" 13 "Reserved8" 12 "Reserved7" 11 "Reserved6" 10 "Reserved5" 9 "Reserved4" 8 "Reserved3" 7 "Reserved2" 6 "Reserved1" 5 "SoftwareException" 4 "UdsResetRequest" 3 "PowerMonitor" 2 "WatchdogTimer" 1 "WakeSignal" 0 "NormalWakeCanOrRtc" ;
VAL_ 1866 bootloaderStuckSignal_FLDC 255 "SNA" 18 "EcuSpecificReason3" 17 "EcuSpecificReason2" 16 "EcuSpecificReason1" 15 "Reserved12" 14 "Reserved11" 13 "Reserved10" 12 "Reserved9" 11 "Reserved8" 10 "Reserved7" 9 "Reserved6" 8 "Reserved5" 7 "Reserved4" 6 "Reserved3" 5 "Reserved2" 4 "Reserved1" 3 "BootloaderSelfCheckFail" 2 "ApplicationCrcfail" 1 "ApplicationNotPresent" 0 "NormalStartup" ;
VAL_ 1866 resetCause_FLDC 255 "SNA" 18 "EcuSpecificReason3" 17 "EcuSpecificReason2" 16 "EcuSpecificReason1" 15 "Reserved10" 14 "Reserved9" 13 "Reserved8" 12 "Reserved7" 11 "Reserved6" 10 "Reserved5" 9 "Reserved4" 8 "Reserved3" 7 "Reserved2" 6 "Reserved1" 5 "SoftwareException" 4 "UdsResetRequest" 3 "PowerMonitor" 2 "WatchdogTimer" 1 "WakeSignal" 0 "NormalWakeCanOrRtc" ;
VAL_ 1874 bootloaderStuckSignal_FRDC 255 "SNA" 18 "EcuSpecificReason3" 17 "EcuSpecificReason2" 16 "EcuSpecificReason1" 15 "Reserved12" 14 "Reserved11" 13 "Reserved10" 12 "Reserved9" 11 "Reserved8" 10 "Reserved7" 9 "Reserved6" 8 "Reserved5" 7 "Reserved4" 6 "Reserved3" 5 "Reserved2" 4 "Reserved1" 3 "BootloaderSelfCheckFail" 2 "ApplicationCrcfail" 1 "ApplicationNotPresent" 0 "NormalStartup" ;
VAL_ 1874 resetCause_FRDC 255 "SNA" 18 "EcuSpecificReason3" 17 "EcuSpecificReason2" 16 "EcuSpecificReason1" 15 "Reserved10" 14 "Reserved9" 13 "Reserved8" 12 "Reserved7" 11 "Reserved6" 10 "Reserved5" 9 "Reserved4" 8 "Reserved3" 7 "Reserved2" 6 "Reserved1" 5 "SoftwareException" 4 "UdsResetRequest" 3 "PowerMonitor" 2 "WatchdogTimer" 1 "WakeSignal" 0 "NormalWakeCanOrRtc" ;
VAL_ 1882 bootloaderStuckSignal_RLDC 255 "SNA" 18 "EcuSpecificReason3" 17 "EcuSpecificReason2" 16 "EcuSpecificReason1" 15 "Reserved12" 14 "Reserved11" 13 "Reserved10" 12 "Reserved9" 11 "Reserved8" 10 "Reserved7" 9 "Reserved6" 8 "Reserved5" 7 "Reserved4" 6 "Reserved3" 5 "Reserved2" 4 "Reserved1" 3 "BootloaderSelfCheckFail" 2 "ApplicationCrcfail" 1 "ApplicationNotPresent" 0 "NormalStartup" ;
VAL_ 1882 resetCause_RLDC 255 "SNA" 18 "EcuSpecificReason3" 17 "EcuSpecificReason2" 16 "EcuSpecificReason1" 15 "Reserved10" 14 "Reserved9" 13 "Reserved8" 12 "Reserved7" 11 "Reserved6" 10 "Reserved5" 9 "Reserved4" 8 "Reserved3" 7 "Reserved2" 6 "Reserved1" 5 "SoftwareException" 4 "UdsResetRequest" 3 "PowerMonitor" 2 "WatchdogTimer" 1 "WakeSignal" 0 "NormalWakeCanOrRtc" ;
VAL_ 1890 bootloaderStuckSignal_RRDC 255 "SNA" 18 "EcuSpecificReason3" 17 "EcuSpecificReason2" 16 "EcuSpecificReason1" 15 "Reserved12" 14 "Reserved11" 13 "Reserved10" 12 "Reserved9" 11 "Reserved8" 10 "Reserved7" 9 "Reserved6" 8 "Reserved5" 7 "Reserved4" 6 "Reserved3" 5 "Reserved2" 4 "Reserved1" 3 "BootloaderSelfCheckFail" 2 "ApplicationCrcfail" 1 "ApplicationNotPresent" 0 "NormalStartup" ;
VAL_ 1890 resetCause_RRDC 255 "SNA" 18 "EcuSpecificReason3" 17 "EcuSpecificReason2" 16 "EcuSpecificReason1" 15 "Reserved10" 14 "Reserved9" 13 "Reserved8" 12 "Reserved7" 11 "Reserved6" 10 "Reserved5" 9 "Reserved4" 8 "Reserved3" 7 "Reserved2" 6 "Reserved1" 5 "SoftwareException" 4 "UdsResetRequest" 3 "PowerMonitor" 2 "WatchdogTimer" 1 "WakeSignal" 0 "NormalWakeCanOrRtc" ;
